[part 3 of 3: packages /ComponentTypes to /PortInterfaces]
AUTOSAR XML (schema 4-2-2)
package /ComponentTypes  (continued)
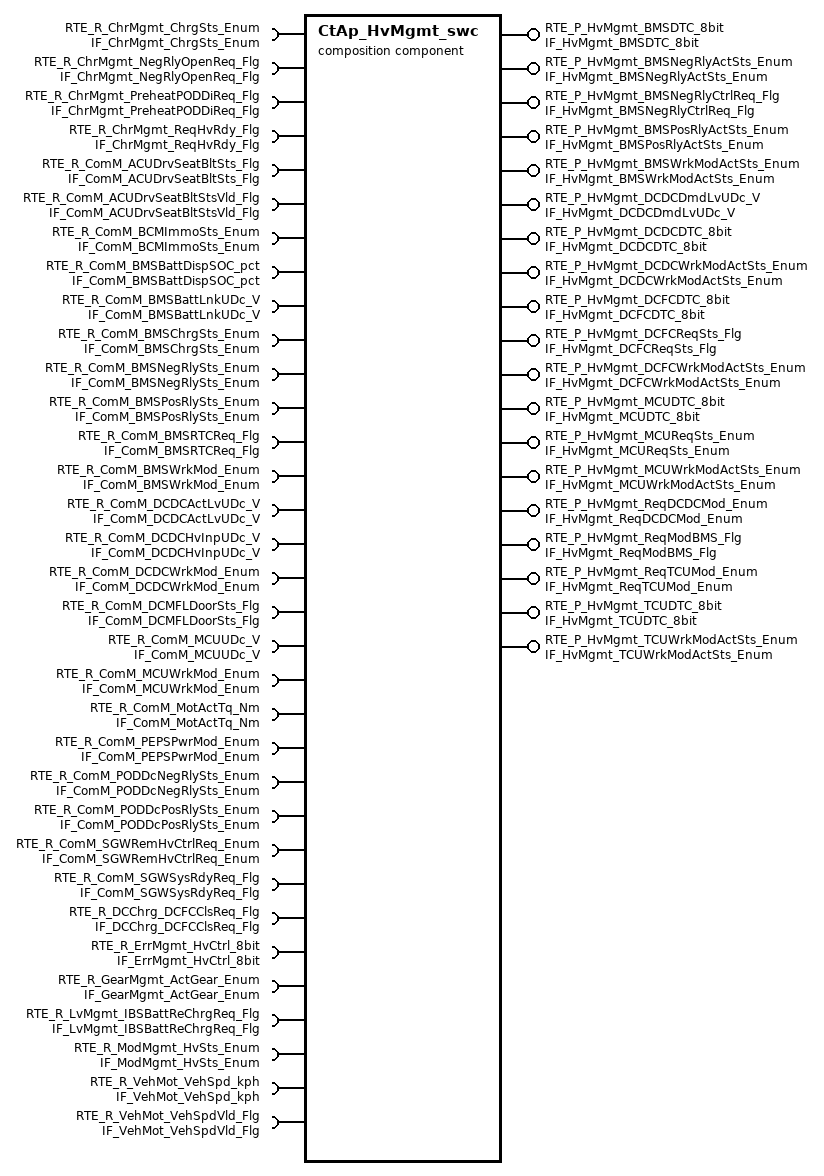
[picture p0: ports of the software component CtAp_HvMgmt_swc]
  composition sw component type CtAp_HvMgmt_swc
    19 x provide port:
      RTE_P_HvMgmt_BMSDTC_8bit: nonqueued-sender-com-spec=data-element=tec_HvMgmt_BMSDTC_8bit, provided-interface=IF_HvMgmt_BMSDTC_8bit
      RTE_P_HvMgmt_BMSNegRlyActSts_Enum: nonqueued-sender-com-spec=data-element=tec_HvMgmt_BMSNegRlyActSts_Enum, provided-interface=IF_HvMgmt_BMSNegRlyActSts_Enum
      RTE_P_HvMgmt_BMSNegRlyCtrlReq_Flg: nonqueued-sender-com-spec=data-element=tec_HvMgmt_BMSNegRlyCtrlReq_Flg, provided-interface=IF_HvMgmt_BMSNegRlyCtrlReq_Flg
      RTE_P_HvMgmt_BMSPosRlyActSts_Enum: nonqueued-sender-com-spec=data-element=tec_HvMgmt_BMSPosRlyActSts_Enum, provided-interface=IF_HvMgmt_BMSPosRlyActSts_Enum
      RTE_P_HvMgmt_BMSWrkModActSts_Enum: nonqueued-sender-com-spec=data-element=tec_HvMgmt_BMSWrkModActSts_Enum, provided-interface=IF_HvMgmt_BMSWrkModActSts_Enum
      RTE_P_HvMgmt_DCDCDmdLvUDc_V: nonqueued-sender-com-spec=data-element=tec_HvMgmt_DCDCDmdLvUDc_V, provided-interface=IF_HvMgmt_DCDCDmdLvUDc_V
      RTE_P_HvMgmt_DCDCDTC_8bit: nonqueued-sender-com-spec=data-element=tec_HvMgmt_DCDCDTC_8bit, provided-interface=IF_HvMgmt_DCDCDTC_8bit
      RTE_P_HvMgmt_DCDCWrkModActSts_Enum: nonqueued-sender-com-spec=data-element=tec_HvMgmt_DCDCWrkModActSts_Enum, provided-interface=IF_HvMgmt_DCDCWrkModActSts_Enum
      RTE_P_HvMgmt_DCFCDTC_8bit: nonqueued-sender-com-spec=data-element=tec_HvMgmt_DCFCDTC_8bit, provided-interface=IF_HvMgmt_DCFCDTC_8bit
      RTE_P_HvMgmt_DCFCReqSts_Flg: nonqueued-sender-com-spec=data-element=tec_HvMgmt_DCFCReqSts_Flg, provided-interface=IF_HvMgmt_DCFCReqSts_Flg
      RTE_P_HvMgmt_DCFCWrkModActSts_Enum: nonqueued-sender-com-spec=data-element=tec_HvMgmt_DCFCWrkModActSts_Enum, provided-interface=IF_HvMgmt_DCFCWrkModActSts_Enum
      RTE_P_HvMgmt_MCUDTC_8bit: nonqueued-sender-com-spec=data-element=tec_HvMgmt_MCUDTC_8bit, provided-interface=IF_HvMgmt_MCUDTC_8bit
      RTE_P_HvMgmt_MCUReqSts_Enum: nonqueued-sender-com-spec=data-element=tec_HvMgmt_MCUReqSts_Enum, provided-interface=IF_HvMgmt_MCUReqSts_Enum
      RTE_P_HvMgmt_MCUWrkModActSts_Enum: nonqueued-sender-com-spec=data-element=tec_HvMgmt_MCUWrkModActSts_Enum, provided-interface=IF_HvMgmt_MCUWrkModActSts_Enum
      RTE_P_HvMgmt_ReqDCDCMod_Enum: nonqueued-sender-com-spec=data-element=tec_HvMgmt_ReqDCDCMod_Enum, provided-interface=IF_HvMgmt_ReqDCDCMod_Enum
      RTE_P_HvMgmt_ReqModBMS_Flg: nonqueued-sender-com-spec=data-element=tec_HvMgmt_ReqModBMS_Flg, provided-interface=IF_HvMgmt_ReqModBMS_Flg
      RTE_P_HvMgmt_ReqTCUMod_Enum: nonqueued-sender-com-spec=data-element=tec_HvMgmt_ReqTCUMod_Enum, provided-interface=IF_HvMgmt_ReqTCUMod_Enum
      RTE_P_HvMgmt_TCUDTC_8bit: nonqueued-sender-com-spec=data-element=tec_HvMgmt_TCUDTC_8bit, provided-interface=IF_HvMgmt_TCUDTC_8bit
      RTE_P_HvMgmt_TCUWrkModActSts_Enum: nonqueued-sender-com-spec=data-element=tec_HvMgmt_TCUWrkModActSts_Enum, provided-interface=IF_HvMgmt_TCUWrkModActSts_Enum
    33 x require port:
      RTE_R_ChrMgmt_ChrgSts_Enum: nonqueued-receiver-com-spec{data-element=tec_ChrMgmt_ChrgSts_Enum, filter=data-filter-type=ALWAYS}, required-interface=IF_ChrMgmt_ChrgSts_Enum
      RTE_R_ChrMgmt_NegRlyOpenReq_Flg: nonqueued-receiver-com-spec{data-element=tec_ChrMgmt_NegRlyOpenReq_Flg, filter=data-filter-type=ALWAYS}, required-interface=IF_ChrMgmt_NegRlyOpenReq_Flg
      RTE_R_ChrMgmt_PreheatPODDiReq_Flg: nonqueued-receiver-com-spec{data-element=tec_ChrMgmt_PreheatPODDiReq_Flg, filter=data-filter-type=ALWAYS}, required-interface=IF_ChrMgmt_PreheatPODDiReq_Flg
      RTE_R_ChrMgmt_ReqHvRdy_Flg: nonqueued-receiver-com-spec{data-element=tec_ChrMgmt_ReqHvRdy_Flg, filter=data-filter-type=ALWAYS}, required-interface=IF_ChrMgmt_ReqHvRdy_Flg
      RTE_R_ComM_ACUDrvSeatBltSts_Flg: nonqueued-receiver-com-spec{data-element=tec_ComM_ACUDrvSeatBltSts_Flg, filter=data-filter-type=ALWAYS}, required-interface=IF_ComM_ACUDrvSeatBltSts_Flg
      RTE_R_ComM_ACUDrvSeatBltStsVld_Flg: nonqueued-receiver-com-spec{data-element=tec_ComM_ACUDrvSeatBltStsVld_Flg, filter=data-filter-type=ALWAYS}, required-interface=IF_ComM_ACUDrvSeatBltStsVld_Flg
      RTE_R_ComM_BCMImmoSts_Enum: nonqueued-receiver-com-spec{data-element=tec_ComM_BCMImmoSts_Enum, filter=data-filter-type=ALWAYS}, required-interface=IF_ComM_BCMImmoSts_Enum
      RTE_R_ComM_BMSBattDispSOC_pct: nonqueued-receiver-com-spec{data-element=tec_ComM_BMSBattDispSOC_pct, filter=data-filter-type=ALWAYS}, required-interface=IF_ComM_BMSBattDispSOC_pct
      RTE_R_ComM_BMSBattLnkUDc_V: nonqueued-receiver-com-spec{data-element=tec_ComM_BMSBattLnkUDc_V, filter=data-filter-type=ALWAYS}, required-interface=IF_ComM_BMSBattLnkUDc_V
      RTE_R_ComM_BMSChrgSts_Enum: nonqueued-receiver-com-spec{data-element=tec_ComM_BMSChrgSts_Enum, filter=data-filter-type=ALWAYS}, required-interface=IF_ComM_BMSChrgSts_Enum
      RTE_R_ComM_BMSNegRlySts_Enum: nonqueued-receiver-com-spec{data-element=tec_ComM_BMSNegRlySts_Enum, filter=data-filter-type=ALWAYS}, required-interface=IF_ComM_BMSNegRlySts_Enum
      RTE_R_ComM_BMSPosRlySts_Enum: nonqueued-receiver-com-spec{data-element=tec_ComM_BMSPosRlySts_Enum, filter=data-filter-type=ALWAYS}, required-interface=IF_ComM_BMSPosRlySts_Enum
      RTE_R_ComM_BMSRTCReq_Flg: nonqueued-receiver-com-spec{data-element=tec_ComM_BMSRTCReq_Flg, filter=data-filter-type=ALWAYS}, required-interface=IF_ComM_BMSRTCReq_Flg
      RTE_R_ComM_BMSWrkMod_Enum: nonqueued-receiver-com-spec{data-element=tec_ComM_BMSWrkMod_Enum, filter=data-filter-type=ALWAYS}, required-interface=IF_ComM_BMSWrkMod_Enum
      RTE_R_ComM_DCDCActLvUDc_V: nonqueued-receiver-com-spec{data-element=tec_ComM_DCDCActLvUDc_V, filter=data-filter-type=ALWAYS}, required-interface=IF_ComM_DCDCActLvUDc_V
      RTE_R_ComM_DCDCHvInpUDc_V: nonqueued-receiver-com-spec{data-element=tec_ComM_DCDCHvInpUDc_V, filter=data-filter-type=ALWAYS}, required-interface=IF_ComM_DCDCHvInpUDc_V
      RTE_R_ComM_DCDCWrkMod_Enum: nonqueued-receiver-com-spec{data-element=tec_ComM_DCDCWrkMod_Enum, filter=data-filter-type=ALWAYS}, required-interface=IF_ComM_DCDCWrkMod_Enum
      RTE_R_ComM_DCMFLDoorSts_Flg: nonqueued-receiver-com-spec{data-element=tec_ComM_DCMFLDoorSts_Flg, filter=data-filter-type=ALWAYS}, required-interface=IF_ComM_DCMFLDoorSts_Flg
      RTE_R_ComM_MCUUDc_V: nonqueued-receiver-com-spec{data-element=tec_ComM_MCUUDc_V, filter=data-filter-type=ALWAYS}, required-interface=IF_ComM_MCUUDc_V
      RTE_R_ComM_MCUWrkMod_Enum: nonqueued-receiver-com-spec{data-element=tec_ComM_MCUWrkMod_Enum, filter=data-filter-type=ALWAYS}, required-interface=IF_ComM_MCUWrkMod_Enum
      RTE_R_ComM_MotActTq_Nm: nonqueued-receiver-com-spec{data-element=tec_ComM_MotActTq_Nm, filter=data-filter-type=ALWAYS}, required-interface=IF_ComM_MotActTq_Nm
      RTE_R_ComM_PEPSPwrMod_Enum: nonqueued-receiver-com-spec{data-element=tec_ComM_PEPSPwrMod_Enum, filter=data-filter-type=ALWAYS}, required-interface=IF_ComM_PEPSPwrMod_Enum
      RTE_R_ComM_PODDcNegRlySts_Enum: nonqueued-receiver-com-spec{data-element=tec_ComM_PODDcNegRlySts_Enum, filter=data-filter-type=ALWAYS}, required-interface=IF_ComM_PODDcNegRlySts_Enum
      RTE_R_ComM_PODDcPosRlySts_Enum: nonqueued-receiver-com-spec{data-element=tec_ComM_PODDcPosRlySts_Enum, filter=data-filter-type=ALWAYS}, required-interface=IF_ComM_PODDcPosRlySts_Enum
      RTE_R_ComM_SGWRemHvCtrlReq_Enum: nonqueued-receiver-com-spec{data-element=tec_ComM_SGWRemHvCtrlReq_Enum, filter=data-filter-type=ALWAYS}, required-interface=IF_ComM_SGWRemHvCtrlReq_Enum
      RTE_R_ComM_SGWSysRdyReq_Flg: nonqueued-receiver-com-spec{data-element=tec_ComM_SGWSysRdyReq_Flg, filter=data-filter-type=ALWAYS}, required-interface=IF_ComM_SGWSysRdyReq_Flg
      RTE_R_DCChrg_DCFCClsReq_Flg: nonqueued-receiver-com-spec{data-element=tec_DCChrg_DCFCClsReq_Flg, filter=data-filter-type=ALWAYS}, required-interface=IF_DCChrg_DCFCClsReq_Flg
      RTE_R_ErrMgmt_HvCtrl_8bit: nonqueued-receiver-com-spec{data-element=tec_ErrMgmt_HvCtrl_8bit, filter=data-filter-type=ALWAYS}, required-interface=IF_ErrMgmt_HvCtrl_8bit
      RTE_R_GearMgmt_ActGear_Enum: nonqueued-receiver-com-spec{data-element=tec_GearMgmt_ActGear_Enum, filter=data-filter-type=ALWAYS}, required-interface=IF_GearMgmt_ActGear_Enum
      RTE_R_LvMgmt_IBSBattReChrgReq_Flg: nonqueued-receiver-com-spec{data-element=tec_LvMgmt_IBSBattReChrgReq_Flg, filter=data-filter-type=ALWAYS}, required-interface=IF_LvMgmt_IBSBattReChrgReq_Flg
      RTE_R_ModMgmt_HvSts_Enum: nonqueued-receiver-com-spec{data-element=tec_ModMgmt_HvSts_Enum, filter=data-filter-type=ALWAYS}, required-interface=IF_ModMgmt_HvSts_Enum
      RTE_R_VehMot_VehSpd_kph: nonqueued-receiver-com-spec{data-element=tec_VehMot_VehSpd_kph, filter=data-filter-type=ALWAYS}, required-interface=IF_VehMot_VehSpd_kph
      RTE_R_VehMot_VehSpdVld_Flg: nonqueued-receiver-com-spec{data-element=tec_VehMot_VehSpdVld_Flg, filter=data-filter-type=ALWAYS}, required-interface=IF_VehMot_VehSpdVld_Flg
    5 x component:
      CtAp_BMSMgmt: type=CtAp_BMSMgmt
      CtAp_DCDCMgmt: type=CtAp_DCDCMgmt
      CtAp_DCFCMgmt: type=CtAp_DCFCMgmt
      CtAp_MCUMgmt: type=CtAp_MCUMgmt
      CtAp_TCUMgmt: type=CtAp_TCUMgmt
    connect CtAp_BMSMgmt.RTE_P_HvMgmt_BMSNormHvDwnReq_Flg -> CtAp_DCDCMgmt.RTE_R_HvMgmt_BMSNormHvDwnReq_Flg
    connect CtAp_BMSMgmt.RTE_P_HvMgmt_BMSWrkModActSts_Enum -> CtAp_MCUMgmt.RTE_R_HvMgmt_BMSWrkModActSts_Enum
    connect CtAp_BMSMgmt.RTE_P_HvMgmt_BMSNormHvDwnReq_Flg -> CtAp_TCUMgmt.RTE_R_HvMgmt_BMSNormHvDwnReq_Flg
    connect CtAp_DCDCMgmt.RTE_P_HvMgmt_DCDCWrkModActSts_Enum -> CtAp_TCUMgmt.RTE_R_HvMgmt_DCDCWrkModActSts_Enum
    connect CtAp_TCUMgmt.RTE_P_HvMgmt_TCUWrkModActSts_Enum -> CtAp_BMSMgmt.RTE_R_HvMgmt_TCUWrkModActSts_Enum
    delegate CtAp_BMSMgmt.RTE_P_HvMgmt_BMSDTC_8bit <-> outer port CtAp_HvMgmt_swc/RTE_P_HvMgmt_BMSDTC_8bit
    delegate CtAp_BMSMgmt.RTE_P_HvMgmt_BMSNegRlyActSts_Enum <-> outer port CtAp_HvMgmt_swc/RTE_P_HvMgmt_BMSNegRlyActSts_Enum
    delegate CtAp_BMSMgmt.RTE_P_HvMgmt_BMSNegRlyCtrlReq_Flg <-> outer port CtAp_HvMgmt_swc/RTE_P_HvMgmt_BMSNegRlyCtrlReq_Flg
    delegate CtAp_BMSMgmt.RTE_P_HvMgmt_BMSPosRlyActSts_Enum <-> outer port CtAp_HvMgmt_swc/RTE_P_HvMgmt_BMSPosRlyActSts_Enum
    delegate CtAp_BMSMgmt.RTE_P_HvMgmt_BMSWrkModActSts_Enum <-> outer port CtAp_HvMgmt_swc/RTE_P_HvMgmt_BMSWrkModActSts_Enum
    delegate CtAp_DCDCMgmt.RTE_P_HvMgmt_DCDCDmdLvUDc_V <-> outer port CtAp_HvMgmt_swc/RTE_P_HvMgmt_DCDCDmdLvUDc_V
    delegate CtAp_DCDCMgmt.RTE_P_HvMgmt_DCDCDTC_8bit <-> outer port CtAp_HvMgmt_swc/RTE_P_HvMgmt_DCDCDTC_8bit
    delegate CtAp_DCDCMgmt.RTE_P_HvMgmt_DCDCWrkModActSts_Enum <-> outer port CtAp_HvMgmt_swc/RTE_P_HvMgmt_DCDCWrkModActSts_Enum
    delegate CtAp_DCFCMgmt.RTE_P_HvMgmt_DCFCDTC_8bit <-> outer port CtAp_HvMgmt_swc/RTE_P_HvMgmt_DCFCDTC_8bit
    delegate CtAp_DCFCMgmt.RTE_P_HvMgmt_DCFCReqSts_Flg <-> outer port CtAp_HvMgmt_swc/RTE_P_HvMgmt_DCFCReqSts_Flg
    delegate CtAp_DCFCMgmt.RTE_P_HvMgmt_DCFCWrkModActSts_Enum <-> outer port CtAp_HvMgmt_swc/RTE_P_HvMgmt_DCFCWrkModActSts_Enum
    delegate CtAp_MCUMgmt.RTE_P_HvMgmt_MCUDTC_8bit <-> outer port CtAp_HvMgmt_swc/RTE_P_HvMgmt_MCUDTC_8bit
    delegate CtAp_MCUMgmt.RTE_P_HvMgmt_MCUReqSts_Enum <-> outer port CtAp_HvMgmt_swc/RTE_P_HvMgmt_MCUReqSts_Enum
    delegate CtAp_MCUMgmt.RTE_P_HvMgmt_MCUWrkModActSts_Enum <-> outer port CtAp_HvMgmt_swc/RTE_P_HvMgmt_MCUWrkModActSts_Enum
    delegate CtAp_DCDCMgmt.RTE_P_HvMgmt_ReqDCDCMod_Enum <-> outer port CtAp_HvMgmt_swc/RTE_P_HvMgmt_ReqDCDCMod_Enum
    delegate CtAp_BMSMgmt.RTE_P_HvMgmt_ReqModBMS_Flg <-> outer port CtAp_HvMgmt_swc/RTE_P_HvMgmt_ReqModBMS_Flg
    delegate CtAp_TCUMgmt.RTE_P_HvMgmt_ReqTCUMod_Enum <-> outer port CtAp_HvMgmt_swc/RTE_P_HvMgmt_ReqTCUMod_Enum
    delegate CtAp_TCUMgmt.RTE_P_HvMgmt_TCUDTC_8bit <-> outer port CtAp_HvMgmt_swc/RTE_P_HvMgmt_TCUDTC_8bit
    delegate CtAp_TCUMgmt.RTE_P_HvMgmt_TCUWrkModActSts_Enum <-> outer port CtAp_HvMgmt_swc/RTE_P_HvMgmt_TCUWrkModActSts_Enum
    delegate CtAp_BMSMgmt.RTE_R_ChrMgmt_ChrgSts_Enum <-> outer port CtAp_HvMgmt_swc/RTE_R_ChrMgmt_ChrgSts_Enum
    delegate CtAp_DCDCMgmt.RTE_R_ChrMgmt_ChrgSts_Enum <-> outer port CtAp_HvMgmt_swc/RTE_R_ChrMgmt_ChrgSts_Enum
    delegate CtAp_MCUMgmt.RTE_R_ChrMgmt_ChrgSts_Enum <-> outer port CtAp_HvMgmt_swc/RTE_R_ChrMgmt_ChrgSts_Enum
    delegate CtAp_BMSMgmt.RTE_R_ChrMgmt_NegRlyOpenReq_Flg <-> outer port CtAp_HvMgmt_swc/RTE_R_ChrMgmt_NegRlyOpenReq_Flg
    delegate CtAp_DCDCMgmt.RTE_R_ChrMgmt_PreheatPODDiReq_Flg <-> outer port CtAp_HvMgmt_swc/RTE_R_ChrMgmt_PreheatPODDiReq_Flg
    delegate CtAp_BMSMgmt.RTE_R_ChrMgmt_ReqHvRdy_Flg <-> outer port CtAp_HvMgmt_swc/RTE_R_ChrMgmt_ReqHvRdy_Flg
    delegate CtAp_MCUMgmt.RTE_R_ComM_ACUDrvSeatBltSts_Flg <-> outer port CtAp_HvMgmt_swc/RTE_R_ComM_ACUDrvSeatBltSts_Flg
    delegate CtAp_MCUMgmt.RTE_R_ComM_ACUDrvSeatBltStsVld_Flg <-> outer port CtAp_HvMgmt_swc/RTE_R_ComM_ACUDrvSeatBltStsVld_Flg
    delegate CtAp_MCUMgmt.RTE_R_ComM_BCMImmoSts_Enum <-> outer port CtAp_HvMgmt_swc/RTE_R_ComM_BCMImmoSts_Enum
    delegate CtAp_BMSMgmt.RTE_R_ComM_BMSBattDispSOC_pct <-> outer port CtAp_HvMgmt_swc/RTE_R_ComM_BMSBattDispSOC_pct
    delegate CtAp_BMSMgmt.RTE_R_ComM_BMSBattLnkUDc_V <-> outer port CtAp_HvMgmt_swc/RTE_R_ComM_BMSBattLnkUDc_V
    delegate CtAp_DCDCMgmt.RTE_R_ComM_BMSBattLnkUDc_V <-> outer port CtAp_HvMgmt_swc/RTE_R_ComM_BMSBattLnkUDc_V
    delegate CtAp_DCDCMgmt.RTE_R_ComM_BMSChrgSts_Enum <-> outer port CtAp_HvMgmt_swc/RTE_R_ComM_BMSChrgSts_Enum
    delegate CtAp_BMSMgmt.RTE_R_ComM_BMSNegRlySts_Enum <-> outer port CtAp_HvMgmt_swc/RTE_R_ComM_BMSNegRlySts_Enum
    delegate CtAp_BMSMgmt.RTE_R_ComM_BMSPosRlySts_Enum <-> outer port CtAp_HvMgmt_swc/RTE_R_ComM_BMSPosRlySts_Enum
    delegate CtAp_BMSMgmt.RTE_R_ComM_BMSRTCReq_Flg <-> outer port CtAp_HvMgmt_swc/RTE_R_ComM_BMSRTCReq_Flg
    delegate CtAp_BMSMgmt.RTE_R_ComM_BMSWrkMod_Enum <-> outer port CtAp_HvMgmt_swc/RTE_R_ComM_BMSWrkMod_Enum
    delegate CtAp_DCDCMgmt.RTE_R_ComM_DCDCActLvUDc_V <-> outer port CtAp_HvMgmt_swc/RTE_R_ComM_DCDCActLvUDc_V
    delegate CtAp_BMSMgmt.RTE_R_ComM_DCDCHvInpUDc_V <-> outer port CtAp_HvMgmt_swc/RTE_R_ComM_DCDCHvInpUDc_V
    delegate CtAp_DCDCMgmt.RTE_R_ComM_DCDCHvInpUDc_V <-> outer port CtAp_HvMgmt_swc/RTE_R_ComM_DCDCHvInpUDc_V
    delegate CtAp_DCDCMgmt.RTE_R_ComM_DCDCWrkMod_Enum <-> outer port CtAp_HvMgmt_swc/RTE_R_ComM_DCDCWrkMod_Enum
    delegate CtAp_MCUMgmt.RTE_R_ComM_DCMFLDoorSts_Flg <-> outer port CtAp_HvMgmt_swc/RTE_R_ComM_DCMFLDoorSts_Flg
    delegate CtAp_BMSMgmt.RTE_R_ComM_MCUUDc_V <-> outer port CtAp_HvMgmt_swc/RTE_R_ComM_MCUUDc_V
    delegate CtAp_MCUMgmt.RTE_R_ComM_MCUWrkMod_Enum <-> outer port CtAp_HvMgmt_swc/RTE_R_ComM_MCUWrkMod_Enum
    delegate CtAp_TCUMgmt.RTE_R_ComM_MotActTq_Nm <-> outer port CtAp_HvMgmt_swc/RTE_R_ComM_MotActTq_Nm
    delegate CtAp_BMSMgmt.RTE_R_ComM_PEPSPwrMod_Enum <-> outer port CtAp_HvMgmt_swc/RTE_R_ComM_PEPSPwrMod_Enum
    delegate CtAp_MCUMgmt.RTE_R_ComM_PEPSPwrMod_Enum <-> outer port CtAp_HvMgmt_swc/RTE_R_ComM_PEPSPwrMod_Enum
    delegate CtAp_DCFCMgmt.RTE_R_ComM_PODDcNegRlySts_Enum <-> outer port CtAp_HvMgmt_swc/RTE_R_ComM_PODDcNegRlySts_Enum
    delegate CtAp_DCFCMgmt.RTE_R_ComM_PODDcPosRlySts_Enum <-> outer port CtAp_HvMgmt_swc/RTE_R_ComM_PODDcPosRlySts_Enum
    delegate CtAp_BMSMgmt.RTE_R_ComM_SGWRemHvCtrlReq_Enum <-> outer port CtAp_HvMgmt_swc/RTE_R_ComM_SGWRemHvCtrlReq_Enum
    delegate CtAp_MCUMgmt.RTE_R_ComM_SGWSysRdyReq_Flg <-> outer port CtAp_HvMgmt_swc/RTE_R_ComM_SGWSysRdyReq_Flg
    delegate CtAp_DCFCMgmt.RTE_R_DCChrg_DCFCClsReq_Flg <-> outer port CtAp_HvMgmt_swc/RTE_R_DCChrg_DCFCClsReq_Flg
    delegate CtAp_BMSMgmt.RTE_R_ErrMgmt_HvCtrl_8bit <-> outer port CtAp_HvMgmt_swc/RTE_R_ErrMgmt_HvCtrl_8bit
    delegate CtAp_DCDCMgmt.RTE_R_ErrMgmt_HvCtrl_8bit <-> outer port CtAp_HvMgmt_swc/RTE_R_ErrMgmt_HvCtrl_8bit
    delegate CtAp_MCUMgmt.RTE_R_ErrMgmt_HvCtrl_8bit <-> outer port CtAp_HvMgmt_swc/RTE_R_ErrMgmt_HvCtrl_8bit
    delegate CtAp_TCUMgmt.RTE_R_ErrMgmt_HvCtrl_8bit <-> outer port CtAp_HvMgmt_swc/RTE_R_ErrMgmt_HvCtrl_8bit
    delegate CtAp_BMSMgmt.RTE_R_GearMgmt_ActGear_Enum <-> outer port CtAp_HvMgmt_swc/RTE_R_GearMgmt_ActGear_Enum
    delegate CtAp_MCUMgmt.RTE_R_GearMgmt_ActGear_Enum <-> outer port CtAp_HvMgmt_swc/RTE_R_GearMgmt_ActGear_Enum
    delegate CtAp_BMSMgmt.RTE_R_LvMgmt_IBSBattReChrgReq_Flg <-> outer port CtAp_HvMgmt_swc/RTE_R_LvMgmt_IBSBattReChrgReq_Flg
    delegate CtAp_BMSMgmt.RTE_R_ModMgmt_HvSts_Enum <-> outer port CtAp_HvMgmt_swc/RTE_R_ModMgmt_HvSts_Enum
    delegate CtAp_DCDCMgmt.RTE_R_ModMgmt_HvSts_Enum <-> outer port CtAp_HvMgmt_swc/RTE_R_ModMgmt_HvSts_Enum
    delegate CtAp_MCUMgmt.RTE_R_ModMgmt_HvSts_Enum <-> outer port CtAp_HvMgmt_swc/RTE_R_ModMgmt_HvSts_Enum
    delegate CtAp_TCUMgmt.RTE_R_ModMgmt_HvSts_Enum <-> outer port CtAp_HvMgmt_swc/RTE_R_ModMgmt_HvSts_Enum
    delegate CtAp_BMSMgmt.RTE_R_VehMot_VehSpd_kph <-> outer port CtAp_HvMgmt_swc/RTE_R_VehMot_VehSpd_kph
    delegate CtAp_BMSMgmt.RTE_R_VehMot_VehSpdVld_Flg <-> outer port CtAp_HvMgmt_swc/RTE_R_VehMot_VehSpdVld_Flg
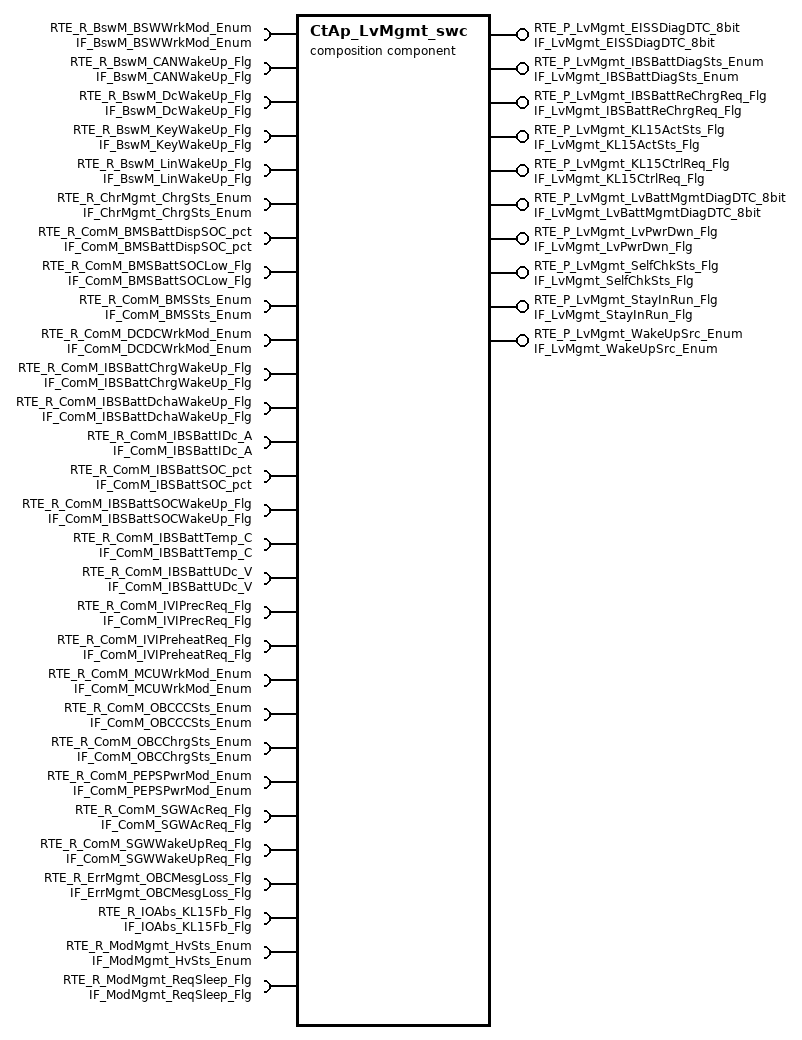
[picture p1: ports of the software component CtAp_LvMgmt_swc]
  composition sw component type CtAp_LvMgmt_swc
    10 x provide port:
      RTE_P_LvMgmt_EISSDiagDTC_8bit: nonqueued-sender-com-spec{data-element=tec_LvMgmt_EISSDiagDTC_8bit, init-value=0}, provided-interface=IF_LvMgmt_EISSDiagDTC_8bit
      RTE_P_LvMgmt_IBSBattDiagSts_Enum: nonqueued-sender-com-spec{data-element=tec_LvMgmt_IBSBattDiagSts_Enum, init-value=0}, provided-interface=IF_LvMgmt_IBSBattDiagSts_Enum
      RTE_P_LvMgmt_IBSBattReChrgReq_Flg: nonqueued-sender-com-spec{data-element=tec_LvMgmt_IBSBattReChrgReq_Flg, init-value=0}, provided-interface=IF_LvMgmt_IBSBattReChrgReq_Flg
      RTE_P_LvMgmt_KL15ActSts_Flg: nonqueued-sender-com-spec{data-element=tec_LvMgmt_KL15ActSts_Flg, init-value=0}, provided-interface=IF_LvMgmt_KL15ActSts_Flg
      RTE_P_LvMgmt_KL15CtrlReq_Flg: nonqueued-sender-com-spec{data-element=tec_LvMgmt_KL15CtrlReq_Flg, init-value=0}, provided-interface=IF_LvMgmt_KL15CtrlReq_Flg
      RTE_P_LvMgmt_LvBattMgmtDiagDTC_8bit: nonqueued-sender-com-spec{data-element=tec_LvMgmt_LvBattMgmtDiagDTC_8bit, init-value=0}, provided-interface=IF_LvMgmt_LvBattMgmtDiagDTC_8bit
      RTE_P_LvMgmt_LvPwrDwn_Flg: nonqueued-sender-com-spec{data-element=tec_LvMgmt_LvPwrDwn_Flg, init-value=0}, provided-interface=IF_LvMgmt_LvPwrDwn_Flg
      RTE_P_LvMgmt_SelfChkSts_Flg: nonqueued-sender-com-spec{data-element=tec_LvMgmt_SelfChkSts_Flg, init-value=0}, provided-interface=IF_LvMgmt_SelfChkSts_Flg
      RTE_P_LvMgmt_StayInRun_Flg: nonqueued-sender-com-spec{data-element=tec_LvMgmt_StayInRun_Flg, init-value=0}, provided-interface=IF_LvMgmt_StayInRun_Flg
      RTE_P_LvMgmt_WakeUpSrc_Enum: nonqueued-sender-com-spec{data-element=tec_LvMgmt_WakeUpSrc_Enum, init-value=0}, provided-interface=IF_LvMgmt_WakeUpSrc_Enum
    29 x require port:
      RTE_R_BswM_BSWWrkMod_Enum: nonqueued-receiver-com-spec{data-element=tec_BswM_BSWWrkMod_Enum, filter=data-filter-type=ALWAYS, init-value=0}, required-interface=IF_BswM_BSWWrkMod_Enum
      RTE_R_BswM_CANWakeUp_Flg: nonqueued-receiver-com-spec{data-element=tec_BswM_CANWakeUp_Flg, filter=data-filter-type=ALWAYS, init-value=0}, required-interface=IF_BswM_CANWakeUp_Flg
      RTE_R_BswM_DcWakeUp_Flg: nonqueued-receiver-com-spec{data-element=tec_BswM_DcWakeUp_Flg, filter=data-filter-type=ALWAYS, init-value=0}, required-interface=IF_BswM_DcWakeUp_Flg
      RTE_R_BswM_KeyWakeUp_Flg: nonqueued-receiver-com-spec{data-element=tec_BswM_KeyWakeUp_Flg, filter=data-filter-type=ALWAYS, init-value=0}, required-interface=IF_BswM_KeyWakeUp_Flg
      RTE_R_BswM_LinWakeUp_Flg: nonqueued-receiver-com-spec{data-element=tec_BswM_LinWakeUp_Flg, filter=data-filter-type=ALWAYS, init-value=0}, required-interface=IF_BswM_LinWakeUp_Flg
      RTE_R_ChrMgmt_ChrgSts_Enum: nonqueued-receiver-com-spec{data-element=tec_ChrMgmt_ChrgSts_Enum, filter=data-filter-type=ALWAYS, init-value=0}, required-interface=IF_ChrMgmt_ChrgSts_Enum
      RTE_R_ComM_BMSBattDispSOC_pct: nonqueued-receiver-com-spec{data-element=tec_ComM_BMSBattDispSOC_pct, filter=data-filter-type=ALWAYS, init-value=0}, required-interface=IF_ComM_BMSBattDispSOC_pct
      RTE_R_ComM_BMSBattSOCLow_Flg: nonqueued-receiver-com-spec{data-element=tec_ComM_BMSBattSOCLow_Flg, filter=data-filter-type=ALWAYS, init-value=0}, required-interface=IF_ComM_BMSBattSOCLow_Flg
      RTE_R_ComM_BMSSts_Enum: nonqueued-receiver-com-spec{data-element=tec_ComM_BMSSts_Enum, filter=data-filter-type=ALWAYS, init-value=0}, required-interface=IF_ComM_BMSSts_Enum
      RTE_R_ComM_DCDCWrkMod_Enum: nonqueued-receiver-com-spec{data-element=tec_ComM_DCDCWrkMod_Enum, filter=data-filter-type=ALWAYS, init-value=0}, required-interface=IF_ComM_DCDCWrkMod_Enum
      RTE_R_ComM_IBSBattChrgWakeUp_Flg: nonqueued-receiver-com-spec{data-element=tec_ComM_IBSBattChrgWakeUp_Flg, filter=data-filter-type=ALWAYS, init-value=0}, required-interface=IF_ComM_IBSBattChrgWakeUp_Flg
      RTE_R_ComM_IBSBattDchaWakeUp_Flg: nonqueued-receiver-com-spec{data-element=tec_ComM_IBSBattDchaWakeUp_Flg, filter=data-filter-type=ALWAYS, init-value=0}, required-interface=IF_ComM_IBSBattDchaWakeUp_Flg
      RTE_R_ComM_IBSBattIDc_A: nonqueued-receiver-com-spec{data-element=tec_ComM_IBSBattIDc_A, filter=data-filter-type=ALWAYS, init-value=0}, required-interface=IF_ComM_IBSBattIDc_A
      RTE_R_ComM_IBSBattSOC_pct: nonqueued-receiver-com-spec{data-element=tec_ComM_IBSBattSOC_pct, filter=data-filter-type=ALWAYS, init-value=0}, required-interface=IF_ComM_IBSBattSOC_pct
      RTE_R_ComM_IBSBattSOCWakeUp_Flg: nonqueued-receiver-com-spec{data-element=tec_ComM_IBSBattSOCWakeUp_Flg, filter=data-filter-type=ALWAYS, init-value=0}, required-interface=IF_ComM_IBSBattSOCWakeUp_Flg
      RTE_R_ComM_IBSBattTemp_C: nonqueued-receiver-com-spec{data-element=tec_ComM_IBSBattTemp_C, filter=data-filter-type=ALWAYS, init-value=0}, required-interface=IF_ComM_IBSBattTemp_C
      RTE_R_ComM_IBSBattUDc_V: nonqueued-receiver-com-spec{data-element=tec_ComM_IBSBattUDc_V, filter=data-filter-type=ALWAYS, init-value=0}, required-interface=IF_ComM_IBSBattUDc_V
      RTE_R_ComM_IVIPrecReq_Flg: nonqueued-receiver-com-spec{data-element=tec_ComM_IVIPrecReq_Flg, filter=data-filter-type=ALWAYS, init-value=0}, required-interface=IF_ComM_IVIPrecReq_Flg
      RTE_R_ComM_IVIPreheatReq_Flg: nonqueued-receiver-com-spec{data-element=tec_ComM_IVIPreheatReq_Flg, filter=data-filter-type=ALWAYS, init-value=0}, required-interface=IF_ComM_IVIPreheatReq_Flg
      RTE_R_ComM_MCUWrkMod_Enum: nonqueued-receiver-com-spec{data-element=tec_ComM_MCUWrkMod_Enum, filter=data-filter-type=ALWAYS, init-value=0}, required-interface=IF_ComM_MCUWrkMod_Enum
      RTE_R_ComM_OBCCCSts_Enum: nonqueued-receiver-com-spec{data-element=tec_ComM_OBCCCSts_Enum, filter=data-filter-type=ALWAYS, init-value=0}, required-interface=IF_ComM_OBCCCSts_Enum
      RTE_R_ComM_OBCChrgSts_Enum: nonqueued-receiver-com-spec{data-element=tec_ComM_OBCChrgSts_Enum, filter=data-filter-type=ALWAYS, init-value=0}, required-interface=IF_ComM_OBCChrgSts_Enum
      RTE_R_ComM_PEPSPwrMod_Enum: nonqueued-receiver-com-spec{data-element=tec_ComM_PEPSPwrMod_Enum, filter=data-filter-type=ALWAYS, init-value=0}, required-interface=IF_ComM_PEPSPwrMod_Enum
      RTE_R_ComM_SGWAcReq_Flg: nonqueued-receiver-com-spec{data-element=tec_ComM_SGWAcReq_Flg, filter=data-filter-type=ALWAYS, init-value=0}, required-interface=IF_ComM_SGWAcReq_Flg
      RTE_R_ComM_SGWWakeUpReq_Flg: nonqueued-receiver-com-spec{data-element=tec_ComM_SGWWakeUpReq_Flg, filter=data-filter-type=ALWAYS, init-value=0}, required-interface=IF_ComM_SGWWakeUpReq_Flg
      RTE_R_ErrMgmt_OBCMesgLoss_Flg: nonqueued-receiver-com-spec{data-element=tec_ErrMgmt_OBCMesgLoss_Flg, filter=data-filter-type=ALWAYS, init-value=0}, required-interface=IF_ErrMgmt_OBCMesgLoss_Flg
      RTE_R_IOAbs_KL15Fb_Flg: nonqueued-receiver-com-spec{data-element=tec_IOAbs_KL15Fb_Flg, filter=data-filter-type=ALWAYS, init-value=0}, required-interface=IF_IOAbs_KL15Fb_Flg
      RTE_R_ModMgmt_HvSts_Enum: nonqueued-receiver-com-spec{data-element=tec_ModMgmt_HvSts_Enum, filter=data-filter-type=ALWAYS, init-value=0}, required-interface=IF_ModMgmt_HvSts_Enum
      RTE_R_ModMgmt_ReqSleep_Flg: nonqueued-receiver-com-spec{data-element=tec_ModMgmt_ReqSleep_Flg, filter=data-filter-type=ALWAYS, init-value=0}, required-interface=IF_ModMgmt_ReqSleep_Flg
    component CtAp_ElSSDiag: type=CtAp_ElSSDiag
    component CtAp_LvBattMgmt: type=CtAp_LvBattMgmt
    component CtAp_WakeUpRsn: type=CtAp_WakeUpRsn
    connect CtAp_WakeUpRsn.RTE_P_LvMgmt_WakeUpReq_Flg -> CtAp_ElSSDiag.RTE_R_LvMgmt_WakeUpReq_Flg
    delegate CtAp_ElSSDiag.RTE_P_LvMgmt_EISSDiagDTC_8bit <-> outer port CtAp_LvMgmt_swc/RTE_P_LvMgmt_EISSDiagDTC_8bit
    delegate CtAp_LvBattMgmt.RTE_P_LvMgmt_IBSBattDiagSts_Enum <-> outer port CtAp_LvMgmt_swc/RTE_P_LvMgmt_IBSBattDiagSts_Enum
    delegate CtAp_LvBattMgmt.RTE_P_LvMgmt_IBSBattReChrgReq_Flg <-> outer port CtAp_LvMgmt_swc/RTE_P_LvMgmt_IBSBattReChrgReq_Flg
    delegate CtAp_ElSSDiag.RTE_P_LvMgmt_KL15ActSts_Flg <-> outer port CtAp_LvMgmt_swc/RTE_P_LvMgmt_KL15ActSts_Flg
    delegate CtAp_ElSSDiag.RTE_P_LvMgmt_KL15CtrlReq_Flg <-> outer port CtAp_LvMgmt_swc/RTE_P_LvMgmt_KL15CtrlReq_Flg
    delegate CtAp_LvBattMgmt.RTE_P_LvMgmt_LvBattMgmtDiagDTC_8bit <-> outer port CtAp_LvMgmt_swc/RTE_P_LvMgmt_LvBattMgmtDiagDTC_8bit
    delegate CtAp_ElSSDiag.RTE_P_LvMgmt_LvPwrDwn_Flg <-> outer port CtAp_LvMgmt_swc/RTE_P_LvMgmt_LvPwrDwn_Flg
    delegate CtAp_ElSSDiag.RTE_P_LvMgmt_SelfChkSts_Flg <-> outer port CtAp_LvMgmt_swc/RTE_P_LvMgmt_SelfChkSts_Flg
    delegate CtAp_ElSSDiag.RTE_P_LvMgmt_StayInRun_Flg <-> outer port CtAp_LvMgmt_swc/RTE_P_LvMgmt_StayInRun_Flg
    delegate CtAp_WakeUpRsn.RTE_P_LvMgmt_WakeUpSrc_Enum <-> outer port CtAp_LvMgmt_swc/RTE_P_LvMgmt_WakeUpSrc_Enum
    delegate CtAp_ElSSDiag.RTE_R_BswM_BSWWrkMod_Enum <-> outer port CtAp_LvMgmt_swc/RTE_R_BswM_BSWWrkMod_Enum
    delegate CtAp_ElSSDiag.RTE_R_BswM_CANWakeUp_Flg <-> outer port CtAp_LvMgmt_swc/RTE_R_BswM_CANWakeUp_Flg
    delegate CtAp_WakeUpRsn.RTE_R_BswM_CANWakeUp_Flg <-> outer port CtAp_LvMgmt_swc/RTE_R_BswM_CANWakeUp_Flg
    delegate CtAp_WakeUpRsn.RTE_R_BswM_DcWakeUp_Flg <-> outer port CtAp_LvMgmt_swc/RTE_R_BswM_DcWakeUp_Flg
    delegate CtAp_ElSSDiag.RTE_R_BswM_KeyWakeUp_Flg <-> outer port CtAp_LvMgmt_swc/RTE_R_BswM_KeyWakeUp_Flg
    delegate CtAp_WakeUpRsn.RTE_R_BswM_KeyWakeUp_Flg <-> outer port CtAp_LvMgmt_swc/RTE_R_BswM_KeyWakeUp_Flg
    delegate CtAp_ElSSDiag.RTE_R_BswM_LinWakeUp_Flg <-> outer port CtAp_LvMgmt_swc/RTE_R_BswM_LinWakeUp_Flg
    delegate CtAp_LvBattMgmt.RTE_R_BswM_LinWakeUp_Flg <-> outer port CtAp_LvMgmt_swc/RTE_R_BswM_LinWakeUp_Flg
    delegate CtAp_WakeUpRsn.RTE_R_BswM_LinWakeUp_Flg <-> outer port CtAp_LvMgmt_swc/RTE_R_BswM_LinWakeUp_Flg
    delegate CtAp_ElSSDiag.RTE_R_ChrMgmt_ChrgSts_Enum <-> outer port CtAp_LvMgmt_swc/RTE_R_ChrMgmt_ChrgSts_Enum
    delegate CtAp_LvBattMgmt.RTE_R_ComM_BMSBattDispSOC_pct <-> outer port CtAp_LvMgmt_swc/RTE_R_ComM_BMSBattDispSOC_pct
    delegate CtAp_WakeUpRsn.RTE_R_ComM_BMSBattSOCLow_Flg <-> outer port CtAp_LvMgmt_swc/RTE_R_ComM_BMSBattSOCLow_Flg
    delegate CtAp_ElSSDiag.RTE_R_ComM_BMSSts_Enum <-> outer port CtAp_LvMgmt_swc/RTE_R_ComM_BMSSts_Enum
    delegate CtAp_ElSSDiag.RTE_R_ComM_DCDCWrkMod_Enum <-> outer port CtAp_LvMgmt_swc/RTE_R_ComM_DCDCWrkMod_Enum
    delegate CtAp_LvBattMgmt.RTE_R_ComM_IBSBattChrgWakeUp_Flg <-> outer port CtAp_LvMgmt_swc/RTE_R_ComM_IBSBattChrgWakeUp_Flg
    delegate CtAp_LvBattMgmt.RTE_R_ComM_IBSBattDchaWakeUp_Flg <-> outer port CtAp_LvMgmt_swc/RTE_R_ComM_IBSBattDchaWakeUp_Flg
    delegate CtAp_LvBattMgmt.RTE_R_ComM_IBSBattIDc_A <-> outer port CtAp_LvMgmt_swc/RTE_R_ComM_IBSBattIDc_A
    delegate CtAp_ElSSDiag.RTE_R_ComM_IBSBattSOC_pct <-> outer port CtAp_LvMgmt_swc/RTE_R_ComM_IBSBattSOC_pct
    delegate CtAp_LvBattMgmt.RTE_R_ComM_IBSBattSOC_pct <-> outer port CtAp_LvMgmt_swc/RTE_R_ComM_IBSBattSOC_pct
    delegate CtAp_WakeUpRsn.RTE_R_ComM_IBSBattSOC_pct <-> outer port CtAp_LvMgmt_swc/RTE_R_ComM_IBSBattSOC_pct
    delegate CtAp_LvBattMgmt.RTE_R_ComM_IBSBattSOCWakeUp_Flg <-> outer port CtAp_LvMgmt_swc/RTE_R_ComM_IBSBattSOCWakeUp_Flg
    delegate CtAp_LvBattMgmt.RTE_R_ComM_IBSBattTemp_C <-> outer port CtAp_LvMgmt_swc/RTE_R_ComM_IBSBattTemp_C
    delegate CtAp_LvBattMgmt.RTE_R_ComM_IBSBattUDc_V <-> outer port CtAp_LvMgmt_swc/RTE_R_ComM_IBSBattUDc_V
    delegate CtAp_WakeUpRsn.RTE_R_ComM_IVIPrecReq_Flg <-> outer port CtAp_LvMgmt_swc/RTE_R_ComM_IVIPrecReq_Flg
    delegate CtAp_WakeUpRsn.RTE_R_ComM_IVIPreheatReq_Flg <-> outer port CtAp_LvMgmt_swc/RTE_R_ComM_IVIPreheatReq_Flg
    delegate CtAp_ElSSDiag.RTE_R_ComM_MCUWrkMod_Enum <-> outer port CtAp_LvMgmt_swc/RTE_R_ComM_MCUWrkMod_Enum
    delegate CtAp_WakeUpRsn.RTE_R_ComM_OBCCCSts_Enum <-> outer port CtAp_LvMgmt_swc/RTE_R_ComM_OBCCCSts_Enum
    delegate CtAp_ElSSDiag.RTE_R_ComM_OBCChrgSts_Enum <-> outer port CtAp_LvMgmt_swc/RTE_R_ComM_OBCChrgSts_Enum
    delegate CtAp_WakeUpRsn.RTE_R_ComM_PEPSPwrMod_Enum <-> outer port CtAp_LvMgmt_swc/RTE_R_ComM_PEPSPwrMod_Enum
    delegate CtAp_WakeUpRsn.RTE_R_ComM_SGWAcReq_Flg <-> outer port CtAp_LvMgmt_swc/RTE_R_ComM_SGWAcReq_Flg
    delegate CtAp_WakeUpRsn.RTE_R_ComM_SGWWakeUpReq_Flg <-> outer port CtAp_LvMgmt_swc/RTE_R_ComM_SGWWakeUpReq_Flg
    delegate CtAp_ElSSDiag.RTE_R_ErrMgmt_OBCMesgLoss_Flg <-> outer port CtAp_LvMgmt_swc/RTE_R_ErrMgmt_OBCMesgLoss_Flg
    delegate CtAp_ElSSDiag.RTE_R_IOAbs_KL15Fb_Flg <-> outer port CtAp_LvMgmt_swc/RTE_R_IOAbs_KL15Fb_Flg
    delegate CtAp_ElSSDiag.RTE_R_ModMgmt_HvSts_Enum <-> outer port CtAp_LvMgmt_swc/RTE_R_ModMgmt_HvSts_Enum
    delegate CtAp_ElSSDiag.RTE_R_ModMgmt_ReqSleep_Flg <-> outer port CtAp_LvMgmt_swc/RTE_R_ModMgmt_ReqSleep_Flg
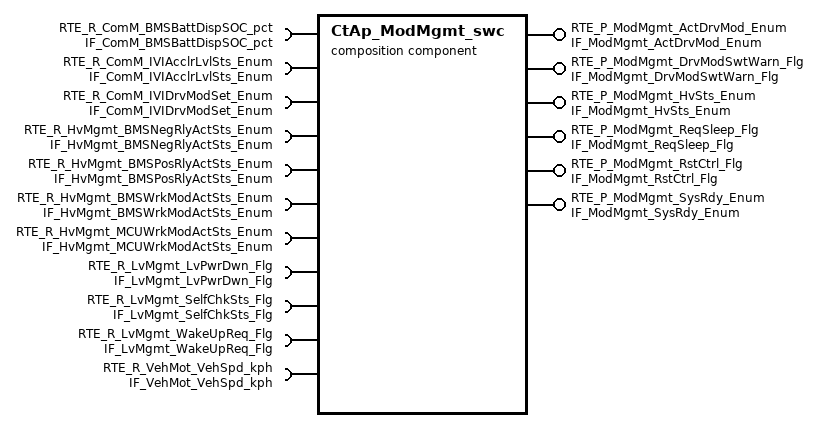
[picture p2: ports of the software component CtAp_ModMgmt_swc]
  composition sw component type CtAp_ModMgmt_swc
    6 x provide port:
      RTE_P_ModMgmt_ActDrvMod_Enum: nonqueued-sender-com-spec{data-element=tec_ModMgmt_ActDrvMod_Enum, init-value=0}, provided-interface=IF_ModMgmt_ActDrvMod_Enum
      RTE_P_ModMgmt_DrvModSwtWarn_Flg: nonqueued-sender-com-spec{data-element=tec_ModMgmt_DrvModSwtWarn_Flg, init-value=0}, provided-interface=IF_ModMgmt_DrvModSwtWarn_Flg
      RTE_P_ModMgmt_HvSts_Enum: nonqueued-sender-com-spec{data-element=tec_ModMgmt_HvSts_Enum, init-value=0}, provided-interface=IF_ModMgmt_HvSts_Enum
      RTE_P_ModMgmt_ReqSleep_Flg: nonqueued-sender-com-spec{data-element=tec_ModMgmt_ReqSleep_Flg, init-value=0}, provided-interface=IF_ModMgmt_ReqSleep_Flg
      RTE_P_ModMgmt_RstCtrl_Flg: nonqueued-sender-com-spec{data-element=tec_ModMgmt_RstCtrl_Flg, init-value=0}, provided-interface=IF_ModMgmt_RstCtrl_Flg
      RTE_P_ModMgmt_SysRdy_Enum: nonqueued-sender-com-spec{data-element=tec_ModMgmt_SysRdy_Enum, init-value=0}, provided-interface=IF_ModMgmt_SysRdy_Enum
    11 x require port:
      RTE_R_ComM_BMSBattDispSOC_pct: nonqueued-receiver-com-spec{data-element=tec_ComM_BMSBattDispSOC_pct, filter=data-filter-type=ALWAYS, init-value=0}, required-interface=IF_ComM_BMSBattDispSOC_pct
      RTE_R_ComM_IVIAcclrLvlSts_Enum: nonqueued-receiver-com-spec{data-element=tec_ComM_IVIAcclrLvlSts_Enum, filter=data-filter-type=ALWAYS, init-value=0}, required-interface=IF_ComM_IVIAcclrLvlSts_Enum
      RTE_R_ComM_IVIDrvModSet_Enum: nonqueued-receiver-com-spec{data-element=tec_ComM_IVIDrvModSet_Enum, filter=data-filter-type=ALWAYS, init-value=0}, required-interface=IF_ComM_IVIDrvModSet_Enum
      RTE_R_HvMgmt_BMSNegRlyActSts_Enum: nonqueued-receiver-com-spec{data-element=tec_HvMgmt_BMSNegRlyActSts_Enum, filter=data-filter-type=ALWAYS, init-value=0}, required-interface=IF_HvMgmt_BMSNegRlyActSts_Enum
      RTE_R_HvMgmt_BMSPosRlyActSts_Enum: nonqueued-receiver-com-spec{data-element=tec_HvMgmt_BMSPosRlyActSts_Enum, filter=data-filter-type=ALWAYS, init-value=0}, required-interface=IF_HvMgmt_BMSPosRlyActSts_Enum
      RTE_R_HvMgmt_BMSWrkModActSts_Enum: nonqueued-receiver-com-spec{data-element=tec_HvMgmt_BMSWrkModActSts_Enum, filter=data-filter-type=ALWAYS, init-value=0}, required-interface=IF_HvMgmt_BMSWrkModActSts_Enum
      RTE_R_HvMgmt_MCUWrkModActSts_Enum: nonqueued-receiver-com-spec{data-element=tec_HvMgmt_MCUWrkModActSts_Enum, filter=data-filter-type=ALWAYS, init-value=0}, required-interface=IF_HvMgmt_MCUWrkModActSts_Enum
      RTE_R_LvMgmt_LvPwrDwn_Flg: nonqueued-receiver-com-spec{data-element=tec_LvMgmt_LvPwrDwn_Flg, filter=data-filter-type=ALWAYS, init-value=0}, required-interface=IF_LvMgmt_LvPwrDwn_Flg
      RTE_R_LvMgmt_SelfChkSts_Flg: nonqueued-receiver-com-spec{data-element=tec_LvMgmt_SelfChkSts_Flg, filter=data-filter-type=ALWAYS, init-value=0}, required-interface=IF_LvMgmt_SelfChkSts_Flg
      RTE_R_LvMgmt_WakeUpReq_Flg: nonqueued-receiver-com-spec{data-element=tec_LvMgmt_WakeUpReq_Flg, filter=data-filter-type=ALWAYS, init-value=0}, required-interface=IF_LvMgmt_WakeUpReq_Flg
      RTE_R_VehMot_VehSpd_kph: nonqueued-receiver-com-spec{data-element=tec_VehMot_VehSpd_kph, filter=data-filter-type=ALWAYS, init-value=0}, required-interface=IF_VehMot_VehSpd_kph
    component CtAp_DrvMod: type=CtAp_DrvMod
    component CtAp_VehStat: type=CtAp_VehStat
    delegate CtAp_DrvMod.RTE_P_ModMgmt_ActDrvMod_Enum <-> outer port CtAp_ModMgmt_swc/RTE_P_ModMgmt_ActDrvMod_Enum
    delegate CtAp_DrvMod.RTE_P_ModMgmt_DrvModSwtWarn_Flg <-> outer port CtAp_ModMgmt_swc/RTE_P_ModMgmt_DrvModSwtWarn_Flg
    delegate CtAp_VehStat.RTE_P_ModMgmt_HvSts_Enum <-> outer port CtAp_ModMgmt_swc/RTE_P_ModMgmt_HvSts_Enum
    delegate CtAp_VehStat.RTE_P_ModMgmt_ReqSleep_Flg <-> outer port CtAp_ModMgmt_swc/RTE_P_ModMgmt_ReqSleep_Flg
    delegate CtAp_VehStat.RTE_P_ModMgmt_RstCtrl_Flg <-> outer port CtAp_ModMgmt_swc/RTE_P_ModMgmt_RstCtrl_Flg
    delegate CtAp_VehStat.RTE_P_ModMgmt_SysRdy_Enum <-> outer port CtAp_ModMgmt_swc/RTE_P_ModMgmt_SysRdy_Enum
    delegate CtAp_DrvMod.RTE_R_ComM_BMSBattDispSOC_pct <-> outer port CtAp_ModMgmt_swc/RTE_R_ComM_BMSBattDispSOC_pct
    delegate CtAp_DrvMod.RTE_R_ComM_IVIAcclrLvlSts_Enum <-> outer port CtAp_ModMgmt_swc/RTE_R_ComM_IVIAcclrLvlSts_Enum
    delegate CtAp_DrvMod.RTE_R_ComM_IVIDrvModSet_Enum <-> outer port CtAp_ModMgmt_swc/RTE_R_ComM_IVIDrvModSet_Enum
    delegate CtAp_VehStat.RTE_R_HvMgmt_BMSNegRlyActSts_Enum <-> outer port CtAp_ModMgmt_swc/RTE_R_HvMgmt_BMSNegRlyActSts_Enum
    delegate CtAp_VehStat.RTE_R_HvMgmt_BMSPosRlyActSts_Enum <-> outer port CtAp_ModMgmt_swc/RTE_R_HvMgmt_BMSPosRlyActSts_Enum
    delegate CtAp_VehStat.RTE_R_HvMgmt_BMSWrkModActSts_Enum <-> outer port CtAp_ModMgmt_swc/RTE_R_HvMgmt_BMSWrkModActSts_Enum
    delegate CtAp_VehStat.RTE_R_HvMgmt_MCUWrkModActSts_Enum <-> outer port CtAp_ModMgmt_swc/RTE_R_HvMgmt_MCUWrkModActSts_Enum
    delegate CtAp_VehStat.RTE_R_LvMgmt_LvPwrDwn_Flg <-> outer port CtAp_ModMgmt_swc/RTE_R_LvMgmt_LvPwrDwn_Flg
    delegate CtAp_VehStat.RTE_R_LvMgmt_SelfChkSts_Flg <-> outer port CtAp_ModMgmt_swc/RTE_R_LvMgmt_SelfChkSts_Flg
    delegate CtAp_VehStat.RTE_R_LvMgmt_WakeUpReq_Flg <-> outer port CtAp_ModMgmt_swc/RTE_R_LvMgmt_WakeUpReq_Flg
    delegate CtAp_VehStat.RTE_R_VehMot_VehSpd_kph <-> outer port CtAp_ModMgmt_swc/RTE_R_VehMot_VehSpd_kph
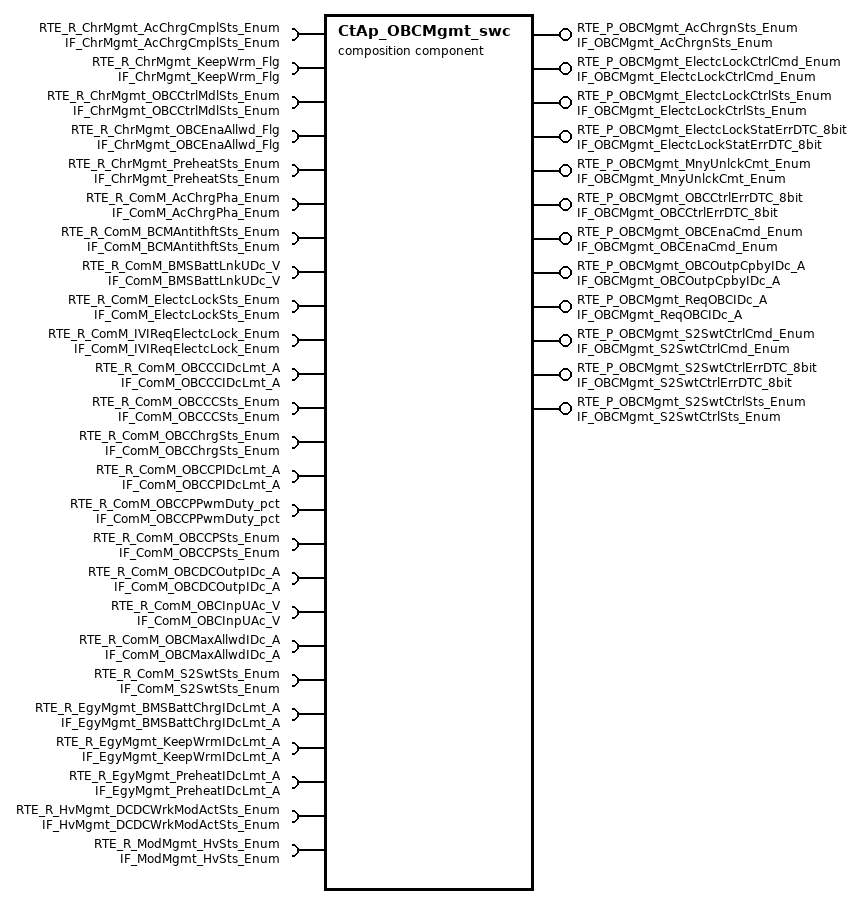
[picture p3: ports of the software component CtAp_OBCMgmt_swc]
  composition sw component type CtAp_OBCMgmt_swc
    12 x provide port:
      RTE_P_OBCMgmt_AcChrgnSts_Enum: nonqueued-sender-com-spec{data-element=tec_OBCMgmt_AcChrgnSts_Enum, init-value=0}, provided-interface=IF_OBCMgmt_AcChrgnSts_Enum
      RTE_P_OBCMgmt_ElectcLockCtrlCmd_Enum: nonqueued-sender-com-spec{data-element=tec_OBCMgmt_ElectcLockCtrlCmd_Enum, init-value=0}, provided-interface=IF_OBCMgmt_ElectcLockCtrlCmd_Enum
      RTE_P_OBCMgmt_ElectcLockCtrlSts_Enum: nonqueued-sender-com-spec{data-element=tec_OBCMgmt_ElectcLockCtrlSts_Enum, init-value=0}, provided-interface=IF_OBCMgmt_ElectcLockCtrlSts_Enum
      RTE_P_OBCMgmt_ElectcLockStatErrDTC_8bit: nonqueued-sender-com-spec{data-element=tec_OBCMgmt_ElectcLockStatErrDTC_8bit, init-value=0}, provided-interface=IF_OBCMgmt_ElectcLockStatErrDTC_8bit
      RTE_P_OBCMgmt_MnyUnlckCmt_Enum: nonqueued-sender-com-spec{data-element=tec_OBCMgmt_MnyUnlckCmt_Enum, init-value=0}, provided-interface=IF_OBCMgmt_MnyUnlckCmt_Enum
      RTE_P_OBCMgmt_OBCCtrlErrDTC_8bit: nonqueued-sender-com-spec{data-element=tec_OBCMgmt_OBCCtrlErrDTC_8bit, init-value=0}, provided-interface=IF_OBCMgmt_OBCCtrlErrDTC_8bit
      RTE_P_OBCMgmt_OBCEnaCmd_Enum: nonqueued-sender-com-spec{data-element=tec_OBCMgmt_OBCEnaCmd_Enum, init-value=0}, provided-interface=IF_OBCMgmt_OBCEnaCmd_Enum
      RTE_P_OBCMgmt_OBCOutpCpbyIDc_A: nonqueued-sender-com-spec{data-element=tec_OBCMgmt_OBCOutpCpbyIDc_A, init-value=0}, provided-interface=IF_OBCMgmt_OBCOutpCpbyIDc_A
      RTE_P_OBCMgmt_ReqOBCIDc_A: nonqueued-sender-com-spec{data-element=tec_OBCMgmt_ReqOBCIDc_A, init-value=0}, provided-interface=IF_OBCMgmt_ReqOBCIDc_A
      RTE_P_OBCMgmt_S2SwtCtrlCmd_Enum: nonqueued-sender-com-spec{data-element=tec_OBCMgmt_S2SwtCtrlCmd_Enum, init-value=0}, provided-interface=IF_OBCMgmt_S2SwtCtrlCmd_Enum
      RTE_P_OBCMgmt_S2SwtCtrlErrDTC_8bit: nonqueued-sender-com-spec{data-element=tec_OBCMgmt_S2SwtCtrlErrDTC_8bit, init-value=0}, provided-interface=IF_OBCMgmt_S2SwtCtrlErrDTC_8bit
      RTE_P_OBCMgmt_S2SwtCtrlSts_Enum: nonqueued-sender-com-spec{data-element=tec_OBCMgmt_S2SwtCtrlSts_Enum, init-value=0}, provided-interface=IF_OBCMgmt_S2SwtCtrlSts_Enum
    25 x require port:
      RTE_R_ChrMgmt_AcChrgCmplSts_Enum: nonqueued-receiver-com-spec{data-element=tec_ChrMgmt_AcChrgCmplSts_Enum, filter=data-filter-type=ALWAYS, init-value=0}, required-interface=IF_ChrMgmt_AcChrgCmplSts_Enum
      RTE_R_ChrMgmt_KeepWrm_Flg: nonqueued-receiver-com-spec{data-element=tec_ChrMgmt_KeepWrm_Flg, filter=data-filter-type=ALWAYS, init-value=0}, required-interface=IF_ChrMgmt_KeepWrm_Flg
      RTE_R_ChrMgmt_OBCCtrlMdlSts_Enum: nonqueued-receiver-com-spec{data-element=tec_ChrMgmt_OBCCtrlMdlSts_Enum, filter=data-filter-type=ALWAYS, init-value=0}, required-interface=IF_ChrMgmt_OBCCtrlMdlSts_Enum
      RTE_R_ChrMgmt_OBCEnaAllwd_Flg: nonqueued-receiver-com-spec{data-element=tec_ChrMgmt_OBCEnaAllwd_Flg, filter=data-filter-type=ALWAYS, init-value=0}, required-interface=IF_ChrMgmt_OBCEnaAllwd_Flg
      RTE_R_ChrMgmt_PreheatSts_Enum: nonqueued-receiver-com-spec{data-element=tec_ChrMgmt_PreheatSts_Enum, filter=data-filter-type=ALWAYS, init-value=0}, required-interface=IF_ChrMgmt_PreheatSts_Enum
      RTE_R_ComM_AcChrgPha_Enum: nonqueued-receiver-com-spec{data-element=tec_ComM_AcChrgPha_Enum, filter=data-filter-type=ALWAYS, init-value=0}, required-interface=IF_ComM_AcChrgPha_Enum
      RTE_R_ComM_BCMAntithftSts_Enum: nonqueued-receiver-com-spec{data-element=tec_ComM_BCMAntithftSts_Enum, filter=data-filter-type=ALWAYS, init-value=0}, required-interface=IF_ComM_BCMAntithftSts_Enum
      RTE_R_ComM_BMSBattLnkUDc_V: nonqueued-receiver-com-spec{data-element=tec_ComM_BMSBattLnkUDc_V, filter=data-filter-type=ALWAYS, init-value=0}, required-interface=IF_ComM_BMSBattLnkUDc_V
      RTE_R_ComM_ElectcLockSts_Enum: nonqueued-receiver-com-spec{data-element=tec_ComM_ElectcLockSts_Enum, filter=data-filter-type=ALWAYS, init-value=0}, required-interface=IF_ComM_ElectcLockSts_Enum
      RTE_R_ComM_IVIReqElectcLock_Enum: nonqueued-receiver-com-spec{data-element=tec_ComM_IVIReqElectcLock_Enum, filter=data-filter-type=ALWAYS, init-value=0}, required-interface=IF_ComM_IVIReqElectcLock_Enum
      RTE_R_ComM_OBCCCIDcLmt_A: nonqueued-receiver-com-spec{data-element=tec_ComM_OBCCCIDcLmt_A, filter=data-filter-type=ALWAYS, init-value=0}, required-interface=IF_ComM_OBCCCIDcLmt_A
      RTE_R_ComM_OBCCCSts_Enum: nonqueued-receiver-com-spec{data-element=tec_ComM_OBCCCSts_Enum, filter=data-filter-type=ALWAYS, init-value=0}, required-interface=IF_ComM_OBCCCSts_Enum
      RTE_R_ComM_OBCChrgSts_Enum: nonqueued-receiver-com-spec{data-element=tec_ComM_OBCChrgSts_Enum, filter=data-filter-type=ALWAYS, init-value=0}, required-interface=IF_ComM_OBCChrgSts_Enum
      RTE_R_ComM_OBCCPIDcLmt_A: nonqueued-receiver-com-spec{data-element=tec_ComM_OBCCPIDcLmt_A, filter=data-filter-type=ALWAYS, init-value=0}, required-interface=IF_ComM_OBCCPIDcLmt_A
      RTE_R_ComM_OBCCPPwmDuty_pct: nonqueued-receiver-com-spec{data-element=tec_ComM_OBCCPPwmDuty_pct, filter=data-filter-type=ALWAYS, init-value=0}, required-interface=IF_ComM_OBCCPPwmDuty_pct
      RTE_R_ComM_OBCCPSts_Enum: nonqueued-receiver-com-spec{data-element=tec_ComM_OBCCPSts_Enum, filter=data-filter-type=ALWAYS, init-value=0}, required-interface=IF_ComM_OBCCPSts_Enum
      RTE_R_ComM_OBCDCOutpIDc_A: nonqueued-receiver-com-spec{data-element=tec_ComM_OBCDCOutpIDc_A, filter=data-filter-type=ALWAYS, init-value=0}, required-interface=IF_ComM_OBCDCOutpIDc_A
      RTE_R_ComM_OBCInpUAc_V: nonqueued-receiver-com-spec{data-element=tec_ComM_OBCInpUAc_V, filter=data-filter-type=ALWAYS, init-value=0}, required-interface=IF_ComM_OBCInpUAc_V
      RTE_R_ComM_OBCMaxAllwdIDc_A: nonqueued-receiver-com-spec{data-element=tec_ComM_OBCMaxAllwdIDc_A, filter=data-filter-type=ALWAYS, init-value=0}, required-interface=IF_ComM_OBCMaxAllwdIDc_A
      RTE_R_ComM_S2SwtSts_Enum: nonqueued-receiver-com-spec{data-element=tec_ComM_S2SwtSts_Enum, filter=data-filter-type=ALWAYS, init-value=0}, required-interface=IF_ComM_S2SwtSts_Enum
      RTE_R_EgyMgmt_BMSBattChrgIDcLmt_A: nonqueued-receiver-com-spec{data-element=tec_EgyMgmt_BMSBattChrgIDcLmt_A, filter=data-filter-type=ALWAYS, init-value=0}, required-interface=IF_EgyMgmt_BMSBattChrgIDcLmt_A
      RTE_R_EgyMgmt_KeepWrmIDcLmt_A: nonqueued-receiver-com-spec{data-element=tec_EgyMgmt_KeepWrmIDcLmt_A, filter=data-filter-type=ALWAYS, init-value=0}, required-interface=IF_EgyMgmt_KeepWrmIDcLmt_A
      RTE_R_EgyMgmt_PreheatIDcLmt_A: nonqueued-receiver-com-spec{data-element=tec_EgyMgmt_PreheatIDcLmt_A, filter=data-filter-type=ALWAYS, init-value=0}, required-interface=IF_EgyMgmt_PreheatIDcLmt_A
      RTE_R_HvMgmt_DCDCWrkModActSts_Enum: nonqueued-receiver-com-spec{data-element=tec_HvMgmt_DCDCWrkModActSts_Enum, filter=data-filter-type=ALWAYS, init-value=0}, required-interface=IF_HvMgmt_DCDCWrkModActSts_Enum
      RTE_R_ModMgmt_HvSts_Enum: nonqueued-receiver-com-spec{data-element=tec_ModMgmt_HvSts_Enum, filter=data-filter-type=ALWAYS, init-value=0}, required-interface=IF_ModMgmt_HvSts_Enum
    4 x component:
      CtAp_ACParMgmt: type=CtAp_ACParMgmt
      CtAp_EmMgmt: type=CtAp_EmMgmt
      CtAp_OBCStsMgmt: type=CtAp_OBCStsMgmt
      CtAp_S2Mgmt: type=CtAp_S2Mgmt
    connect CtAp_EmMgmt.RTE_P_OBCMgmt_ElectcLockCtrlSts_Enum -> CtAp_OBCStsMgmt.RTE_R_OBCMgmt_ElectcLockCtrlSts_Enum
    connect CtAp_EmMgmt.RTE_P_OBCMgmt_ElectcLockCtrlSts_Enum -> CtAp_S2Mgmt.RTE_R_OBCMgmt_ElectcLockCtrlSts_Enum
    connect CtAp_OBCStsMgmt.RTE_P_OBCMgmt_AcChrgnSts_Enum -> CtAp_ACParMgmt.RTE_R_OBCMgmt_AcChrgnSts_Enum
    connect CtAp_OBCStsMgmt.RTE_P_OBCMgmt_AcChrgnSts_Enum -> CtAp_EmMgmt.RTE_R_OBCMgmt_AcChrgnSts_Enum
    connect CtAp_OBCStsMgmt.RTE_P_OBCMgmt_AcChrgnSts_Enum -> CtAp_S2Mgmt.RTE_R_OBCMgmt_AcChrgnSts_Enum
    connect CtAp_S2Mgmt.RTE_P_OBCMgmt_S2SwtCtrlSts_Enum -> CtAp_EmMgmt.RTE_R_OBCMgmt_S2SwtCtrlSts_Enum
    delegate CtAp_OBCStsMgmt.RTE_P_OBCMgmt_AcChrgnSts_Enum <-> outer port CtAp_OBCMgmt_swc/RTE_P_OBCMgmt_AcChrgnSts_Enum
    delegate CtAp_EmMgmt.RTE_P_OBCMgmt_ElectcLockCtrlCmd_Enum <-> outer port CtAp_OBCMgmt_swc/RTE_P_OBCMgmt_ElectcLockCtrlCmd_Enum
    delegate CtAp_EmMgmt.RTE_P_OBCMgmt_ElectcLockCtrlSts_Enum <-> outer port CtAp_OBCMgmt_swc/RTE_P_OBCMgmt_ElectcLockCtrlSts_Enum
    delegate CtAp_EmMgmt.RTE_P_OBCMgmt_ElectcLockStatErrDTC_8bit <-> outer port CtAp_OBCMgmt_swc/RTE_P_OBCMgmt_ElectcLockStatErrDTC_8bit
    delegate CtAp_EmMgmt.RTE_P_OBCMgmt_MnyUnlckCmt_Enum <-> outer port CtAp_OBCMgmt_swc/RTE_P_OBCMgmt_MnyUnlckCmt_Enum
    delegate CtAp_OBCStsMgmt.RTE_P_OBCMgmt_OBCCtrlErrDTC_8bit <-> outer port CtAp_OBCMgmt_swc/RTE_P_OBCMgmt_OBCCtrlErrDTC_8bit
    delegate CtAp_OBCStsMgmt.RTE_P_OBCMgmt_OBCEnaCmd_Enum <-> outer port CtAp_OBCMgmt_swc/RTE_P_OBCMgmt_OBCEnaCmd_Enum
    delegate CtAp_ACParMgmt.RTE_P_OBCMgmt_OBCOutpCpbyIDc_A <-> outer port CtAp_OBCMgmt_swc/RTE_P_OBCMgmt_OBCOutpCpbyIDc_A
    delegate CtAp_ACParMgmt.RTE_P_OBCMgmt_ReqOBCIDc_A <-> outer port CtAp_OBCMgmt_swc/RTE_P_OBCMgmt_ReqOBCIDc_A
    delegate CtAp_S2Mgmt.RTE_P_OBCMgmt_S2SwtCtrlCmd_Enum <-> outer port CtAp_OBCMgmt_swc/RTE_P_OBCMgmt_S2SwtCtrlCmd_Enum
    delegate CtAp_S2Mgmt.RTE_P_OBCMgmt_S2SwtCtrlErrDTC_8bit <-> outer port CtAp_OBCMgmt_swc/RTE_P_OBCMgmt_S2SwtCtrlErrDTC_8bit
    delegate CtAp_S2Mgmt.RTE_P_OBCMgmt_S2SwtCtrlSts_Enum <-> outer port CtAp_OBCMgmt_swc/RTE_P_OBCMgmt_S2SwtCtrlSts_Enum
    delegate CtAp_OBCStsMgmt.RTE_R_ChrMgmt_AcChrgCmplSts_Enum <-> outer port CtAp_OBCMgmt_swc/RTE_R_ChrMgmt_AcChrgCmplSts_Enum
    delegate CtAp_OBCStsMgmt.RTE_R_ChrMgmt_KeepWrm_Flg <-> outer port CtAp_OBCMgmt_swc/RTE_R_ChrMgmt_KeepWrm_Flg
    delegate CtAp_OBCStsMgmt.RTE_R_ChrMgmt_OBCCtrlMdlSts_Enum <-> outer port CtAp_OBCMgmt_swc/RTE_R_ChrMgmt_OBCCtrlMdlSts_Enum
    delegate CtAp_OBCStsMgmt.RTE_R_ChrMgmt_OBCEnaAllwd_Flg <-> outer port CtAp_OBCMgmt_swc/RTE_R_ChrMgmt_OBCEnaAllwd_Flg
    delegate CtAp_OBCStsMgmt.RTE_R_ChrMgmt_PreheatSts_Enum <-> outer port CtAp_OBCMgmt_swc/RTE_R_ChrMgmt_PreheatSts_Enum
    delegate CtAp_ACParMgmt.RTE_R_ComM_AcChrgPha_Enum <-> outer port CtAp_OBCMgmt_swc/RTE_R_ComM_AcChrgPha_Enum
    delegate CtAp_EmMgmt.RTE_R_ComM_BCMAntithftSts_Enum <-> outer port CtAp_OBCMgmt_swc/RTE_R_ComM_BCMAntithftSts_Enum
    delegate CtAp_ACParMgmt.RTE_R_ComM_BMSBattLnkUDc_V <-> outer port CtAp_OBCMgmt_swc/RTE_R_ComM_BMSBattLnkUDc_V
    delegate CtAp_EmMgmt.RTE_R_ComM_ElectcLockSts_Enum <-> outer port CtAp_OBCMgmt_swc/RTE_R_ComM_ElectcLockSts_Enum
    delegate CtAp_EmMgmt.RTE_R_ComM_IVIReqElectcLock_Enum <-> outer port CtAp_OBCMgmt_swc/RTE_R_ComM_IVIReqElectcLock_Enum
    delegate CtAp_ACParMgmt.RTE_R_ComM_OBCCCIDcLmt_A <-> outer port CtAp_OBCMgmt_swc/RTE_R_ComM_OBCCCIDcLmt_A
    delegate CtAp_EmMgmt.RTE_R_ComM_OBCCCSts_Enum <-> outer port CtAp_OBCMgmt_swc/RTE_R_ComM_OBCCCSts_Enum
    delegate CtAp_OBCStsMgmt.RTE_R_ComM_OBCChrgSts_Enum <-> outer port CtAp_OBCMgmt_swc/RTE_R_ComM_OBCChrgSts_Enum
    delegate CtAp_ACParMgmt.RTE_R_ComM_OBCCPIDcLmt_A <-> outer port CtAp_OBCMgmt_swc/RTE_R_ComM_OBCCPIDcLmt_A
    delegate CtAp_OBCStsMgmt.RTE_R_ComM_OBCCPPwmDuty_pct <-> outer port CtAp_OBCMgmt_swc/RTE_R_ComM_OBCCPPwmDuty_pct
    delegate CtAp_EmMgmt.RTE_R_ComM_OBCCPSts_Enum <-> outer port CtAp_OBCMgmt_swc/RTE_R_ComM_OBCCPSts_Enum
    delegate CtAp_OBCStsMgmt.RTE_R_ComM_OBCCPSts_Enum <-> outer port CtAp_OBCMgmt_swc/RTE_R_ComM_OBCCPSts_Enum
    delegate CtAp_S2Mgmt.RTE_R_ComM_OBCCPSts_Enum <-> outer port CtAp_OBCMgmt_swc/RTE_R_ComM_OBCCPSts_Enum
    delegate CtAp_ACParMgmt.RTE_R_ComM_OBCDCOutpIDc_A <-> outer port CtAp_OBCMgmt_swc/RTE_R_ComM_OBCDCOutpIDc_A
    delegate CtAp_ACParMgmt.RTE_R_ComM_OBCInpUAc_V <-> outer port CtAp_OBCMgmt_swc/RTE_R_ComM_OBCInpUAc_V
    delegate CtAp_S2Mgmt.RTE_R_ComM_OBCInpUAc_V <-> outer port CtAp_OBCMgmt_swc/RTE_R_ComM_OBCInpUAc_V
    delegate CtAp_ACParMgmt.RTE_R_ComM_OBCMaxAllwdIDc_A <-> outer port CtAp_OBCMgmt_swc/RTE_R_ComM_OBCMaxAllwdIDc_A
    delegate CtAp_S2Mgmt.RTE_R_ComM_S2SwtSts_Enum <-> outer port CtAp_OBCMgmt_swc/RTE_R_ComM_S2SwtSts_Enum
    delegate CtAp_ACParMgmt.RTE_R_EgyMgmt_BMSBattChrgIDcLmt_A <-> outer port CtAp_OBCMgmt_swc/RTE_R_EgyMgmt_BMSBattChrgIDcLmt_A
    delegate CtAp_ACParMgmt.RTE_R_EgyMgmt_KeepWrmIDcLmt_A <-> outer port CtAp_OBCMgmt_swc/RTE_R_EgyMgmt_KeepWrmIDcLmt_A
    delegate CtAp_ACParMgmt.RTE_R_EgyMgmt_PreheatIDcLmt_A <-> outer port CtAp_OBCMgmt_swc/RTE_R_EgyMgmt_PreheatIDcLmt_A
    delegate CtAp_ACParMgmt.RTE_R_HvMgmt_DCDCWrkModActSts_Enum <-> outer port CtAp_OBCMgmt_swc/RTE_R_HvMgmt_DCDCWrkModActSts_Enum
    delegate CtAp_ACParMgmt.RTE_R_ModMgmt_HvSts_Enum <-> outer port CtAp_OBCMgmt_swc/RTE_R_ModMgmt_HvSts_Enum
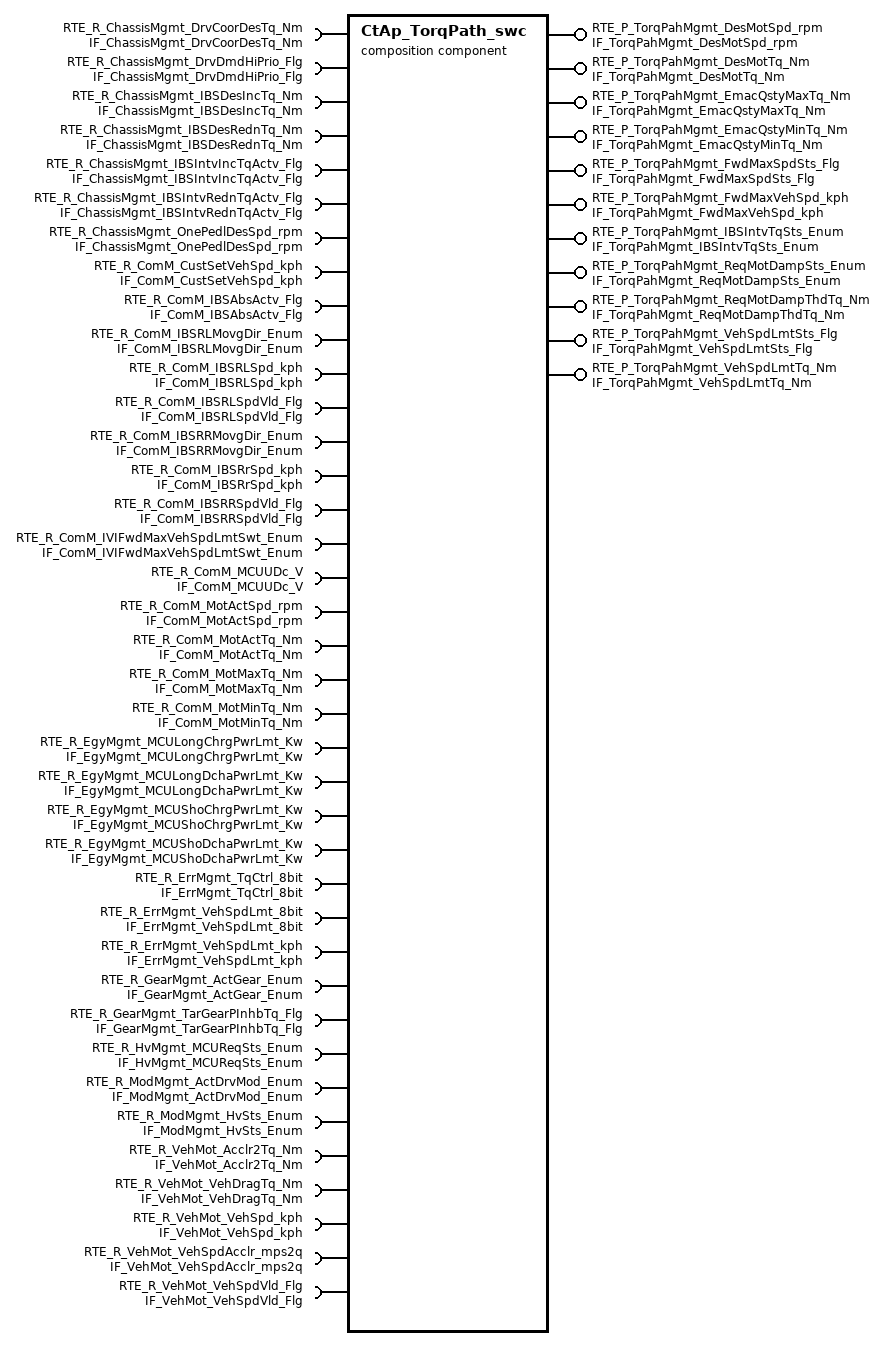
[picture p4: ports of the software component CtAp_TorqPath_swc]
  composition sw component type CtAp_TorqPath_swc
    11 x provide port:
      RTE_P_TorqPahMgmt_DesMotSpd_rpm: nonqueued-sender-com-spec{data-element=tec_TorqPahMgmt_DesMotSpd_rpm, init-value=0}, provided-interface=IF_TorqPahMgmt_DesMotSpd_rpm
      RTE_P_TorqPahMgmt_DesMotTq_Nm: nonqueued-sender-com-spec{data-element=tec_TorqPahMgmt_DesMotTq_Nm, init-value=0}, provided-interface=IF_TorqPahMgmt_DesMotTq_Nm
      RTE_P_TorqPahMgmt_EmacQstyMaxTq_Nm: nonqueued-sender-com-spec{data-element=tec_TorqPahMgmt_EmacQstyMaxTq_Nm, init-value=0}, provided-interface=IF_TorqPahMgmt_EmacQstyMaxTq_Nm
      RTE_P_TorqPahMgmt_EmacQstyMinTq_Nm: nonqueued-sender-com-spec{data-element=tec_TorqPahMgmt_EmacQstyMinTq_Nm, init-value=0}, provided-interface=IF_TorqPahMgmt_EmacQstyMinTq_Nm
      RTE_P_TorqPahMgmt_FwdMaxSpdSts_Flg: nonqueued-sender-com-spec{data-element=tec_TorqPahMgmt_FwdMaxSpdSts_Flg, init-value=0}, provided-interface=IF_TorqPahMgmt_FwdMaxSpdSts_Flg
      RTE_P_TorqPahMgmt_FwdMaxVehSpd_kph: nonqueued-sender-com-spec{data-element=tec_TorqPahMgmt_FwdMaxVehSpd_kph, init-value=0}, provided-interface=IF_TorqPahMgmt_FwdMaxVehSpd_kph
      RTE_P_TorqPahMgmt_IBSIntvTqSts_Enum: nonqueued-sender-com-spec{data-element=tec_TorqPahMgmt_IBSIntvTqSts_Enum, init-value=0}, provided-interface=IF_TorqPahMgmt_IBSIntvTqSts_Enum
      RTE_P_TorqPahMgmt_ReqMotDampSts_Enum: nonqueued-sender-com-spec{data-element=tec_TorqPahMgmt_ReqMotDampSts_Enum, init-value=0}, provided-interface=IF_TorqPahMgmt_ReqMotDampSts_Enum
      RTE_P_TorqPahMgmt_ReqMotDampThdTq_Nm: nonqueued-sender-com-spec{data-element=tec_TorqPahMgmt_ReqMotDampThdTq_Nm, init-value=0}, provided-interface=IF_TorqPahMgmt_ReqMotDampThdTq_Nm
      RTE_P_TorqPahMgmt_VehSpdLmtSts_Flg: nonqueued-sender-com-spec{data-element=tec_TorqPahMgmt_VehSpdLmtSts_Flg, init-value=0}, provided-interface=IF_TorqPahMgmt_VehSpdLmtSts_Flg
      RTE_P_TorqPahMgmt_VehSpdLmtTq_Nm: nonqueued-sender-com-spec{data-element=tec_TorqPahMgmt_VehSpdLmtTq_Nm, init-value=0}, provided-interface=IF_TorqPahMgmt_VehSpdLmtTq_Nm
    38 x require port:
      RTE_R_ChassisMgmt_DrvCoorDesTq_Nm: nonqueued-receiver-com-spec{data-element=tec_ChassisMgmt_DrvCoorDesTq_Nm, filter=data-filter-type=ALWAYS}, required-interface=IF_ChassisMgmt_DrvCoorDesTq_Nm
      RTE_R_ChassisMgmt_DrvDmdHiPrio_Flg: nonqueued-receiver-com-spec{data-element=tec_ChassisMgmt_DrvDmdHiPrio_Flg, filter=data-filter-type=ALWAYS}, required-interface=IF_ChassisMgmt_DrvDmdHiPrio_Flg
      RTE_R_ChassisMgmt_IBSDesIncTq_Nm: nonqueued-receiver-com-spec{data-element=tec_ChassisMgmt_IBSDesIncTq_Nm, filter=data-filter-type=ALWAYS}, required-interface=IF_ChassisMgmt_IBSDesIncTq_Nm
      RTE_R_ChassisMgmt_IBSDesRednTq_Nm: nonqueued-receiver-com-spec{data-element=tec_ChassisMgmt_IBSDesRednTq_Nm, filter=data-filter-type=ALWAYS}, required-interface=IF_ChassisMgmt_IBSDesRednTq_Nm
      RTE_R_ChassisMgmt_IBSIntvIncTqActv_Flg: nonqueued-receiver-com-spec{data-element=tec_ChassisMgmt_IBSIntvIncTqActv_Flg, filter=data-filter-type=ALWAYS}, required-interface=IF_ChassisMgmt_IBSIntvIncTqActv_Flg
      RTE_R_ChassisMgmt_IBSIntvRednTqActv_Flg: nonqueued-receiver-com-spec{data-element=tec_ChassisMgmt_IBSIntvRednTqActv_Flg, filter=data-filter-type=ALWAYS}, required-interface=IF_ChassisMgmt_IBSIntvRednTqActv_Flg
      RTE_R_ChassisMgmt_OnePedlDesSpd_rpm: nonqueued-receiver-com-spec{data-element=tec_ChassisMgmt_OnePedlDesSpd_rpm, filter=data-filter-type=ALWAYS}, required-interface=IF_ChassisMgmt_OnePedlDesSpd_rpm
      RTE_R_ComM_CustSetVehSpd_kph: nonqueued-receiver-com-spec{data-element=tec_ComM_IVISetFwdVehSpd_kph, filter=data-filter-type=ALWAYS}, required-interface=IF_ComM_CustSetVehSpd_kph
      RTE_R_ComM_IBSAbsActv_Flg: nonqueued-receiver-com-spec{data-element=tec_ComM_IBSAbsActv_Flg, filter=data-filter-type=ALWAYS}, required-interface=IF_ComM_IBSAbsActv_Flg
      RTE_R_ComM_IBSRLMovgDir_Enum: nonqueued-receiver-com-spec{data-element=tec_ComM_IBSRLMovgDir_Enum, filter=data-filter-type=ALWAYS}, required-interface=IF_ComM_IBSRLMovgDir_Enum
      RTE_R_ComM_IBSRLSpd_kph: nonqueued-receiver-com-spec{data-element=tec_ComM_IBSRLSpd_kph, filter=data-filter-type=ALWAYS}, required-interface=IF_ComM_IBSRLSpd_kph
      RTE_R_ComM_IBSRLSpdVld_Flg: nonqueued-receiver-com-spec{data-element=tec_ComM_IBSRLSpdVld_Flg, filter=data-filter-type=ALWAYS}, required-interface=IF_ComM_IBSRLSpdVld_Flg
      RTE_R_ComM_IBSRRMovgDir_Enum: nonqueued-receiver-com-spec{data-element=tec_ComM_IBSRRMovgDir_Enum, filter=data-filter-type=ALWAYS}, required-interface=IF_ComM_IBSRRMovgDir_Enum
      RTE_R_ComM_IBSRrSpd_kph: nonqueued-receiver-com-spec{data-element=tec_ComM_IBSRRSpd_kph, filter=data-filter-type=ALWAYS}, required-interface=IF_ComM_IBSRrSpd_kph
      RTE_R_ComM_IBSRRSpdVld_Flg: nonqueued-receiver-com-spec{data-element=tec_ComM_IBSRRSpdVld_Flg, filter=data-filter-type=ALWAYS}, required-interface=IF_ComM_IBSRRSpdVld_Flg
      RTE_R_ComM_IVIFwdMaxVehSpdLmtSwt_Enum: nonqueued-receiver-com-spec{data-element=tec_ComM_IVIFwdMaxVehSpdLmtSwt_Enum, filter=data-filter-type=ALWAYS}, required-interface=IF_ComM_IVIFwdMaxVehSpdLmtSwt_Enum
      RTE_R_ComM_MCUUDc_V: nonqueued-receiver-com-spec{data-element=tec_ComM_MCUUDc_V, filter=data-filter-type=ALWAYS}, required-interface=IF_ComM_MCUUDc_V
      RTE_R_ComM_MotActSpd_rpm: nonqueued-receiver-com-spec{data-element=tec_ComM_MotActSpd_rpm, filter=data-filter-type=ALWAYS}, required-interface=IF_ComM_MotActSpd_rpm
      RTE_R_ComM_MotActTq_Nm: nonqueued-receiver-com-spec{data-element=tec_ComM_MotActTq_Nm, filter=data-filter-type=ALWAYS}, required-interface=IF_ComM_MotActTq_Nm
      RTE_R_ComM_MotMaxTq_Nm: nonqueued-receiver-com-spec{data-element=tec_ComM_MotMaxTq_Nm, filter=data-filter-type=ALWAYS}, required-interface=IF_ComM_MotMaxTq_Nm
      RTE_R_ComM_MotMinTq_Nm: nonqueued-receiver-com-spec{data-element=tec_ComM_MotMinTq_Nm, filter=data-filter-type=ALWAYS}, required-interface=IF_ComM_MotMinTq_Nm
      RTE_R_EgyMgmt_MCULongChrgPwrLmt_Kw: nonqueued-receiver-com-spec{data-element=tec_EgyMgmt_MCULongChrgPwrLmt_Kw, filter=data-filter-type=ALWAYS}, required-interface=IF_EgyMgmt_MCULongChrgPwrLmt_Kw
      RTE_R_EgyMgmt_MCULongDchaPwrLmt_Kw: nonqueued-receiver-com-spec{data-element=tec_EgyMgmt_MCULongDchaPwrLmt_Kw, filter=data-filter-type=ALWAYS}, required-interface=IF_EgyMgmt_MCULongDchaPwrLmt_Kw
      RTE_R_EgyMgmt_MCUShoChrgPwrLmt_Kw: nonqueued-receiver-com-spec{data-element=tec_EgyMgmt_MCUShoChrgPwrLmt_Kw, filter=data-filter-type=ALWAYS}, required-interface=IF_EgyMgmt_MCUShoChrgPwrLmt_Kw
      RTE_R_EgyMgmt_MCUShoDchaPwrLmt_Kw: nonqueued-receiver-com-spec{data-element=tec_EgyMgmt_MCUShoDchaPwrLmt_Kw, filter=data-filter-type=ALWAYS}, required-interface=IF_EgyMgmt_MCUShoDchaPwrLmt_Kw
      RTE_R_ErrMgmt_TqCtrl_8bit: nonqueued-receiver-com-spec{data-element=tec_ErrMgmt_TqCtrl_8bit, filter=data-filter-type=ALWAYS}, required-interface=IF_ErrMgmt_TqCtrl_8bit
      RTE_R_ErrMgmt_VehSpdLmt_8bit: nonqueued-receiver-com-spec{data-element=tec_ErrMgmt_VehSpdLmt_8bit, filter=data-filter-type=ALWAYS}, required-interface=IF_ErrMgmt_VehSpdLmt_8bit
      RTE_R_ErrMgmt_VehSpdLmt_kph: nonqueued-receiver-com-spec{data-element=tec_ErrMgmt_VehSpdLmt_kph, filter=data-filter-type=ALWAYS}, required-interface=IF_ErrMgmt_VehSpdLmt_kph
      RTE_R_GearMgmt_ActGear_Enum: nonqueued-receiver-com-spec{data-element=tec_GearMgmt_ActGear_Enum, filter=data-filter-type=ALWAYS}, required-interface=IF_GearMgmt_ActGear_Enum
      RTE_R_GearMgmt_TarGearPInhbTq_Flg: nonqueued-receiver-com-spec{data-element=tec_GearMgmt_TarGearPInhbTq_Flg, filter=data-filter-type=ALWAYS}, required-interface=IF_GearMgmt_TarGearPInhbTq_Flg
      RTE_R_HvMgmt_MCUReqSts_Enum: nonqueued-receiver-com-spec{data-element=tec_HvMgmt_MCUReqSts_Enum, filter=data-filter-type=ALWAYS}, required-interface=IF_HvMgmt_MCUReqSts_Enum
      RTE_R_ModMgmt_ActDrvMod_Enum: nonqueued-receiver-com-spec{data-element=tec_ModMgmt_ActDrvMod_Enum, filter=data-filter-type=ALWAYS}, required-interface=IF_ModMgmt_ActDrvMod_Enum
      RTE_R_ModMgmt_HvSts_Enum: nonqueued-receiver-com-spec{data-element=tec_ModMgmt_HvSts_Enum, filter=data-filter-type=ALWAYS}, required-interface=IF_ModMgmt_HvSts_Enum
      RTE_R_VehMot_Acclr2Tq_Nm: nonqueued-receiver-com-spec{data-element=tec_VehMot_Acclr2Tq_Nm, filter=data-filter-type=ALWAYS}, required-interface=IF_VehMot_Acclr2Tq_Nm
      RTE_R_VehMot_VehDragTq_Nm: nonqueued-receiver-com-spec{data-element=tec_VehMot_VehDragTq_Nm, filter=data-filter-type=ALWAYS}, required-interface=IF_VehMot_VehDragTq_Nm
      RTE_R_VehMot_VehSpd_kph: nonqueued-receiver-com-spec{data-element=tec_VehMot_VehSpd_kph, filter=data-filter-type=ALWAYS}, required-interface=IF_VehMot_VehSpd_kph
      RTE_R_VehMot_VehSpdAcclr_mps2q: nonqueued-receiver-com-spec{data-element=tec_VehMot_VehSpdAcclr_mps2q, filter=data-filter-type=ALWAYS}, required-interface=IF_VehMot_VehSpdAcclr_mps2q
      RTE_R_VehMot_VehSpdVld_Flg: nonqueued-receiver-com-spec{data-element=tec_VehMot_VehSpdVld_Flg, filter=data-filter-type=ALWAYS}, required-interface=IF_VehMot_VehSpdVld_Flg
    8 x component:
      CtAp_SpdLmt: type=CtAp_SpdLmt
      CtAp_TorqCoor: type=CtAp_TorqCoor
      CtAp_TorqCrossZr: type=CtAp_TorqCrossZr
      CtAp_TorqDamp: type=CtAp_TorqDamp
      CtAp_TorqFil: type=CtAp_TorqFil
      CtAp_TorqLmt: type=CtAp_TorqLmt
      CtAp_TorqModMap: type=CtAp_TorqModMap
      CtAp_TrsmProtd: type=CtAp_TrsmProtd
    connect CtAp_TorqCoor.RTE_P_TorqPahMgmt_DesCoorTq_Nm -> CtAp_TorqModMap.RTE_R_TorqPahMgmt_DesCoorTq_Nm
    connect CtAp_TorqCrossZr.RTE_P_TorqPahMgmt_DesFildTq_Nm -> CtAp_TorqCoor.RTE_R_TorqPahMgmt_DesFildTq_Nm
    connect CtAp_TorqFil.RTE_P_TorqPahMgmt_DesLpFildTq_Nm -> CtAp_TorqCrossZr.RTE_R_TorqPahMgmt_DesLpFildTq_Nm
    connect CtAp_TorqLmt.RTE_P_TorqPahMgmt_EmacQstyMaxTq_Nm -> CtAp_SpdLmt.RTE_R_TorqPahMgmt_EmacQstyMaxTq_Nm
    connect CtAp_TorqLmt.RTE_P_TorqPahMgmt_EmacQstyMinTq_Nm -> CtAp_SpdLmt.RTE_R_TorqPahMgmt_EmacQstyMinTq_Nm
    connect CtAp_TorqLmt.RTE_P_TorqPahMgmt_EmacDynMaxTq_Nm -> CtAp_TorqCoor.RTE_R_TorqPahMgmt_EmacDynMaxTq_Nm
    connect CtAp_TorqLmt.RTE_P_TorqPahMgmt_EmacDynMinTq_Nm -> CtAp_TorqCoor.RTE_R_TorqPahMgmt_EmacDynMinTq_Nm
    connect CtAp_TorqLmt.RTE_P_TorqPahMgmt_EmacQstyMaxTq_Nm -> CtAp_TorqDamp.RTE_R_TorqPahMgmt_EmacQstyMaxTq_Nm
    connect CtAp_TorqLmt.RTE_P_TorqPahMgmt_EmacQstyMinTq_Nm -> CtAp_TorqDamp.RTE_R_TorqPahMgmt_EmacQstyMinTq_Nm
    connect CtAp_TorqLmt.RTE_P_TorqPahMgmt_EmacQstyMaxTq_Nm -> CtAp_TorqFil.RTE_R_TorqPahMgmt_EmacQstyMaxTq_Nm
    connect CtAp_TorqLmt.RTE_P_TorqPahMgmt_EmacQstyMinTq_Nm -> CtAp_TorqFil.RTE_R_TorqPahMgmt_EmacQstyMinTq_Nm
    connect CtAp_TrsmProtd.RTE_P_TorqPahMgmt_TramProtdLimMaxTq_Nm -> CtAp_TorqModMap.RTE_R_TorqPahMgmt_TramProtdLmtMaxTq_Nm
    connect CtAp_TrsmProtd.RTE_P_TorqPahMgmt_TramProtdLimMinTq_Nm -> CtAp_TorqModMap.RTE_R_TorqPahMgmt_TramProtdLmtMinTq_Nm
    delegate CtAp_TorqModMap.RTE_P_TorqPahMgmt_DesMotSpd_rpm <-> outer port CtAp_TorqPath_swc/RTE_P_TorqPahMgmt_DesMotSpd_rpm
    delegate CtAp_TorqModMap.RTE_P_TorqPahMgmt_DesMotTq_Nm <-> outer port CtAp_TorqPath_swc/RTE_P_TorqPahMgmt_DesMotTq_Nm
    delegate CtAp_TorqLmt.RTE_P_TorqPahMgmt_EmacQstyMaxTq_Nm <-> outer port CtAp_TorqPath_swc/RTE_P_TorqPahMgmt_EmacQstyMaxTq_Nm
    delegate CtAp_TorqLmt.RTE_P_TorqPahMgmt_EmacQstyMinTq_Nm <-> outer port CtAp_TorqPath_swc/RTE_P_TorqPahMgmt_EmacQstyMinTq_Nm
    delegate CtAp_SpdLmt.RTE_P_TorqPahMgmt_FwdMaxSpdSts_Flg <-> outer port CtAp_TorqPath_swc/RTE_P_TorqPahMgmt_FwdMaxSpdSts_Flg
    delegate CtAp_SpdLmt.RTE_P_TorqPahMgmt_FwdMaxVehSpd_kph <-> outer port CtAp_TorqPath_swc/RTE_P_TorqPahMgmt_FwdMaxVehSpd_kph
    delegate CtAp_TorqCoor.RTE_P_TorqPahMgmt_IBSIntvTqSts_Enum <-> outer port CtAp_TorqPath_swc/RTE_P_TorqPahMgmt_IBSIntvTqSts_Enum
    delegate CtAp_TorqDamp.RTE_P_TorqPahMgmt_ReqMotDampSts_Enum <-> outer port CtAp_TorqPath_swc/RTE_P_TorqPahMgmt_ReqMotDampSts_Enum
    delegate CtAp_TorqDamp.RTE_P_TorqPahMgmt_ReqMotDampThdTq_Nm <-> outer port CtAp_TorqPath_swc/RTE_P_TorqPahMgmt_ReqMotDampThdTq_Nm
    delegate CtAp_SpdLmt.RTE_P_TorqPahMgmt_VehSpdLmtSts_Flg <-> outer port CtAp_TorqPath_swc/RTE_P_TorqPahMgmt_VehSpdLmtSts_Flg
    delegate CtAp_SpdLmt.RTE_P_TorqPahMgmt_VehSpdLmtTq_Nm <-> outer port CtAp_TorqPath_swc/RTE_P_TorqPahMgmt_VehSpdLmtTq_Nm
    delegate CtAp_TorqFil.RTE_R_ChassisMgmt_DrvCoorDesTq_Nm <-> outer port CtAp_TorqPath_swc/RTE_R_ChassisMgmt_DrvCoorDesTq_Nm
    delegate CtAp_TorqCrossZr.RTE_R_ChassisMgmt_DrvDmdHiPrio_Flg <-> outer port CtAp_TorqPath_swc/RTE_R_ChassisMgmt_DrvDmdHiPrio_Flg
    delegate CtAp_TorqFil.RTE_R_ChassisMgmt_DrvDmdHiPrio_Flg <-> outer port CtAp_TorqPath_swc/RTE_R_ChassisMgmt_DrvDmdHiPrio_Flg
    delegate CtAp_TorqCoor.RTE_R_ChassisMgmt_IBSDesIncTq_Nm <-> outer port CtAp_TorqPath_swc/RTE_R_ChassisMgmt_IBSDesIncTq_Nm
    delegate CtAp_TorqCoor.RTE_R_ChassisMgmt_IBSDesRednTq_Nm <-> outer port CtAp_TorqPath_swc/RTE_R_ChassisMgmt_IBSDesRednTq_Nm
    delegate CtAp_TorqCoor.RTE_R_ChassisMgmt_IBSIntvIncTqActv_Flg <-> outer port CtAp_TorqPath_swc/RTE_R_ChassisMgmt_IBSIntvIncTqActv_Flg
    delegate CtAp_TorqDamp.RTE_R_ChassisMgmt_IBSIntvIncTqActv_Flg <-> outer port CtAp_TorqPath_swc/RTE_R_ChassisMgmt_IBSIntvIncTqActv_Flg
    delegate CtAp_TorqCoor.RTE_R_ChassisMgmt_IBSIntvRednTqActv_Flg <-> outer port CtAp_TorqPath_swc/RTE_R_ChassisMgmt_IBSIntvRednTqActv_Flg
    delegate CtAp_TorqDamp.RTE_R_ChassisMgmt_IBSIntvRednTqActv_Flg <-> outer port CtAp_TorqPath_swc/RTE_R_ChassisMgmt_IBSIntvRednTqActv_Flg
    delegate CtAp_TorqModMap.RTE_R_ChassisMgmt_OnePedlDesSpd_rpm <-> outer port CtAp_TorqPath_swc/RTE_R_ChassisMgmt_OnePedlDesSpd_rpm
    delegate CtAp_SpdLmt.RTE_R_ComM_CustSetVehSpd_kph <-> outer port CtAp_TorqPath_swc/RTE_R_ComM_CustSetVehSpd_kph
    delegate CtAp_TorqDamp.RTE_R_ComM_IBSAbsActv_Flg <-> outer port CtAp_TorqPath_swc/RTE_R_ComM_IBSAbsActv_Flg
    delegate CtAp_TrsmProtd.RTE_R_ComM_IBSRLMovgDir_Enum <-> outer port CtAp_TorqPath_swc/RTE_R_ComM_IBSRLMovgDir_Enum
    delegate CtAp_TrsmProtd.RTE_R_ComM_IBSRLSpd_kph <-> outer port CtAp_TorqPath_swc/RTE_R_ComM_IBSRLSpd_kph
    delegate CtAp_TrsmProtd.RTE_R_ComM_IBSRLSpdVld_Flg <-> outer port CtAp_TorqPath_swc/RTE_R_ComM_IBSRLSpdVld_Flg
    delegate CtAp_TrsmProtd.RTE_R_ComM_IBSRRMovgDir_Enum <-> outer port CtAp_TorqPath_swc/RTE_R_ComM_IBSRRMovgDir_Enum
    delegate CtAp_TrsmProtd.RTE_R_ComM_IBSRrSpd_kph <-> outer port CtAp_TorqPath_swc/RTE_R_ComM_IBSRrSpd_kph
    delegate CtAp_TorqDamp.RTE_R_ComM_IBSRRSpdVld_Flg <-> outer port CtAp_TorqPath_swc/RTE_R_ComM_IBSRRSpdVld_Flg
    delegate CtAp_TrsmProtd.RTE_R_ComM_IBSRRSpdVld_Flg <-> outer port CtAp_TorqPath_swc/RTE_R_ComM_IBSRRSpdVld_Flg
    delegate CtAp_SpdLmt.RTE_R_ComM_IVIFwdMaxVehSpdLmtSwt_Enum <-> outer port CtAp_TorqPath_swc/RTE_R_ComM_IVIFwdMaxVehSpdLmtSwt_Enum
    delegate CtAp_TorqLmt.RTE_R_ComM_MCUUDc_V <-> outer port CtAp_TorqPath_swc/RTE_R_ComM_MCUUDc_V
    delegate CtAp_TorqLmt.RTE_R_ComM_MotActSpd_rpm <-> outer port CtAp_TorqPath_swc/RTE_R_ComM_MotActSpd_rpm
    delegate CtAp_TrsmProtd.RTE_R_ComM_MotActSpd_rpm <-> outer port CtAp_TorqPath_swc/RTE_R_ComM_MotActSpd_rpm
    delegate CtAp_TorqModMap.RTE_R_ComM_MotActTq_Nm <-> outer port CtAp_TorqPath_swc/RTE_R_ComM_MotActTq_Nm
    delegate CtAp_TorqLmt.RTE_R_ComM_MotMaxTq_Nm <-> outer port CtAp_TorqPath_swc/RTE_R_ComM_MotMaxTq_Nm
    delegate CtAp_TorqLmt.RTE_R_ComM_MotMinTq_Nm <-> outer port CtAp_TorqPath_swc/RTE_R_ComM_MotMinTq_Nm
    delegate CtAp_TorqLmt.RTE_R_EgyMgmt_MCULongChrgPwrLmt_Kw <-> outer port CtAp_TorqPath_swc/RTE_R_EgyMgmt_MCULongChrgPwrLmt_Kw
    delegate CtAp_TorqLmt.RTE_R_EgyMgmt_MCULongDchaPwrLmt_Kw <-> outer port CtAp_TorqPath_swc/RTE_R_EgyMgmt_MCULongDchaPwrLmt_Kw
    delegate CtAp_TorqLmt.RTE_R_EgyMgmt_MCUShoChrgPwrLmt_Kw <-> outer port CtAp_TorqPath_swc/RTE_R_EgyMgmt_MCUShoChrgPwrLmt_Kw
    delegate CtAp_TorqLmt.RTE_R_EgyMgmt_MCUShoDchaPwrLmt_Kw <-> outer port CtAp_TorqPath_swc/RTE_R_EgyMgmt_MCUShoDchaPwrLmt_Kw
    delegate CtAp_TorqLmt.RTE_R_ErrMgmt_TqCtrl_8bit <-> outer port CtAp_TorqPath_swc/RTE_R_ErrMgmt_TqCtrl_8bit
    delegate CtAp_SpdLmt.RTE_R_ErrMgmt_VehSpdLmt_8bit <-> outer port CtAp_TorqPath_swc/RTE_R_ErrMgmt_VehSpdLmt_8bit
    delegate CtAp_SpdLmt.RTE_R_ErrMgmt_VehSpdLmt_kph <-> outer port CtAp_TorqPath_swc/RTE_R_ErrMgmt_VehSpdLmt_kph
    delegate CtAp_SpdLmt.RTE_R_GearMgmt_ActGear_Enum <-> outer port CtAp_TorqPath_swc/RTE_R_GearMgmt_ActGear_Enum
    delegate CtAp_TorqDamp.RTE_R_GearMgmt_ActGear_Enum <-> outer port CtAp_TorqPath_swc/RTE_R_GearMgmt_ActGear_Enum
    delegate CtAp_TrsmProtd.RTE_R_GearMgmt_ActGear_Enum <-> outer port CtAp_TorqPath_swc/RTE_R_GearMgmt_ActGear_Enum
    delegate CtAp_TorqModMap.RTE_R_GearMgmt_TarGearPInhbTq_Flg <-> outer port CtAp_TorqPath_swc/RTE_R_GearMgmt_TarGearPInhbTq_Flg
    delegate CtAp_TorqModMap.RTE_R_HvMgmt_MCUReqSts_Enum <-> outer port CtAp_TorqPath_swc/RTE_R_HvMgmt_MCUReqSts_Enum
    delegate CtAp_TorqCrossZr.RTE_R_ModMgmt_ActDrvMod_Enum <-> outer port CtAp_TorqPath_swc/RTE_R_ModMgmt_ActDrvMod_Enum
    delegate CtAp_SpdLmt.RTE_R_ModMgmt_HvSts_Enum <-> outer port CtAp_TorqPath_swc/RTE_R_ModMgmt_HvSts_Enum
    delegate CtAp_TorqCoor.RTE_R_ModMgmt_HvSts_Enum <-> outer port CtAp_TorqPath_swc/RTE_R_ModMgmt_HvSts_Enum
    delegate CtAp_TorqDamp.RTE_R_ModMgmt_HvSts_Enum <-> outer port CtAp_TorqPath_swc/RTE_R_ModMgmt_HvSts_Enum
    delegate CtAp_SpdLmt.RTE_R_VehMot_Acclr2Tq_Nm <-> outer port CtAp_TorqPath_swc/RTE_R_VehMot_Acclr2Tq_Nm
    delegate CtAp_SpdLmt.RTE_R_VehMot_VehDragTq_Nm <-> outer port CtAp_TorqPath_swc/RTE_R_VehMot_VehDragTq_Nm
    delegate CtAp_TrsmProtd.RTE_R_VehMot_VehSpd_kph <-> outer port CtAp_TorqPath_swc/RTE_R_VehMot_VehSpd_kph
    delegate CtAp_SpdLmt.RTE_R_VehMot_VehSpd_kph <-> outer port CtAp_TorqPath_swc/RTE_R_VehMot_VehSpd_kph
    delegate CtAp_TorqCoor.RTE_R_VehMot_VehSpd_kph <-> outer port CtAp_TorqPath_swc/RTE_R_VehMot_VehSpd_kph
    delegate CtAp_TorqCrossZr.RTE_R_VehMot_VehSpd_kph <-> outer port CtAp_TorqPath_swc/RTE_R_VehMot_VehSpd_kph
    delegate CtAp_SpdLmt.RTE_R_VehMot_VehSpdAcclr_mps2q <-> outer port CtAp_TorqPath_swc/RTE_R_VehMot_VehSpdAcclr_mps2q
    delegate CtAp_TorqCoor.RTE_R_VehMot_VehSpdVld_Flg <-> outer port CtAp_TorqPath_swc/RTE_R_VehMot_VehSpdVld_Flg
    delegate CtAp_SpdLmt.RTE_R_VehMot_VehSpdVld_Flg <-> outer port CtAp_TorqPath_swc/RTE_R_VehMot_VehSpdVld_Flg
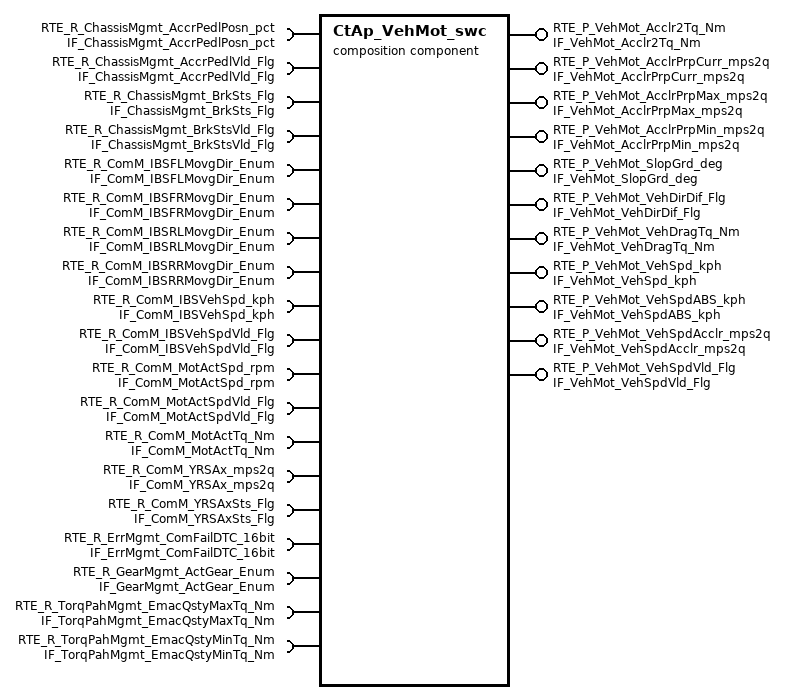
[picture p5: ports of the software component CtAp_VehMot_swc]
  composition sw component type CtAp_VehMot_swc
    11 x provide port:
      RTE_P_VehMot_Acclr2Tq_Nm: nonqueued-sender-com-spec{data-element=tec_VehMot_Acclr2Tq_Nm, init-value=0}, provided-interface=IF_VehMot_Acclr2Tq_Nm
      RTE_P_VehMot_AcclrPrpCurr_mps2q: nonqueued-sender-com-spec{data-element=tec_VehMot_AcclrPrpCurr_mps2q, init-value=0}, provided-interface=IF_VehMot_AcclrPrpCurr_mps2q
      RTE_P_VehMot_AcclrPrpMax_mps2q: nonqueued-sender-com-spec{data-element=tec_VehMot_AcclrPrpMax_mps2q, init-value=0}, provided-interface=IF_VehMot_AcclrPrpMax_mps2q
      RTE_P_VehMot_AcclrPrpMin_mps2q: nonqueued-sender-com-spec{data-element=tec_VehMot_AcclrPrpMin_mps2q, init-value=0}, provided-interface=IF_VehMot_AcclrPrpMin_mps2q
      RTE_P_VehMot_SlopGrd_deg: nonqueued-sender-com-spec{data-element=tec_VehMot_SlopGrd_deg, init-value=0}, provided-interface=IF_VehMot_SlopGrd_deg
      RTE_P_VehMot_VehDirDif_Flg: nonqueued-sender-com-spec{data-element=tec_VehMot_VehDirDif_Flg, init-value=0}, provided-interface=IF_VehMot_VehDirDif_Flg
      RTE_P_VehMot_VehDragTq_Nm: nonqueued-sender-com-spec{data-element=tec_VehMot_VehDragTq_Nm, init-value=0}, provided-interface=IF_VehMot_VehDragTq_Nm
      RTE_P_VehMot_VehSpd_kph: nonqueued-sender-com-spec{data-element=tec_VehMot_VehSpd_kph, init-value=0}, provided-interface=IF_VehMot_VehSpd_kph
      RTE_P_VehMot_VehSpdABS_kph: nonqueued-sender-com-spec{data-element=tec_VehMot_VehSpdABS_kph, init-value=0}, provided-interface=IF_VehMot_VehSpdABS_kph
      RTE_P_VehMot_VehSpdAcclr_mps2q: nonqueued-sender-com-spec{data-element=tec_VehMot_VehSpdAcclr_mps2q, init-value=0}, provided-interface=IF_VehMot_VehSpdAcclr_mps2q
      RTE_P_VehMot_VehSpdVld_Flg: nonqueued-sender-com-spec{data-element=tec_VehMot_VehSpdVld_Flg, init-value=0}, provided-interface=IF_VehMot_VehSpdVld_Flg
    19 x require port:
      RTE_R_ChassisMgmt_AccrPedlPosn_pct: nonqueued-receiver-com-spec{data-element=tec_ChassisMgmt_AccrPedlPosn_pct, filter=data-filter-type=ALWAYS, init-value=0}, required-interface=IF_ChassisMgmt_AccrPedlPosn_pct
      RTE_R_ChassisMgmt_AccrPedlVld_Flg: nonqueued-receiver-com-spec{data-element=tec_ChassisMgmt_AccrPedlVld_Flg, filter=data-filter-type=ALWAYS, init-value=0}, required-interface=IF_ChassisMgmt_AccrPedlVld_Flg
      RTE_R_ChassisMgmt_BrkSts_Flg: nonqueued-receiver-com-spec{data-element=tec_ChassisMgmt_BrkSts_Flg, filter=data-filter-type=ALWAYS, init-value=0}, required-interface=IF_ChassisMgmt_BrkSts_Flg
      RTE_R_ChassisMgmt_BrkStsVld_Flg: nonqueued-receiver-com-spec{data-element=tec_ChassisMgmt_BrkStsVld_Flg, filter=data-filter-type=ALWAYS, init-value=0}, required-interface=IF_ChassisMgmt_BrkStsVld_Flg
      RTE_R_ComM_IBSFLMovgDir_Enum: nonqueued-receiver-com-spec{data-element=tec_ComM_IBSFLMovgDir_Enum, filter=data-filter-type=ALWAYS, init-value=0}, required-interface=IF_ComM_IBSFLMovgDir_Enum
      RTE_R_ComM_IBSFRMovgDir_Enum: nonqueued-receiver-com-spec{data-element=tec_ComM_IBSFRMovgDir_Enum, filter=data-filter-type=ALWAYS, init-value=0}, required-interface=IF_ComM_IBSFRMovgDir_Enum
      RTE_R_ComM_IBSRLMovgDir_Enum: nonqueued-receiver-com-spec{data-element=tec_ComM_IBSRLMovgDir_Enum, filter=data-filter-type=ALWAYS, init-value=0}, required-interface=IF_ComM_IBSRLMovgDir_Enum
      RTE_R_ComM_IBSRRMovgDir_Enum: nonqueued-receiver-com-spec{data-element=tec_ComM_IBSRRMovgDir_Enum, filter=data-filter-type=ALWAYS, init-value=0}, required-interface=IF_ComM_IBSRRMovgDir_Enum
      RTE_R_ComM_IBSVehSpd_kph: nonqueued-receiver-com-spec{data-element=tec_ComM_IBSVehSpd_kph, filter=data-filter-type=ALWAYS, init-value=0}, required-interface=IF_ComM_IBSVehSpd_kph
      RTE_R_ComM_IBSVehSpdVld_Flg: nonqueued-receiver-com-spec{data-element=tec_ComM_IBSVehSpdVld_Flg, filter=data-filter-type=ALWAYS, init-value=0}, required-interface=IF_ComM_IBSVehSpdVld_Flg
      RTE_R_ComM_MotActSpd_rpm: nonqueued-receiver-com-spec{data-element=tec_ComM_MotActSpd_rpm, filter=data-filter-type=ALWAYS, init-value=0}, required-interface=IF_ComM_MotActSpd_rpm
      RTE_R_ComM_MotActSpdVld_Flg: nonqueued-receiver-com-spec{data-element=tec_ComM_MotActSpdVld_Flg, filter=data-filter-type=ALWAYS, init-value=0}, required-interface=IF_ComM_MotActSpdVld_Flg
      RTE_R_ComM_MotActTq_Nm: nonqueued-receiver-com-spec{data-element=tec_ComM_MotActTq_Nm, filter=data-filter-type=ALWAYS, init-value=0}, required-interface=IF_ComM_MotActTq_Nm
      RTE_R_ComM_YRSAx_mps2q: nonqueued-receiver-com-spec{data-element=tec_ComM_YRSAx_mps2q, filter=data-filter-type=ALWAYS, init-value=0}, required-interface=IF_ComM_YRSAx_mps2q
      RTE_R_ComM_YRSAxSts_Flg: nonqueued-receiver-com-spec{data-element=tec_ComM_YRSAxSts_Flg, filter=data-filter-type=ALWAYS, init-value=0}, required-interface=IF_ComM_YRSAxSts_Flg
      RTE_R_ErrMgmt_ComFailDTC_16bit: nonqueued-receiver-com-spec{data-element=tec_ErrMgmt_ComFailDTC_16bit, filter=data-filter-type=ALWAYS, init-value=0}, required-interface=IF_ErrMgmt_ComFailDTC_16bit
      RTE_R_GearMgmt_ActGear_Enum: nonqueued-receiver-com-spec{data-element=tec_GearMgmt_ActGear_Enum, filter=data-filter-type=ALWAYS, init-value=0}, required-interface=IF_GearMgmt_ActGear_Enum
      RTE_R_TorqPahMgmt_EmacQstyMaxTq_Nm: nonqueued-receiver-com-spec{data-element=tec_TorqPahMgmt_EmacQstyMaxTq_Nm, filter=data-filter-type=ALWAYS, init-value=0}, required-interface=IF_TorqPahMgmt_EmacQstyMaxTq_Nm
      RTE_R_TorqPahMgmt_EmacQstyMinTq_Nm: nonqueued-receiver-com-spec{data-element=tec_TorqPahMgmt_EmacQstyMinTq_Nm, filter=data-filter-type=ALWAYS, init-value=0}, required-interface=IF_TorqPahMgmt_EmacQstyMinTq_Nm
    4 x component:
      CtAp_AccCal: type=CtAp_AccCal
      CtAp_ResEst: type=CtAp_ResEst
      CtAp_SlopEst: type=CtAp_SlopEst
      CtAp_VehSpd: type=CtAp_VehSpd
    connect CtAp_AccCal.RTE_P_VehMot_VehSpdAcclr_mps2q -> CtAp_ResEst.RTE_R_VehMot_VehSpdAcclr_mps2q
    connect CtAp_AccCal.RTE_P_VehMot_VehSpdAcclr_mps2q -> CtAp_SlopEst.RTE_R_VehMot_VehSpdAcclr_mps2q
    connect CtAp_VehSpd.RTE_P_VehMot_VehSpd_kph -> CtAp_AccCal.RTE_R_VehMot_VehSpd_kph
    connect CtAp_VehSpd.RTE_P_VehMot_VehSpd_kph -> CtAp_ResEst.RTE_R_VehMot_VehSpd_kph
    connect CtAp_VehSpd.RTE_P_VehMot_VehSpdVld_Flg -> CtAp_ResEst.RTE_R_VehMot_VehSpdVld_Flg
    connect CtAp_VehSpd.RTE_P_VehMot_VehSpd_kph -> CtAp_SlopEst.RTE_R_VehMot_VehSpd_kph
    delegate CtAp_ResEst.RTE_P_VehMot_Acclr2Tq_Nm <-> outer port CtAp_VehMot_swc/RTE_P_VehMot_Acclr2Tq_Nm
    delegate CtAp_ResEst.RTE_P_VehMot_AcclrPrpCurr_mps2q <-> outer port CtAp_VehMot_swc/RTE_P_VehMot_AcclrPrpCurr_mps2q
    delegate CtAp_ResEst.RTE_P_VehMot_AcclrPrpMax_mps2q <-> outer port CtAp_VehMot_swc/RTE_P_VehMot_AcclrPrpMax_mps2q
    delegate CtAp_ResEst.RTE_P_VehMot_AcclrPrpMin_mps2q <-> outer port CtAp_VehMot_swc/RTE_P_VehMot_AcclrPrpMin_mps2q
    delegate CtAp_SlopEst.RTE_P_VehMot_SlopGrd_deg <-> outer port CtAp_VehMot_swc/RTE_P_VehMot_SlopGrd_deg
    delegate CtAp_VehSpd.RTE_P_VehMot_VehDirDif_Flg <-> outer port CtAp_VehMot_swc/RTE_P_VehMot_VehDirDif_Flg
    delegate CtAp_ResEst.RTE_P_VehMot_VehDragTq_Nm <-> outer port CtAp_VehMot_swc/RTE_P_VehMot_VehDragTq_Nm
    delegate CtAp_VehSpd.RTE_P_VehMot_VehSpd_kph <-> outer port CtAp_VehMot_swc/RTE_P_VehMot_VehSpd_kph
    delegate CtAp_VehSpd.RTE_P_VehMot_VehSpdABS_kph <-> outer port CtAp_VehMot_swc/RTE_P_VehMot_VehSpdABS_kph
    delegate CtAp_AccCal.RTE_P_VehMot_VehSpdAcclr_mps2q <-> outer port CtAp_VehMot_swc/RTE_P_VehMot_VehSpdAcclr_mps2q
    delegate CtAp_VehSpd.RTE_P_VehMot_VehSpdVld_Flg <-> outer port CtAp_VehMot_swc/RTE_P_VehMot_VehSpdVld_Flg
    delegate CtAp_SlopEst.RTE_R_ChassisMgmt_AccrPedlPosn_pct <-> outer port CtAp_VehMot_swc/RTE_R_ChassisMgmt_AccrPedlPosn_pct
    delegate CtAp_SlopEst.RTE_R_ChassisMgmt_AccrPedlVld_Flg <-> outer port CtAp_VehMot_swc/RTE_R_ChassisMgmt_AccrPedlVld_Flg
    delegate CtAp_ResEst.RTE_R_ChassisMgmt_BrkSts_Flg <-> outer port CtAp_VehMot_swc/RTE_R_ChassisMgmt_BrkSts_Flg
    delegate CtAp_SlopEst.RTE_R_ChassisMgmt_BrkSts_Flg <-> outer port CtAp_VehMot_swc/RTE_R_ChassisMgmt_BrkSts_Flg
    delegate CtAp_ResEst.RTE_R_ChassisMgmt_BrkStsVld_Flg <-> outer port CtAp_VehMot_swc/RTE_R_ChassisMgmt_BrkStsVld_Flg
    delegate CtAp_SlopEst.RTE_R_ChassisMgmt_BrkStsVld_Flg <-> outer port CtAp_VehMot_swc/RTE_R_ChassisMgmt_BrkStsVld_Flg
    delegate CtAp_VehSpd.RTE_R_ComM_IBSFLMovgDir_Enum <-> outer port CtAp_VehMot_swc/RTE_R_ComM_IBSFLMovgDir_Enum
    delegate CtAp_VehSpd.RTE_R_ComM_IBSFRMovgDir_Enum <-> outer port CtAp_VehMot_swc/RTE_R_ComM_IBSFRMovgDir_Enum
    delegate CtAp_VehSpd.RTE_R_ComM_IBSRLMovgDir_Enum <-> outer port CtAp_VehMot_swc/RTE_R_ComM_IBSRLMovgDir_Enum
    delegate CtAp_VehSpd.RTE_R_ComM_IBSRRMovgDir_Enum <-> outer port CtAp_VehMot_swc/RTE_R_ComM_IBSRRMovgDir_Enum
    delegate CtAp_VehSpd.RTE_R_ComM_IBSVehSpd_kph <-> outer port CtAp_VehMot_swc/RTE_R_ComM_IBSVehSpd_kph
    delegate CtAp_VehSpd.RTE_R_ComM_IBSVehSpdVld_Flg <-> outer port CtAp_VehMot_swc/RTE_R_ComM_IBSVehSpdVld_Flg
    delegate CtAp_VehSpd.RTE_R_ComM_MotActSpd_rpm <-> outer port CtAp_VehMot_swc/RTE_R_ComM_MotActSpd_rpm
    delegate CtAp_VehSpd.RTE_R_ComM_MotActSpdVld_Flg <-> outer port CtAp_VehMot_swc/RTE_R_ComM_MotActSpdVld_Flg
    delegate CtAp_ResEst.RTE_R_ComM_MotActTq_Nm <-> outer port CtAp_VehMot_swc/RTE_R_ComM_MotActTq_Nm
    delegate CtAp_AccCal.RTE_R_ComM_YRSAx_mps2q <-> outer port CtAp_VehMot_swc/RTE_R_ComM_YRSAx_mps2q
    delegate CtAp_ResEst.RTE_R_ComM_YRSAx_mps2q <-> outer port CtAp_VehMot_swc/RTE_R_ComM_YRSAx_mps2q
    delegate CtAp_SlopEst.RTE_R_ComM_YRSAx_mps2q <-> outer port CtAp_VehMot_swc/RTE_R_ComM_YRSAx_mps2q
    delegate CtAp_AccCal.RTE_R_ComM_YRSAxSts_Flg <-> outer port CtAp_VehMot_swc/RTE_R_ComM_YRSAxSts_Flg
    delegate CtAp_ResEst.RTE_R_ComM_YRSAxSts_Flg <-> outer port CtAp_VehMot_swc/RTE_R_ComM_YRSAxSts_Flg
    delegate CtAp_SlopEst.RTE_R_ComM_YRSAxSts_Flg <-> outer port CtAp_VehMot_swc/RTE_R_ComM_YRSAxSts_Flg
    delegate CtAp_VehSpd.RTE_R_ErrMgmt_ComFailDTC_16bit <-> outer port CtAp_VehMot_swc/RTE_R_ErrMgmt_ComFailDTC_16bit
    delegate CtAp_VehSpd.RTE_R_GearMgmt_ActGear_Enum <-> outer port CtAp_VehMot_swc/RTE_R_GearMgmt_ActGear_Enum
    delegate CtAp_ResEst.RTE_R_TorqPahMgmt_EmacQstyMaxTq_Nm <-> outer port CtAp_VehMot_swc/RTE_R_TorqPahMgmt_EmacQstyMaxTq_Nm
    delegate CtAp_ResEst.RTE_R_TorqPahMgmt_EmacQstyMinTq_Nm <-> outer port CtAp_VehMot_swc/RTE_R_TorqPahMgmt_EmacQstyMinTq_Nm
  44 x swc implementation:
    CtAp_ChrgEgyCal_Implementation: behavior=CtAp_ChrgEgyCal_InternalBehavior
      code-descriptors:
        code Default: artifact-descriptors=autosar-engineering-object={short-label=Default, category=SWOBJ}
    CtAp_ChrgPreHeat_Implementation: behavior=CtAp_ChrgPreHeat_InternalBehavior
      code-descriptors:
        code Default: artifact-descriptors=autosar-engineering-object={short-label=Default, category=SWOBJ}
    CtAp_ChrgSdl_Implementation: behavior=CtAp_ChrgSdl_InternalBehavior
      code-descriptors:
        code Default: artifact-descriptors=autosar-engineering-object={short-label=Default, category=SWOBJ}
    CtAp_ChrgStat_Implementation: behavior=CtAp_ChrgStat_InternalBehavior
      code-descriptors:
        code Default: artifact-descriptors=autosar-engineering-object={short-label=Default, category=SWOBJ}
    CtAp_CnsCalcn_Implementation: behavior=CtAp_CnsCalcn_InternalBehavior
      code-descriptors:
        code Default: artifact-descriptors=autosar-engineering-object={short-label=Default, category=SWOBJ}
    CtAp_CoastCtrl_Implementation: behavior=CtAp_CoastCtrl_InternalBehavior
      code-descriptors:
        code Default: artifact-descriptors=autosar-engineering-object={short-label=Default, category=SWOBJ}
    CtAp_ComMErr_Implementation: behavior=CtAp_ComMErr_InternalBehavior
      code-descriptors:
        code Default: artifact-descriptors=autosar-engineering-object={short-label=Default, category=SWOBJ}
    CtAp_CrpCtrl_Implementation: behavior=CtAp_CrpCtrl_InternalBehavior
      code-descriptors:
        code Default: artifact-descriptors=autosar-engineering-object={short-label=Default, category=SWOBJ}
    CtAp_DCDCMgmt_Implementation: behavior=CtAp_DCDCMgmt_InternalBehavior
      code-descriptors:
        code Default: artifact-descriptors=autosar-engineering-object={short-label=Default, category=SWOBJ}
    CtAp_DCFCMgmt_Implementation: behavior=CtAp_DCFCMgmt_InternalBehavior
      code-descriptors:
        code Default: artifact-descriptors=autosar-engineering-object={short-label=Default, category=SWOBJ}
    CtAp_DiagIf_Implementation: behavior=CtAp_DiagIf_InternalBehavior
      code-descriptors:
        code Default: artifact-descriptors=autosar-engineering-object={short-label=Default, category=SWOBJ}
    CtAp_DrvAsscCtrl_Implementation: behavior=CtAp_DrvAsscCtrl_InternalBehavior
      code-descriptors:
        code Default: artifact-descriptors=autosar-engineering-object={short-label=Default, category=SWOBJ}
    CtAp_DrvMod_Implementation: behavior=CtAp_DrvMod_InternalBehavior
      code-descriptors:
        code Default: artifact-descriptors=autosar-engineering-object={short-label=Default, category=SWOBJ}
    CtAp_DrvTorqCoor_Implementation: behavior=CtAp_DrvTorqCoor_InternalBehavior
      code-descriptors:
        code Default: artifact-descriptors=autosar-engineering-object={short-label=Default, category=SWOBJ}
    CtAp_ElSSDiag_Implementation: behavior=CtAp_ElSSDiag_InternalBehavior
      code-descriptors:
        code Default: artifact-descriptors=autosar-engineering-object={short-label=Default, category=SWOBJ}
    CtAp_EmMgmt_Implementation: behavior=CtAp_EmMgmt_InternalBehavior
      code-descriptors:
        code Default: artifact-descriptors=autosar-engineering-object={short-label=Default, category=SWOBJ}
    CtAp_EPBLink_Implementation: behavior=CtAp_EPBLink_InternalBehavior
      code-descriptors:
        code Default: artifact-descriptors=autosar-engineering-object={short-label=Default, category=SWOBJ}
    CtAp_FltReactn_Implementation: behavior=CtAp_FltReactn_InternalBehavior
      code-descriptors:
        code Default: artifact-descriptors=autosar-engineering-object={short-label=Default, category=SWOBJ}
    CtAp_GearCoor_Implementation: behavior=CtAp_GearCoor_InternalBehavior
      code-descriptors:
        code Default: artifact-descriptors=autosar-engineering-object={short-label=Default, category=SWOBJ}
    CtAp_GearDiag_Implementation: behavior=CtAp_GearDiag_InternalBehavior
      code-descriptors:
        code Default: artifact-descriptors=autosar-engineering-object={short-label=Default, category=SWOBJ}
    CtAp_HVSfty_Implementation: behavior=CtAp_HVSfty_InternalBehavior
      code-descriptors:
        code Default: artifact-descriptors=autosar-engineering-object={short-label=Default, category=SWOBJ}
    CtAp_LvBattMgmt_Implementation: behavior=CtAp_LvBattMgmt_InternalBehavior
      code-descriptors:
        code Default: artifact-descriptors=autosar-engineering-object={short-label=Default, category=SWOBJ}
    CtAp_ManSftGear_Implementation: behavior=CtAp_ManSftGear_InternalBehavior
      code-descriptors:
        code Default: artifact-descriptors=autosar-engineering-object={short-label=Default, category=SWOBJ}
    CtAp_MCUMgmt_Implementation: behavior=CtAp_MCUMgmt_InternalBehavior
      code-descriptors:
        code Default: artifact-descriptors=autosar-engineering-object={short-label=Default, category=SWOBJ}
    CtAp_OBCStsMgmt_Implementation: behavior=CtAp_OBCStsMgmt_InternalBehavior
      code-descriptors:
        code Default: artifact-descriptors=autosar-engineering-object={short-label=Default, category=SWOBJ}
    CtAp_OnePedCtrl_Implementation: behavior=CtAp_OnePedCtrl_InternalBehavior
      code-descriptors:
        code Default: artifact-descriptors=autosar-engineering-object={short-label=Default, category=SWOBJ}
    CtAp_PdlAlys_Implementation: behavior=CtAp_PdlAlys_InternalBehavior
      code-descriptors:
        code Default: artifact-descriptors=autosar-engineering-object={short-label=Default, category=SWOBJ}
    CtAp_PwrLim_Implementation: behavior=CtAp_PwrLim_InternalBehavior
      code-descriptors:
        code Default: artifact-descriptors=autosar-engineering-object={short-label=Default, category=SWOBJ}
    CtAp_ResEst_Implementation: behavior=CtAp_ResEst_InternalBehavior
      code-descriptors:
        code Default: artifact-descriptors=autosar-engineering-object={short-label=Default, category=SWOBJ}
    CtAp_S2Mgmt_Implementation: behavior=CtAp_S2Mgmt_InternalBehavior
      code-descriptors:
        code Default: artifact-descriptors=autosar-engineering-object={short-label=Default, category=SWOBJ}
    CtAp_SlopEst_Implementation: behavior=CtAp_SlopEst_InternalBehavior
      code-descriptors:
        code Default: artifact-descriptors=autosar-engineering-object={short-label=Default, category=SWOBJ}
    CtAp_SpdLmt_Implementation: behavior=CtAp_SpdLmt_InternalBehavior
      code-descriptors:
        code Default: artifact-descriptors=autosar-engineering-object={short-label=Default, category=SWOBJ}
    CtAp_TCUMgmt_Implementation: behavior=CtAp_TCUMgmt_InternalBehavior
      code-descriptors:
        code Default: artifact-descriptors=autosar-engineering-object={short-label=Default, category=SWOBJ}
    CtAp_TorqCoor_Implementation: behavior=CtAp_TorqCoor_InternalBehavior
      code-descriptors:
        code Default: artifact-descriptors=autosar-engineering-object={short-label=Default, category=SWOBJ}
    CtAp_TorqCrossZr_Implementation: behavior=CtAp_TorqCrossZr_InternalBehavior
      code-descriptors:
        code Default: artifact-descriptors=autosar-engineering-object={short-label=Default, category=SWOBJ}
    CtAp_TorqDamp_Implementation: behavior=CtAp_TorqDamp_InternalBehavior
      code-descriptors:
        code Default: artifact-descriptors=autosar-engineering-object={short-label=Default, category=SWOBJ}
    CtAp_TorqFil_Implementation: behavior=CtAp_TorqFil_InternalBehavior
      code-descriptors:
        code Default: artifact-descriptors=autosar-engineering-object={short-label=Default, category=SWOBJ}
    CtAp_TorqLmt_Implementation: behavior=CtAp_TorqLmt_InternalBehavior
      code-descriptors:
        code Default: artifact-descriptors=autosar-engineering-object={short-label=Default, category=SWOBJ}
    CtAp_TorqModMap_Implementation: behavior=CtAp_TorqModMap_InternalBehavior
      code-descriptors:
        code Default: artifact-descriptors=autosar-engineering-object={short-label=Default, category=SWOBJ}
    CtAp_TrsmProtd_Implementation: behavior=CtAp_TrsmProtd_InternalBehavior
      code-descriptors:
        code Default: artifact-descriptors=autosar-engineering-object={short-label=Default, category=SWOBJ}
    CtAp_VehSpd_Implementation: behavior=CtAp_VehSpd_InternalBehavior
      code-descriptors:
        code Default: artifact-descriptors=autosar-engineering-object={short-label=Default, category=SWOBJ}
    CtAp_VehStabyCtrl_Implementation: behavior=CtAp_VehStabyCtrl_InternalBehavior
      code-descriptors:
        code Default: artifact-descriptors=autosar-engineering-object={short-label=Default, category=SWOBJ}
    CtAp_VehStat_Implementation: behavior=CtAp_VehStat_InternalBehavior
      code-descriptors:
        code Default: artifact-descriptors=autosar-engineering-object={short-label=Default, category=SWOBJ}
    CtAp_WakeUpRsn_Implementation: behavior=CtAp_WakeUpRsn_InternalBehavior
      code-descriptors:
        code Default: artifact-descriptors=autosar-engineering-object={short-label=Default, category=SWOBJ}
package /PortInterfaces
  352 x sender receiver interface:
    IF_BswM_BSWWrkMod_Enum: invalidation-policy{data-element=tec_BswM_BSWWrkMod_Enum, handle-invalid=DONT-INVALIDATE}
      data tec_BswM_BSWWrkMod_Enum: type=uint8
    IF_BswM_CANWakeUp_Flg: invalidation-policy{data-element=tec_BswM_CANWakeUp_Flg, handle-invalid=DONT-INVALIDATE}
      data tec_BswM_CANWakeUp_Flg: type=boolean
    IF_BswM_DcWakeUp_Flg: invalidation-policy{data-element=tec_BswM_DcWakeUp_Flg, handle-invalid=DONT-INVALIDATE}
      data tec_BswM_DcWakeUp_Flg: type=boolean
    IF_BswM_KeyWakeUp_Flg: invalidation-policy{data-element=tec_BswM_KeyWakeUp_Flg, handle-invalid=DONT-INVALIDATE}
      data tec_BswM_KeyWakeUp_Flg: type=boolean
    IF_BswM_LinWakeUp_Flg: invalidation-policy{data-element=tec_BswM_LinWakeUp_Flg, handle-invalid=DONT-INVALIDATE}
      data tec_BswM_LinWakeUp_Flg: type=boolean
    IF_ChassisMgmt_AccrPedlDrvTq_Nm: invalidation-policy{data-element=tec_ChassisMgmt_AccrPedlDrvTq_Nm, handle-invalid=DONT-INVALIDATE}
      data tec_ChassisMgmt_AccrPedlDrvTq_Nm: type=float32
    IF_ChassisMgmt_AccrPedlFltSts_Enum: invalidation-policy{data-element=tec_ChassisMgmt_AccrPedlFltSts_Enum, handle-invalid=DONT-INVALIDATE}
      data tec_ChassisMgmt_AccrPedlFltSts_Enum: type=uint8
    IF_ChassisMgmt_AccrPedlPosn_pct: invalidation-policy{data-element=tec_ChassisMgmt_AccrPedlPosn_pct, handle-invalid=DONT-INVALIDATE}
      data tec_ChassisMgmt_AccrPedlPosn_pct: type=float32
    IF_ChassisMgmt_AccrPedlPosnRaw_pct: invalidation-policy{data-element=tec_ChassisMgmt_AccrPedlPosnRaw_pct, handle-invalid=DONT-INVALIDATE}
      data tec_ChassisMgmt_AccrPedlPosnRaw_pct: type=float32
    IF_ChassisMgmt_AccrPedlVld_Flg: invalidation-policy{data-element=tec_ChassisMgmt_AccrPedlVld_Flg, handle-invalid=DONT-INVALIDATE}
      data tec_ChassisMgmt_AccrPedlVld_Flg: type=boolean
    IF_ChassisMgmt_BrkCmpSts_Enum: invalidation-policy{data-element=tec_ChassisMgmt_BrkCmpSts_Enum, handle-invalid=DONT-INVALIDATE}
      data tec_ChassisMgmt_BrkCmpSts_Enum: type=uint8
    IF_ChassisMgmt_BrkCtrlSts_Flg: invalidation-policy{data-element=tec_ChassisMgmt_BrkCtrlSts_Flg, handle-invalid=DONT-INVALIDATE}
      data tec_ChassisMgmt_BrkCtrlSts_Flg: type=boolean
    IF_ChassisMgmt_BrkFltSts_Flg: invalidation-policy{data-element=tec_ChassisMgmt_BrkFltSts_Flg, handle-invalid=DONT-INVALIDATE}
      data tec_ChassisMgmt_BrkFltSts_Flg: type=boolean
    IF_ChassisMgmt_BrkPedlPosn_pct: invalidation-policy{data-element=tec_ChassisMgmt_BrkPedlPosn_pct, handle-invalid=DONT-INVALIDATE}
      data tec_ChassisMgmt_BrkPedlPosn_pct: type=float32
    IF_ChassisMgmt_BrkRgnActv_Flg: invalidation-policy{data-element=tec_ChassisMgmt_BrkRgnActv_Flg, handle-invalid=DONT-INVALIDATE}
      data tec_ChassisMgmt_BrkRgnActv_Flg: type=boolean
    IF_ChassisMgmt_BrkRgnTq_Nm: invalidation-policy{data-element=tec_ChassisMgmt_BrkRgnTq_Nm, handle-invalid=DONT-INVALIDATE}
      data tec_ChassisMgmt_BrkRgnTq_Nm: type=float32
    IF_ChassisMgmt_BrkSts_Flg: invalidation-policy{data-element=tec_ChassisMgmt_BrkSts_Flg, handle-invalid=DONT-INVALIDATE}
      data tec_ChassisMgmt_BrkSts_Flg: type=boolean
    IF_ChassisMgmt_BrkStsVld_Flg: invalidation-policy{data-element=tec_ChassisMgmt_BrkStsVld_Flg, handle-invalid=DONT-INVALIDATE}
      data tec_ChassisMgmt_BrkStsVld_Flg: type=boolean
    IF_ChassisMgmt_CoastCtrlActv_Flg: invalidation-policy{data-element=tec_ChassisMgmt_CoastCtrlActv_Flg, handle-invalid=DONT-INVALIDATE}
      data tec_ChassisMgmt_CoastCtrlActv_Flg: type=boolean
    IF_ChassisMgmt_CoastCtrlMCUReqSts_Enum: invalidation-policy{data-element=tec_ChassisMgmt_CoastCtrlMCUReqSts_Enum, handle-invalid=DONT-INVALIDATE}
      data tec_ChassisMgmt_CoastCtrlMCUReqSts_Enum: type=uint8
    IF_ChassisMgmt_CoastCtrlTq_Nm: invalidation-policy{data-element=tec_ChassisMgmt_CoastCtrlTq_Nm, handle-invalid=DONT-INVALIDATE}
      data tec_ChassisMgmt_CoastCtrlTq_Nm: type=float32
    IF_ChassisMgmt_CrpCtrlDesTq_Nm: invalidation-policy{data-element=tec_ChassisMgmt_CrpCtrlDesTq_Nm, handle-invalid=DONT-INVALIDATE}
      data tec_ChassisMgmt_CrpCtrlDesTq_Nm: type=float32
    IF_ChassisMgmt_DrvAsscCtrlActv_Flg: invalidation-policy{data-element=tec_ChassisMgmt_DrvAsscCtrlActv_Flg, handle-invalid=DONT-INVALIDATE}
      data tec_ChassisMgmt_DrvAsscCtrlActv_Flg: type=boolean
    IF_ChassisMgmt_DrvAsscCtrlOvrdSts_Flg: invalidation-policy{data-element=tec_ChassisMgmt_DrvAsscCtrlOvrdSts_Flg, handle-invalid=DONT-INVALIDATE}
      data tec_ChassisMgmt_DrvAsscCtrlOvrdSts_Flg: type=boolean
    IF_ChassisMgmt_DrvAsscCtrlTq_Nm: invalidation-policy{data-element=tec_ChassisMgmt_DrvAsscCtrlTq_Nm, handle-invalid=DONT-INVALIDATE}
      data tec_ChassisMgmt_DrvAsscCtrlTq_Nm: type=float32
    IF_ChassisMgmt_DrvCoorDesTq_Nm: invalidation-policy{data-element=tec_ChassisMgmt_DrvCoorDesTq_Nm, handle-invalid=DONT-INVALIDATE}
      data tec_ChassisMgmt_DrvCoorDesTq_Nm: type=float32
    IF_ChassisMgmt_DrvDmdHiPrio_Flg: invalidation-policy{data-element=tec_ChassisMgmt_DrvDmdHiPrio_Flg, handle-invalid=DONT-INVALIDATE}
      data tec_ChassisMgmt_DrvDmdHiPrio_Flg: type=boolean
    IF_ChassisMgmt_DrvrDesTq_Nm: invalidation-policy{data-element=tec_ChassisMgmt_DrvrDesTq_Nm, handle-invalid=DONT-INVALIDATE}
      data tec_ChassisMgmt_DrvrDesTq_Nm: type=float32
    IF_ChassisMgmt_IBSDesIncTq_Nm: invalidation-policy{data-element=tec_ChassisMgmt_IBSDesIncTq_Nm, handle-invalid=DONT-INVALIDATE}
      data tec_ChassisMgmt_IBSDesIncTq_Nm: type=float32
    IF_ChassisMgmt_IBSDesRednTq_Nm: invalidation-policy{data-element=tec_ChassisMgmt_IBSDesRednTq_Nm, handle-invalid=DONT-INVALIDATE}
      data tec_ChassisMgmt_IBSDesRednTq_Nm: type=float32
    IF_ChassisMgmt_IBSIntvIncTq_Nm: invalidation-policy{data-element=tec_ChassisMgmt_IBSIntvIncTq_Nm, handle-invalid=DONT-INVALIDATE}
      data tec_ChassisMgmt_IBSIntvIncTq_Nm: type=float32
    IF_ChassisMgmt_IBSIntvIncTqActv_Flg: invalidation-policy{data-element=tec_ChassisMgmt_IBSIntvIncTqActv_Flg, handle-invalid=DONT-INVALIDATE}
      data tec_ChassisMgmt_IBSIntvIncTqActv_Flg: type=boolean
    IF_ChassisMgmt_IBSIntvRednTq_Nm: invalidation-policy{data-element=tec_ChassisMgmt_IBSIntvRednTq_Nm, handle-invalid=DONT-INVALIDATE}
      data tec_ChassisMgmt_IBSIntvRednTq_Nm: type=float32
    IF_ChassisMgmt_IBSIntvRednTqActv_Flg: invalidation-policy{data-element=tec_ChassisMgmt_IBSIntvRednTqActv_Flg, handle-invalid=DONT-INVALIDATE}
      data tec_ChassisMgmt_IBSIntvRednTqActv_Flg: type=boolean
    IF_ChassisMgmt_IBSVlcReqTqAvl_Flg: invalidation-policy{data-element=tec_ChassisMgmt_IBSVlcReqTqAvl_Flg, handle-invalid=DONT-INVALIDATE}
      data tec_ChassisMgmt_IBSVlcReqTqAvl_Flg: type=boolean
    IF_ChassisMgmt_OnePedlActv_Flg: invalidation-policy{data-element=tec_ChassisMgmt_OnePedlActv_Flg, handle-invalid=DONT-INVALIDATE}
      data tec_ChassisMgmt_OnePedlActv_Flg: type=boolean
    IF_ChassisMgmt_OnePedlDesDecelSpd_mps2q: invalidation-policy{data-element=tec_ChassisMgmt_OnePedlDesDecelSpd_mps2q, handle-invalid=DONT-INVALIDATE}
      data tec_ChassisMgmt_OnePedlDesDecelSpd_mps2q: type=float32
    IF_ChassisMgmt_OnePedlDesSpd_rpm: invalidation-policy{data-element=tec_ChassisMgmt_OnePedlDesSpd_rpm, handle-invalid=DONT-INVALIDATE}
      data tec_ChassisMgmt_OnePedlDesSpd_rpm: type=float32
    IF_ChassisMgmt_OnePedlDesTq_Nm: invalidation-policy{data-element=tec_ChassisMgmt_OnePedlDesTq_Nm, handle-invalid=DONT-INVALIDATE}
      data tec_ChassisMgmt_OnePedlDesTq_Nm: type=float32
    IF_ChassisMgmt_OnePedlFltSts_Flg: invalidation-policy{data-element=tec_ChassisMgmt_OnePedlFltSts_Flg, handle-invalid=DONT-INVALIDATE}
      data tec_ChassisMgmt_OnePedlFltSts_Flg: type=boolean
    IF_ChassisMgmt_PedlAlysDTC_16bit: invalidation-policy{data-element=tec_ChassisMgmt_PedlAlysDTC_16bit, handle-invalid=DONT-INVALIDATE}
      data tec_ChassisMgmt_PedlAlysDTC_16bit: type=uint16
    IF_ChassisMgmt_SpdLmtSts_Flg: invalidation-policy{data-element=tec_ChassisMgmt_SpdLmtSts_Flg, handle-invalid=DONT-INVALIDATE}
      data tec_ChassisMgmt_SpdLmtSts_Flg: type=boolean
    IF_ChassisMgmt_VehDesDecel_mps2q: invalidation-policy{data-element=tec_ChassisMgmt_BrkCmpDesDecel_mps2q, handle-invalid=DONT-INVALIDATE}
      data tec_ChassisMgmt_BrkCmpDesDecel_mps2q: type=float32
    IF_ChgMgmt_ChrgIndcnSts_Enum: invalidation-policy{data-element=tec_ChgMgmt_ChrgIndcnSts_Enum, handle-invalid=DONT-INVALIDATE}
      data tec_ChgMgmt_ChrgIndcnSts_Enum: type=uint8
    IF_ChgMgmt_DchaAbortRsn_Enum: invalidation-policy{data-element=tec_ChgMgmt_DchaAbortRsn_Enum, handle-invalid=DONT-INVALIDATE}
      data tec_ChgMgmt_DchaAbortRsn_Enum: type=uint8
    IF_ChrgMgmt_ChrgnRemnTim_min: invalidation-policy{data-element=tec_ChrgMgmt_ChrgnRemnTim_min, handle-invalid=DONT-INVALIDATE}
      data tec_ChrgMgmt_ChrgnRemnTim_min: type=uint16
    IF_ChrMgmt_AcChrgCmplSts_Enum: invalidation-policy{data-element=tec_ChrMgmt_AcChrgCmplSts_Enum, handle-invalid=DONT-INVALIDATE}
      data tec_ChrMgmt_AcChrgCmplSts_Enum: type=uint8
    IF_ChrMgmt_BattSideSngChrgEgy_kWh: invalidation-policy{data-element=tec_ChrMgmt_BattSideSngChrgEgy_kWh, handle-invalid=DONT-INVALIDATE}
      data tec_ChrMgmt_BattSideSngChrgEgy_kWh: type=float32
    IF_ChrMgmt_ChrgPwr_kW: invalidation-policy{data-element=tec_ChrMgmt_ChrgPwr_kW, handle-invalid=DONT-INVALIDATE}
      data tec_ChrMgmt_ChrgPwr_kW: type=float32
    IF_ChrMgmt_ChrgSts_Enum: invalidation-policy{data-element=tec_ChrMgmt_ChrgSts_Enum, handle-invalid=DONT-INVALIDATE}
      data tec_ChrMgmt_ChrgSts_Enum: type=uint8
    IF_ChrMgmt_ChrgStsErrDTC_8bit: invalidation-policy{data-element=tec_ChrMgmt_ChrgStsErrDTC_8bit, handle-invalid=DONT-INVALIDATE}
      data tec_ChrMgmt_ChrgStsErrDTC_8bit: type=uint8
    IF_ChrMgmt_ChrgTim_min: invalidation-policy{data-element=tec_ChrMgmt_ChrgTim_min, handle-invalid=DONT-INVALIDATE}
      data tec_ChrMgmt_ChrgTim_min: type=uint16
    IF_ChrMgmt_DcChrgAllwd_Flg: invalidation-policy{data-element=tec_ChrMgmt_DcChrgAllwd_Flg, handle-invalid=DONT-INVALIDATE}
      data tec_ChrMgmt_DcChrgAllwd_Flg: type=boolean
    IF_ChrMgmt_DcChrgCmplSts_Enum: invalidation-policy{data-element=tec_ChrMgmt_DcChrgCmplSts_Enum, handle-invalid=DONT-INVALIDATE}
      data tec_ChrMgmt_DcChrgCmplSts_Enum: type=uint8
    IF_ChrMgmt_DcChrgrSideSngChrgEgy_kWh: invalidation-policy{data-element=tec_ChrMgmt_DcChrgrSideSngChrgEgy_kWh, handle-invalid=DONT-INVALIDATE}
      data tec_ChrMgmt_DcChrgrSideSngChrgEgy_kWh: type=float32
    IF_ChrMgmt_KeepWrm_Flg: invalidation-policy{data-element=tec_ChrMgmt_KeepWrm_Flg, handle-invalid=DONT-INVALIDATE}
      data tec_ChrMgmt_KeepWrm_Flg: type=boolean
    IF_ChrMgmt_NegRlyOpenReq_Flg: invalidation-policy{data-element=tec_ChrMgmt_NegRlyOpenReq_Flg, handle-invalid=DONT-INVALIDATE}
      data tec_ChrMgmt_NegRlyOpenReq_Flg: type=boolean
    IF_ChrMgmt_OBCCtrlMdlSts_Enum: invalidation-policy{data-element=tec_ChrMgmt_OBCCtrlMdlSts_Enum, handle-invalid=DONT-INVALIDATE}
      data tec_ChrMgmt_OBCCtrlMdlSts_Enum: type=uint8
    IF_ChrMgmt_OBCEnaAllwd_Flg: invalidation-policy{data-element=tec_ChrMgmt_OBCEnaAllwd_Flg, handle-invalid=DONT-INVALIDATE}
      data tec_ChrMgmt_OBCEnaAllwd_Flg: type=boolean
    IF_ChrMgmt_OBCSideSngChrgEgy_kWh: invalidation-policy{data-element=tec_ChrMgmt_OBCSideSngChrgEgy_kWh, handle-invalid=DONT-INVALIDATE}
      data tec_ChrMgmt_OBCSideSngChrgEgy_kWh: type=float32
    IF_ChrMgmt_OBCSideSngDchaEgy_kWh: invalidation-policy{data-element=tec_ChrMgmt_OBCSideSngDchaEgy_kWh, handle-invalid=DONT-INVALIDATE}
      data tec_ChrMgmt_OBCSideSngDchaEgy_kWh: type=float32
    IF_ChrMgmt_PlugSts_Enum: invalidation-policy{data-element=tec_ChrMgmt_PlugSts_Enum, handle-invalid=DONT-INVALIDATE}
      data tec_ChrMgmt_PlugSts_Enum: type=uint8
    IF_ChrMgmt_PODSideSngChrgEgy_kWh: invalidation-policy{data-element=tec_ChrMgmt_PODSideSngChrgEgy_kWh, handle-invalid=DONT-INVALIDATE}
      data tec_ChrMgmt_PODSideSngChrgEgy_kWh: type=float32
    IF_ChrMgmt_PreheatPODDiReq_Flg: invalidation-policy{data-element=tec_ChrMgmt_PreheatPODDiReq_Flg, handle-invalid=DONT-INVALIDATE}
      data tec_ChrMgmt_PreheatPODDiReq_Flg: type=boolean
    IF_ChrMgmt_PreheatSts_Enum: invalidation-policy{data-element=tec_ChrMgmt_PreheatSts_Enum, handle-invalid=DONT-INVALIDATE}
      data tec_ChrMgmt_PreheatSts_Enum: type=uint8
    IF_ChrMgmt_ReqHvRdy_Flg: invalidation-policy{data-element=tec_ChrMgmt_ReqHvRdy_Flg, handle-invalid=DONT-INVALIDATE}
      data tec_ChrMgmt_ReqHvRdy_Flg: type=boolean
    IF_ChrMgmt_VCUCalcdPODIDc_A: invalidation-policy{data-element=tec_ChrMgmt_VCUCalcdPODIDc_A, handle-invalid=DONT-INVALIDATE}
      data tec_ChrMgmt_VCUCalcdPODIDc_A: type=float32
    IF_ChrMgmt_VCUDispChrgI_A: invalidation-policy{data-element=tec_ChrMgmt_VCUDispChrgI_A, handle-invalid=DONT-INVALIDATE}
      data tec_ChrMgmt_VCUDispChrgI_A: type=float32
    IF_ChrMgmt_VCUDispChrgU_V: invalidation-policy{data-element=tec_ChrMgmt_VCUDispChrgU_V, handle-invalid=DONT-INVALIDATE}
      data tec_ChrMgmt_VCUDispChrgU_V: type=float32
    IF_ComM_AcChrgPha_Enum: invalidation-policy{data-element=tec_ComM_AcChrgPha_Enum, handle-invalid=DONT-INVALIDATE}
      data tec_ComM_AcChrgPha_Enum: type=uint8
    IF_ComM_ACUDrvSeatBltSts_Flg: invalidation-policy{data-element=tec_ComM_ACUDrvSeatBltSts_Flg, handle-invalid=DONT-INVALIDATE}
      data tec_ComM_ACUDrvSeatBltSts_Flg: type=boolean
    IF_ComM_ACUDrvSeatBltStsVld_Flg: invalidation-policy{data-element=tec_ComM_ACUDrvSeatBltStsVld_Flg, handle-invalid=DONT-INVALIDATE}
      data tec_ComM_ACUDrvSeatBltStsVld_Flg: type=boolean
    IF_ComM_ADCUDMSDrvExist_Flg: invalidation-policy{data-element=tec_ComM_ADCUDMSDrvrExist_Flg, handle-invalid=DONT-INVALIDATE}
      data tec_ComM_ADCUDMSDrvrExist_Flg: type=boolean
    IF_ComM_ApptChrgMdlSts_Enum: invalidation-policy{data-element=tec_ComM_ApptChrgMdlSts_Enum, handle-invalid=DONT-INVALIDATE}
      data tec_ComM_ApptChrgMdlSts_Enum: type=uint8
    IF_ComM_APTCPwrCns_Kw: invalidation-policy{data-element=tec_ComM_APTCPwrCns_Kw, handle-invalid=DONT-INVALIDATE}
      data tec_ComM_APTCPwrCns_Kw: type=float32
    IF_ComM_BattMaxTemp_C: invalidation-policy{data-element=tec_ComM_BMSBattMaxTemp_C, handle-invalid=DONT-INVALIDATE}
      data tec_ComM_BMSBattMaxTemp_C: type=sint8
    IF_ComM_BattMinTemp_C: invalidation-policy{data-element=tec_ComM_BMSBattMinTemp_C, handle-invalid=DONT-INVALIDATE}
      data tec_ComM_BMSBattMinTemp_C: type=sint8
    IF_ComM_BCMAntithftSts_Enum: invalidation-policy{data-element=tec_ComM_BCMAntithftSts_Enum, handle-invalid=DONT-INVALIDATE}
      data tec_ComM_BCMAntithftSts_Enum: type=uint8
    IF_ComM_BCMImmoSts_Enum: invalidation-policy{data-element=tec_ComM_BCMImmoSts_Enum, handle-invalid=DONT-INVALIDATE}
      data tec_ComM_BCMImmoSts_Enum: type=uint8
    IF_ComM_BMSBattAllowChrgIDc_A: invalidation-policy{data-element=tec_ComM_BMSBattAllowChrgIDc_A, handle-invalid=DONT-INVALIDATE}
      data tec_ComM_BMSBattAllowChrgIDc_A: type=float32
    IF_ComM_BMSBattDchaIDc_A: invalidation-policy{data-element=tec_ComM_BMSBattDchaIDc_A, handle-invalid=DONT-INVALIDATE}
      data tec_ComM_BMSBattDchaIDc_A: type=float32
    IF_ComM_BMSBattDispSOC_pct: invalidation-policy{data-element=tec_ComM_BMSBattDispSOC_pct, handle-invalid=DONT-INVALIDATE}
      data tec_ComM_BMSBattDispSOC_pct: type=float32
    IF_ComM_BMSBattHeatIDc_A: invalidation-policy{data-element=tec_ComM_BMSBattHeatIDc_A, handle-invalid=DONT-INVALIDATE}
      data tec_ComM_BMSBattHeatIDc_A: type=float32
    IF_ComM_BMSBattIDc_A: invalidation-policy{data-element=tec_ComM_BMSBattIDc_A, handle-invalid=DONT-INVALIDATE}
      data tec_ComM_BMSBattIDc_A: type=float32
    IF_ComM_BMSBattLnkUDc_V: invalidation-policy{data-element=tec_ComM_BMSBattLnkUDc_V, handle-invalid=DONT-INVALIDATE}
      data tec_ComM_BMSBattLnkUDc_V: type=float32
    IF_ComM_BMSBattLongChrgIDc_A: invalidation-policy{data-element=tec_ComM_BMSBattLongChrgIDc_A, handle-invalid=DONT-INVALIDATE}
      data tec_ComM_BMSBattLongChrgIDc_A: type=float32
    IF_ComM_BMSBattLongDchaIDc_A: invalidation-policy{data-element=tec_ComM_BMSBattLongDchaIDc_A, handle-invalid=DONT-INVALIDATE}
      data tec_ComM_BMSBattLongDchaIDc_A: type=float32
    IF_ComM_BMSBattPckUDc_V: invalidation-policy{data-element=tec_ComM_BMSBattPckUDc_V, handle-invalid=DONT-INVALIDATE}
      data tec_ComM_BMSBattPckUDc_V: type=float32
    IF_ComM_BMSBattRateCp_Ah: invalidation-policy{data-element=tec_ComM_BMSBattRateCp_Ah, handle-invalid=DONT-INVALIDATE}
      data tec_ComM_BMSBattRateCp_Ah: type=float32
    IF_ComM_BMSBattShoChrgIDc_A: invalidation-policy{data-element=tec_ComM_BMSBattShoChrgIDc_A, handle-invalid=DONT-INVALIDATE}
      data tec_ComM_BMSBattShoChrgIDc_A: type=float32
    IF_ComM_BMSBattShoDchaIDc_A: invalidation-policy{data-element=tec_ComM_BMSBattShoDchaIDc_A, handle-invalid=DONT-INVALIDATE}
      data tec_ComM_BMSBattShoDchaIDc_A: type=float32
    IF_ComM_BMSBattSOCLow_Flg: invalidation-policy{data-element=tec_ComM_BMSBattSOCLow_Flg, handle-invalid=DONT-INVALIDATE}
      data tec_ComM_BMSBattSOCLow_Flg: type=boolean
    IF_ComM_BMSBattUDc_V: invalidation-policy{data-element=tec_ComM_BMSBattUDc_V, handle-invalid=DONT-INVALIDATE}
      data tec_ComM_BMSBattUDc_V: type=float32
    IF_ComM_BMSChrgCmplSts_Enum: invalidation-policy{data-element=tec_ComM_BMSChrgCmplSts_Enum, handle-invalid=DONT-INVALIDATE}
      data tec_ComM_BMSChrgCmplSts_Enum: type=uint8
    IF_ComM_BMSChrgReqSts_Enum: invalidation-policy{data-element=tec_ComM_BMSChrgReqSts_Enum, handle-invalid=DONT-INVALIDATE}
      data tec_ComM_BMSChrgReqSts_Enum: type=uint8
    IF_ComM_BMSChrgSts_Enum: invalidation-policy{data-element=tec_ComM_BMSChrgSts_Enum, handle-invalid=DONT-INVALIDATE}
      data tec_ComM_BMSChrgSts_Enum: type=uint8
    IF_ComM_BMSKeepWrmReq_Enum: invalidation-policy{data-element=tec_ComM_BMSKeepWrmReq_Enum, handle-invalid=DONT-INVALIDATE}
      data tec_ComM_BMSKeepWrmReq_Enum: type=uint8
    IF_ComM_BMSNegRlySts_Enum: invalidation-policy{data-element=tec_ComM_BMSNegRlySts_Enum, handle-invalid=DONT-INVALIDATE}
      data tec_ComM_BMSNegRlySts_Enum: type=uint8
    IF_ComM_BMSPosRlySts_Enum: invalidation-policy{data-element=tec_ComM_BMSPosRlySts_Enum, handle-invalid=DONT-INVALIDATE}
      data tec_ComM_BMSPosRlySts_Enum: type=uint8
    IF_ComM_BMSRemnChrgTim_min: invalidation-policy{data-element=tec_ComM_BMSRemnChrgTim_min, handle-invalid=DONT-INVALIDATE}
      data tec_ComM_BMSRemnChrgTim_min: type=uint16
    IF_ComM_BMSRTCReq_Flg: invalidation-policy{data-element=tec_ComM_BMSRTCReq_Flg, handle-invalid=DONT-INVALIDATE}
      data tec_ComM_BMSRTCReq_Flg: type=boolean
    IF_ComM_BMSSts_Enum: invalidation-policy{data-element=tec_ComM_BMSSts_Enum, handle-invalid=DONT-INVALIDATE}
      data tec_ComM_BMSSts_Enum: type=uint8
    IF_ComM_BMSWrkMod_Enum: invalidation-policy{data-element=tec_ComM_BMSWrkMod_Enum, handle-invalid=DONT-INVALIDATE}
      data tec_ComM_BMSWrkMod_Enum: type=uint8
    IF_ComM_CCSOutpIDc_A: invalidation-policy{data-element=tec_ComM_CCSOutpIDc_A, handle-invalid=DONT-INVALIDATE}
      data tec_ComM_CCSOutpIDc_A: type=float32
    IF_ComM_CCSOutpUDc_V: invalidation-policy{data-element=tec_ComM_CCSOutpUDc_V, handle-invalid=DONT-INVALIDATE}
      data tec_ComM_CCSOutpUDc_V: type=float32
    IF_ComM_CMLMaxOutpIDc_A: invalidation-policy{data-element=tec_ComM_CMLMaxOutpIDc_A, handle-invalid=DONT-INVALIDATE}
      data tec_ComM_CMLMaxOutpIDc_A: type=float32
    IF_ComM_CustSetVehSpd_kph: invalidation-policy{data-element=tec_ComM_IVISetFwdVehSpd_kph, handle-invalid=DONT-INVALIDATE}
      data tec_ComM_IVISetFwdVehSpd_kph: type=float32
    IF_ComM_DCDCActLvUDc_V: invalidation-policy{data-element=tec_ComM_DCDCActLvUDc_V, handle-invalid=DONT-INVALIDATE}
      data tec_ComM_DCDCActLvUDc_V: type=float32
    IF_ComM_DCDCHvInpIDc_A: invalidation-policy{data-element=tec_ComM_DCDCHvInpIDc_A, handle-invalid=DONT-INVALIDATE}
      data tec_ComM_DCDCHvInpIDc_A: type=float32
    IF_ComM_DCDCHvInpUDc_V: invalidation-policy{data-element=tec_ComM_DCDCHvInpUDc_V, handle-invalid=DONT-INVALIDATE}
      data tec_ComM_DCDCHvInpUDc_V: type=float32
    IF_ComM_DCDCWrkMod_Enum: invalidation-policy{data-element=tec_ComM_DCDCWrkMod_Enum, handle-invalid=DONT-INVALIDATE}
      data tec_ComM_DCDCWrkMod_Enum: type=uint8
    IF_ComM_DchaSwtSts_Enum: invalidation-policy{data-element=tec_ComM_DchaSwtSts_Enum, handle-invalid=DONT-INVALIDATE}
      data tec_ComM_DchaSwtSts_Enum: type=uint8
    IF_ComM_DCMFLDoorSts_Flg: invalidation-policy{data-element=tec_ComM_DCMFLDoorSts_Flg, handle-invalid=DONT-INVALIDATE}
      data tec_ComM_DCMFLDoorSts_Flg: type=boolean
    IF_ComM_ElectcLockSts_Enum: invalidation-policy{data-element=tec_ComM_ElectcLockSts_Enum, handle-invalid=DONT-INVALIDATE}
      data tec_ComM_ElectcLockSts_Enum: type=uint8
    IF_ComM_EPBWrkSts_Enum: invalidation-policy{data-element=tec_ComM_EPBWrkSts_Enum, handle-invalid=DONT-INVALIDATE}
      data tec_ComM_EPBWrkSts_Enum: type=uint8
    IF_ComM_EVCOMActPwrCns_Kw: invalidation-policy{data-element=tec_ComM_EVCOMActPwrCns_Kw, handle-invalid=DONT-INVALIDATE}
      data tec_ComM_EVCOMActPwrCns_Kw: type=float32
    IF_ComM_GearPBtn_Enum: invalidation-policy{data-element=tec_ComM_GearPBtn_Enum, handle-invalid=DONT-INVALIDATE}
      data tec_ComM_GearPBtn_Enum: type=uint8
    IF_ComM_GearPBtnFltSts_Flg: invalidation-policy{data-element=tec_ComM_GearPBtnFltSts_Flg, handle-invalid=DONT-INVALIDATE}
      data tec_ComM_GearPBtnFltSts_Flg: type=boolean
    IF_ComM_GearRNDBtn_Enum: invalidation-policy{data-element=tec_ComM_GearRNDBtn_Enum, handle-invalid=DONT-INVALIDATE}
      data tec_ComM_GearRNDBtn_Enum: type=uint8
    IF_ComM_GearRNDBtnFltSts_Flg: invalidation-policy{data-element=tec_ComM_GearRNDBtnFltSts_Flg, handle-invalid=DONT-INVALIDATE}
      data tec_ComM_GearRNDBtnFltSts_Flg: type=boolean
    IF_ComM_HVCHIDc_A: invalidation-policy{data-element=tec_ComM_HVCHIDc_A, handle-invalid=DONT-INVALIDATE}
      data tec_ComM_HVCHIDc_A: type=float32
    IF_ComM_HVCHUDc_V: invalidation-policy{data-element=tec_ComM_HVCHUDc_V, handle-invalid=DONT-INVALIDATE}
      data tec_ComM_HVCHUDc_V: type=float32
    IF_ComM_IBSAbpActv_Flg: invalidation-policy{data-element=tec_ComM_IBSAbpActv_Flg, handle-invalid=DONT-INVALIDATE}
      data tec_ComM_IBSAbpActv_Flg: type=boolean
    IF_ComM_IBSAbsActv_Flg: invalidation-policy{data-element=tec_ComM_IBSAbsActv_Flg, handle-invalid=DONT-INVALIDATE}
      data tec_ComM_IBSAbsActv_Flg: type=boolean
    IF_ComM_IBSAebActv_Flg: invalidation-policy{data-element=tec_ComM_IBSAebActv_Flg, handle-invalid=DONT-INVALIDATE}
      data tec_ComM_IBSAebActv_Flg: type=boolean
    IF_ComM_IBSApaModSts_Enum: invalidation-policy{data-element=tec_ComM_IBSApaModSts_Enum, handle-invalid=DONT-INVALIDATE}
      data tec_ComM_IBSApaModSts_Enum: type=uint8
    IF_ComM_IBSApaReqTq_Nm: invalidation-policy{data-element=tec_ComM_IBSApaReqTq_Nm, handle-invalid=DONT-INVALIDATE}
      data tec_ComM_IBSApaReqTq_Nm: type=float32
    IF_ComM_IBSApaReqTqVld_Flg: invalidation-policy{data-element=tec_ComM_IBSApaReqTqVld_Flg, handle-invalid=DONT-INVALIDATE}
      data tec_ComM_IBSApaReqTqVld_Flg: type=boolean
    IF_ComM_IBSBattChrgWakeUp_Flg: invalidation-policy{data-element=tec_ComM_IBSBattChrgWakeUp_Flg, handle-invalid=DONT-INVALIDATE}
      data tec_ComM_IBSBattChrgWakeUp_Flg: type=boolean
    IF_ComM_IBSBattDchaWakeUp_Flg: invalidation-policy{data-element=tec_ComM_IBSBattDchaWakeUp_Flg, handle-invalid=DONT-INVALIDATE}
      data tec_ComM_IBSBattDchaWakeUp_Flg: type=boolean
    IF_ComM_IBSBattIDc_A: invalidation-policy{data-element=tec_ComM_IBSBattIDc_A, handle-invalid=DONT-INVALIDATE}
      data tec_ComM_IBSBattIDc_A: type=float32
    IF_ComM_IBSBattSOC_pct: invalidation-policy{data-element=tec_ComM_IBSBattSOC_pct, handle-invalid=DONT-INVALIDATE}
      data tec_ComM_IBSBattSOC_pct: type=float32
    IF_ComM_IBSBattSOCWakeUp_Flg: invalidation-policy{data-element=tec_ComM_IBSBattSOCWakeUp_Flg, handle-invalid=DONT-INVALIDATE}
      data tec_ComM_IBSBattSOCWakeUp_Flg: type=boolean
    IF_ComM_IBSBattTemp_C: invalidation-policy{data-element=tec_ComM_IBSBattTemp_C, handle-invalid=DONT-INVALIDATE}
      data tec_ComM_IBSBattTemp_C: type=float32
    IF_ComM_IBSBattUDc_V: invalidation-policy{data-element=tec_ComM_IBSBattUDc_V, handle-invalid=DONT-INVALIDATE}
      data tec_ComM_IBSBattUDc_V: type=float32
    IF_ComM_IBSBrkMstCylPrs_pct: invalidation-policy{data-element=tec_ComM_IBSBrkMstCylPrs_pct, handle-invalid=DONT-INVALIDATE}
      data tec_ComM_IBSBrkMstCylPrs_pct: type=float32
    IF_ComM_IBSBrkPlgrPrs_pct: invalidation-policy{data-element=tec_ComM_IBSBrkPlgrPrs_pct, handle-invalid=DONT-INVALIDATE}
      data tec_ComM_IBSBrkPlgrPrs_pct: type=float32
    IF_ComM_IBSBrkSts_Enum: invalidation-policy{data-element=tec_ComM_IBSBrkSts_Enum, handle-invalid=DONT-INVALIDATE}
      data tec_ComM_IBSBrkSts_Enum: type=uint8
    IF_ComM_IBSDtcActv_Flg: invalidation-policy{data-element=tec_ComM_IBSDtcActv_Flg, handle-invalid=DONT-INVALIDATE}
      data tec_ComM_IBSDtcActv_Flg: type=boolean
    IF_ComM_IBSDtcFlt_Flg: invalidation-policy{data-element=tec_ComM_IBSDtcFlt_Flg, handle-invalid=DONT-INVALIDATE}
      data tec_ComM_IBSDtcFlt_Flg: type=boolean
    IF_ComM_IBSFLMovgDir_Enum: invalidation-policy{data-element=tec_ComM_IBSFLMovgDir_Enum, handle-invalid=DONT-INVALIDATE}
      data tec_ComM_IBSFLMovgDir_Enum: type=uint8
    IF_ComM_IBSFRMovgDir_Enum: invalidation-policy{data-element=tec_ComM_IBSFRMovgDir_Enum, handle-invalid=DONT-INVALIDATE}
      data tec_ComM_IBSFRMovgDir_Enum: type=uint8
    IF_ComM_IBSHdcSts_Enum: invalidation-policy{data-element=tec_ComM_IBSHdcSts_Enum, handle-invalid=DONT-INVALIDATE}
      data tec_ComM_IBSHdcSts_Enum: type=uint8
    IF_ComM_IBSRbsReqTq_Nm: invalidation-policy{data-element=tec_ComM_IBSRbsReqTq_Nm, handle-invalid=DONT-INVALIDATE}
      data tec_ComM_IBSRbsReqTq_Nm: type=float32
    IF_ComM_IBSRbsReqTqVld_Flg: invalidation-policy{data-element=tec_ComM_IBSRbsReqTqVld_Flg, handle-invalid=DONT-INVALIDATE}
      data tec_ComM_IBSRbsReqTqVld_Flg: type=boolean
    IF_ComM_IBSRbsSts_Enum: invalidation-policy{data-element=tec_ComM_IBSRbsSts_Enum, handle-invalid=DONT-INVALIDATE}
      data tec_ComM_IBSRbsSts_Enum: type=uint8
    IF_ComM_IBSReqIncTq_Nm: invalidation-policy{data-element=tec_ComM_IBSReqIncTq_Nm, handle-invalid=DONT-INVALIDATE}
      data tec_ComM_IBSReqIncTq_Nm: type=float32
    IF_ComM_IBSReqIncTqVld_Flg: invalidation-policy{data-element=tec_ComM_IBSReqIncTqVld_Flg, handle-invalid=DONT-INVALIDATE}
      data tec_ComM_IBSReqIncTqVld_Flg: type=boolean
    IF_ComM_IBSReqRednTq_Nm: invalidation-policy{data-element=tec_ComM_IBSReqRednTq_Nm, handle-invalid=DONT-INVALIDATE}
      data tec_ComM_IBSReqRednTq_Nm: type=float32
    IF_ComM_IBSReqRednTqVld_Flg: invalidation-policy{data-element=tec_ComM_IBSReqRednTqVld_Flg, handle-invalid=DONT-INVALIDATE}
      data tec_ComM_IBSReqRednTqVld_Flg: type=boolean
    IF_ComM_IBSRLMovgDir_Enum: invalidation-policy{data-element=tec_ComM_IBSRLMovgDir_Enum, handle-invalid=DONT-INVALIDATE}
      data tec_ComM_IBSRLMovgDir_Enum: type=uint8
    IF_ComM_IBSRLSpd_kph: invalidation-policy{data-element=tec_ComM_IBSRLSpd_kph, handle-invalid=DONT-INVALIDATE}
      data tec_ComM_IBSRLSpd_kph: type=float32
    IF_ComM_IBSRLSpdVld_Flg: invalidation-policy{data-element=tec_ComM_IBSRLSpdVld_Flg, handle-invalid=DONT-INVALIDATE}
      data tec_ComM_IBSRLSpdVld_Flg: type=boolean
    IF_ComM_IBSRRMovgDir_Enum: invalidation-policy{data-element=tec_ComM_IBSRRMovgDir_Enum, handle-invalid=DONT-INVALIDATE}
      data tec_ComM_IBSRRMovgDir_Enum: type=uint8
    IF_ComM_IBSRrSpd_kph: invalidation-policy{data-element=tec_ComM_IBSRRSpd_kph, handle-invalid=DONT-INVALIDATE}
      data tec_ComM_IBSRRSpd_kph: type=float32
    IF_ComM_IBSRRSpdVld_Flg: invalidation-policy{data-element=tec_ComM_IBSRRSpdVld_Flg, handle-invalid=DONT-INVALIDATE}
      data tec_ComM_IBSRRSpdVld_Flg: type=boolean
    IF_ComM_IBSRwuActv_Flg: invalidation-policy{data-element=tec_ComM_IBSRwuActv_Flg, handle-invalid=DONT-INVALIDATE}
      data tec_ComM_IBSRwuActv_Flg: type=boolean
    IF_ComM_IBSTarGearReq_Enum: invalidation-policy{data-element=tec_ComM_IBSTarGearReq_Enum, handle-invalid=DONT-INVALIDATE}
      data tec_ComM_IBSTarGearReq_Enum: type=uint8
    IF_ComM_IBSTcsActv_Flg: invalidation-policy{data-element=tec_ComM_IBSTcsActv_Flg, handle-invalid=DONT-INVALIDATE}
      data tec_ComM_IBSTcsActv_Flg: type=boolean
    IF_ComM_IBSTcsFlt_Flg: invalidation-policy{data-element=tec_ComM_IBSTcsFlt_Flg, handle-invalid=DONT-INVALIDATE}
      data tec_ComM_IBSTcsFlt_Flg: type=boolean
    IF_ComM_IBSVdcActv_Flg: invalidation-policy{data-element=tec_ComM_IBSVdcActv_Flg, handle-invalid=DONT-INVALIDATE}
      data tec_ComM_IBSVdcActv_Flg: type=boolean
    IF_ComM_IBSVdcFlt_Flg: invalidation-policy{data-element=tec_ComM_IBSVdcFlt_Flg, handle-invalid=DONT-INVALIDATE}
      data tec_ComM_IBSVdcFlt_Flg: type=boolean
    IF_ComM_IBSVehSpd_kph: invalidation-policy{data-element=tec_ComM_IBSVehSpd_kph, handle-invalid=DONT-INVALIDATE}
      data tec_ComM_IBSVehSpd_kph: type=float32
    IF_ComM_IBSVehSpdVld_Flg: invalidation-policy{data-element=tec_ComM_IBSVehSpdVld_Flg, handle-invalid=DONT-INVALIDATE}
      data tec_ComM_IBSVehSpdVld_Flg: type=boolean
    IF_ComM_IBSVlcActv_Flg: invalidation-policy{data-element=tec_ComM_IBSVlcActv_Flg, handle-invalid=DONT-INVALIDATE}
      data tec_ComM_IBSVlcActv_Flg: type=boolean
    IF_ComM_IBSVlcReqTq_Nm: invalidation-policy{data-element=tec_ComM_IBSVlcReqTq_Nm, handle-invalid=DONT-INVALIDATE}
      data tec_ComM_IBSVlcReqTq_Nm: type=float32
    IF_ComM_IBSVlcReqTqVld_Flg: invalidation-policy{data-element=tec_ComM_IBSVlcReqTqVld_Flg, handle-invalid=DONT-INVALIDATE}
      data tec_ComM_IBSVlcReqTqVld_Flg: type=boolean
    IF_ComM_IVIAcclrLvlSts_Enum: invalidation-policy{data-element=tec_ComM_IVIAcclrLvlSts_Enum, handle-invalid=DONT-INVALIDATE}
      data tec_ComM_IVIAcclrLvlSts_Enum: type=uint8
    IF_ComM_IVIChrgCmd_Enum: invalidation-policy{data-element=tec_ComM_IVIChrgCmd_Enum, handle-invalid=DONT-INVALIDATE}
      data tec_ComM_IVIChrgCmd_Enum: type=uint8
    IF_ComM_IVIDrvModSet_Enum: invalidation-policy{data-element=tec_ComM_IVIDrvModSet_Enum, handle-invalid=DONT-INVALIDATE}
      data tec_ComM_IVIDrvModSet_Enum: type=uint8
    IF_ComM_IVIEnaBrkCmpMod_Enum: invalidation-policy{data-element=tec_ComM_IVIEnaBrkCmpMod_Enum, handle-invalid=DONT-INVALIDATE}
      data tec_ComM_IVIEnaBrkCmpMod_Enum: type=uint8
    IF_ComM_IVIEnaOnePedlMod_Enum: invalidation-policy{data-element=tec_ComM_IVIEnaOnePedlMod_Enum, handle-invalid=DONT-INVALIDATE}
      data tec_ComM_IVIEnaOnePedlMod_Enum: type=uint8
    IF_ComM_IVIFwdMaxVehSpdLmtSwt_Enum: invalidation-policy{data-element=tec_ComM_IVIFwdMaxVehSpdLmtSwt_Enum, handle-invalid=DONT-INVALIDATE}
      data tec_ComM_IVIFwdMaxVehSpdLmtSwt_Enum: type=uint8
    IF_ComM_IVIGearReq_Enum: invalidation-policy{data-element=tec_ComM_IVIGearReq_Enum, handle-invalid=DONT-INVALIDATE}
      data tec_ComM_IVIGearReq_Enum: type=uint8
    IF_ComM_IVIPrecReq_Flg: invalidation-policy{data-element=tec_ComM_IVIPrecReq_Flg, handle-invalid=DONT-INVALIDATE}
      data tec_ComM_IVIPrecReq_Flg: type=boolean
    IF_ComM_IVIPreheatReq_Flg: invalidation-policy{data-element=tec_ComM_IVIPreheatReq_Flg, handle-invalid=DONT-INVALIDATE}
      data tec_ComM_IVIPreheatReq_Flg: type=boolean
    IF_ComM_IVIReqElectcLock_Enum: invalidation-policy{data-element=tec_ComM_IVIReqElectcLock_Enum, handle-invalid=DONT-INVALIDATE}
      data tec_ComM_IVIReqElectcLock_Enum: type=uint8
    IF_ComM_MaxChrgSOCSet_Enum: invalidation-policy{data-element=tec_ComM_MaxChrgSOCSet_Enum, handle-invalid=DONT-INVALIDATE}
      data tec_ComM_MaxChrgSOCSet_Enum: type=uint8
    IF_ComM_MCUIDc_A: invalidation-policy{data-element=tec_ComM_MCUIDc_A, handle-invalid=DONT-INVALIDATE}
      data tec_ComM_MCUIDc_A: type=float32
    IF_ComM_MCUUDc_V: invalidation-policy{data-element=tec_ComM_MCUUDc_V, handle-invalid=DONT-INVALIDATE}
      data tec_ComM_MCUUDc_V: type=float32
    IF_ComM_MCUWrkMod_Enum: invalidation-policy{data-element=tec_ComM_MCUWrkMod_Enum, handle-invalid=DONT-INVALIDATE}
      data tec_ComM_MCUWrkMod_Enum: type=uint8
    IF_ComM_MinDchaSOCSet_Enum: invalidation-policy{data-element=tec_ComM_MinDchaSOCSet_Enum, handle-invalid=DONT-INVALIDATE}
      data tec_ComM_MinDchaSOCSet_Enum: type=uint8
    IF_ComM_MotActSpd_rpm: invalidation-policy{data-element=tec_ComM_MotActSpd_rpm, handle-invalid=DONT-INVALIDATE}
      data tec_ComM_MotActSpd_rpm: type=sint16
    IF_ComM_MotActSpdVld_Flg: invalidation-policy{data-element=tec_ComM_MotActSpdVld_Flg, handle-invalid=DONT-INVALIDATE}
      data tec_ComM_MotActSpdVld_Flg: type=boolean
    IF_ComM_MotActTq_Nm: invalidation-policy{data-element=tec_ComM_MotActTq_Nm, handle-invalid=DONT-INVALIDATE}
      data tec_ComM_MotActTq_Nm: type=float32
    IF_ComM_MotMaxTq_Nm: invalidation-policy{data-element=tec_ComM_MotMaxTq_Nm, handle-invalid=DONT-INVALIDATE}
      data tec_ComM_MotMaxTq_Nm: type=float32
    IF_ComM_MotMinTq_Nm: invalidation-policy{data-element=tec_ComM_MotMinTq_Nm, handle-invalid=DONT-INVALIDATE}
      data tec_ComM_MotMinTq_Nm: type=float32
    IF_ComM_OBCCCIDcLmt_A: invalidation-policy{data-element=tec_ComM_OBCCCIDcLmt_A, handle-invalid=DONT-INVALIDATE}
      data tec_ComM_OBCCCIDcLmt_A: type=float32
    IF_ComM_OBCCCSts_Enum: invalidation-policy{data-element=tec_ComM_OBCCCSts_Enum, handle-invalid=DONT-INVALIDATE}
      data tec_ComM_OBCCCSts_Enum: type=uint8
    IF_ComM_OBCChrgOutpPwrAvl_Kw: invalidation-policy{data-element=tec_ComM_OBCChrgOutpPwrAvl_Kw, handle-invalid=DONT-INVALIDATE}
      data tec_ComM_OBCChrgOutpPwrAvl_Kw: type=float32
    IF_ComM_OBCChrgSts_Enum: invalidation-policy{data-element=tec_ComM_OBCChrgSts_Enum, handle-invalid=DONT-INVALIDATE}
      data tec_ComM_OBCChrgSts_Enum: type=uint8
    IF_ComM_OBCCPIDcLmt_A: invalidation-policy{data-element=tec_ComM_OBCCPIDcLmt_A, handle-invalid=DONT-INVALIDATE}
      data tec_ComM_OBCCPIDcLmt_A: type=float32
    IF_ComM_OBCCPPwmDuty_pct: invalidation-policy{data-element=tec_ComM_OBCCPPwmDuty_pct, handle-invalid=DONT-INVALIDATE}
      data tec_ComM_OBCCPPwmDuty_pct: type=uint8
    IF_ComM_OBCCPSts_Enum: invalidation-policy{data-element=tec_ComM_OBCCPSts_Enum, handle-invalid=DONT-INVALIDATE}
      data tec_ComM_OBCCPSts_Enum: type=uint8
    IF_ComM_OBCDCOutpIDc_A: invalidation-policy{data-element=tec_ComM_OBCDCOutpIDc_A, handle-invalid=DONT-INVALIDATE}
      data tec_ComM_OBCDCOutpIDc_A: type=float32
    IF_ComM_OBCInpIAc_A: invalidation-policy{data-element=tec_ComM_OBCInpIAc_A, handle-invalid=DONT-INVALIDATE}
      data tec_ComM_OBCInpIAc_A: type=float32
    IF_ComM_OBCInpUAc_V: invalidation-policy{data-element=tec_ComM_OBCInpUAc_V, handle-invalid=DONT-INVALIDATE}
      data tec_ComM_OBCInpUAc_V: type=float32
    IF_ComM_OBCMaxAllwdIDc_A: invalidation-policy{data-element=tec_ComM_OBCMaxAllwdIDc_A, handle-invalid=DONT-INVALIDATE}
      data tec_ComM_OBCMaxAllwdIDc_A: type=float32
    IF_ComM_OBCOutpIDc_A: invalidation-policy{data-element=tec_ComM_OBCOutpIDc_A, handle-invalid=DONT-INVALIDATE}
      data tec_ComM_OBCOutpIDc_A: type=float32
    IF_ComM_OBCOutpUDc_V: invalidation-policy{data-element=tec_ComM_OBCOutpUDc_V, handle-invalid=DONT-INVALIDATE}
      data tec_ComM_OBCOutpUDc_V: type=float32
    IF_ComM_PEPSPwrMod_Enum: invalidation-policy{data-element=tec_ComM_PEPSPwrMod_Enum, handle-invalid=DONT-INVALIDATE}
      data tec_ComM_PEPSPwrMod_Enum: type=uint8
    IF_ComM_PODDCFCUDc_V: invalidation-policy{data-element=tec_ComM_PODDCFCUDc_V, handle-invalid=DONT-INVALIDATE}
      data tec_ComM_PODDCFCUDc_V: type=float32
    IF_ComM_PODDcNegRlySts_Enum: invalidation-policy{data-element=tec_ComM_PODDcNegRlySts_Enum, handle-invalid=DONT-INVALIDATE}
      data tec_ComM_PODDcNegRlySts_Enum: type=uint8
    IF_ComM_PODDcPosRlySts_Enum: invalidation-policy{data-element=tec_ComM_PODDcPosRlySts_Enum, handle-invalid=DONT-INVALIDATE}
      data tec_ComM_PODDcPosRlySts_Enum: type=uint8
    IF_ComM_S2SwtSts_Enum: invalidation-policy{data-element=tec_ComM_S2SwtSts_Enum, handle-invalid=DONT-INVALIDATE}
      data tec_ComM_S2SwtSts_Enum: type=uint8
    IF_ComM_SGWAcReq_Flg: invalidation-policy{data-element=tec_ComM_SGWAcReq_Flg, handle-invalid=DONT-INVALIDATE}
      data tec_ComM_SGWAcReq_Flg: type=boolean
    IF_ComM_SGWChrgCmd_Enum: invalidation-policy{data-element=tec_ComM_SGWChrgCmd_Enum, handle-invalid=DONT-INVALIDATE}
      data tec_ComM_SGWChrgCmd_Enum: type=uint8
    IF_ComM_SGWRemHvCtrlReq_Enum: invalidation-policy{data-element=tec_ComM_SGWRemHvCtrlReq_Enum, handle-invalid=DONT-INVALIDATE}
      data tec_ComM_SGWRemHvCtrlReq_Enum: type=uint8
    IF_ComM_SGWSysRdyReq_Flg: invalidation-policy{data-element=tec_ComM_SGWSysRdyReq_Flg, handle-invalid=DONT-INVALIDATE}
      data tec_ComM_SGWSysRdyReq_Flg: type=boolean
    IF_ComM_SGWWakeUpReq_Flg: invalidation-policy{data-element=tec_ComM_SGWWakeUpReq_Flg, handle-invalid=DONT-INVALIDATE}
      data tec_ComM_SGWWakeUpReq_Flg: type=boolean
    IF_ComM_SysIRVal_kOhm: invalidation-policy{data-element=tec_ComM_SysIRVal_kOhm, handle-invalid=DONT-INVALIDATE}
      data tec_ComM_SysIRVal_kOhm: type=uint16
    IF_ComM_TMSTotPwrCns_Kw: invalidation-policy{data-element=tec_ComM_TMSTotPwrCns_Kw, handle-invalid=DONT-INVALIDATE}
      data tec_ComM_TMSTotPwrCns_Kw: type=float32
    IF_ComM_TMSTotPwrReq_Kw: invalidation-policy{data-element=tec_ComM_TMSTotPwrReq_Kw, handle-invalid=DONT-INVALIDATE}
      data tec_ComM_TMSTotPwrReq_Kw: type=float32
    IF_ComM_YRSAx_mps2q: invalidation-policy{data-element=tec_ComM_YRSAx_mps2q, handle-invalid=DONT-INVALIDATE}
      data tec_ComM_YRSAx_mps2q: type=float32
    IF_ComM_YRSAxSts_Flg: invalidation-policy{data-element=tec_ComM_YRSAxSts_Flg, handle-invalid=DONT-INVALIDATE}
      data tec_ComM_YRSAxSts_Flg: type=boolean
    IF_DCChrg_DCFCClsReq_Flg: invalidation-policy{data-element=tec_DCChrg_DCFCClsReq_Flg, handle-invalid=DONT-INVALIDATE}
      data tec_DCChrg_DCFCClsReq_Flg: type=boolean
    IF_DCChrMgmt_DcChrgnMod_Enum: invalidation-policy{data-element=tec_DCChrMgmt_DcChrgnMod_Enum, handle-invalid=DONT-INVALIDATE}
      data tec_DCChrMgmt_DcChrgnMod_Enum: type=uint8
    IF_DCChrMgmt_DcChrgnSts_Enum: invalidation-policy{data-element=tec_DCChrMgmt_DcChrgnSts_Enum, handle-invalid=DONT-INVALIDATE}
      data tec_DCChrMgmt_DcChrgnSts_Enum: type=uint8
    IF_EgyMgmt_BattChrgIDcLmt_A: invalidation-policy{data-element=tec_EgyMgmt_BattChrgIDcLmt_A, handle-invalid=DONT-INVALIDATE}
      data tec_EgyMgmt_BattChrgIDcLmt_A: type=float32
    IF_EgyMgmt_BMSBattChrgIDcLmt_A: invalidation-policy{data-element=tec_EgyMgmt_BMSBattChrgIDcLmt_A, handle-invalid=DONT-INVALIDATE}
      data tec_EgyMgmt_BMSBattChrgIDcLmt_A: type=float32
    IF_EgyMgmt_DCDCPwrCnsCalcn_Kw: invalidation-policy{data-element=tec_EgyMgmt_DCDCPwrCnsCalcn_Kw, handle-invalid=DONT-INVALIDATE}
      data tec_EgyMgmt_DCDCPwrCnsCalcn_Kw: type=float32
    IF_EgyMgmt_DCDCPwrLmt_Kw: invalidation-policy{data-element=tec_EgyMgmt_DCDCPwrLmt_Kw, handle-invalid=DONT-INVALIDATE}
      data tec_EgyMgmt_DCDCPwrLmt_Kw: type=float32
    IF_EgyMgmt_KeepWrmIDcLmt_A: invalidation-policy{data-element=tec_EgyMgmt_KeepWrmIDcLmt_A, handle-invalid=DONT-INVALIDATE}
      data tec_EgyMgmt_KeepWrmIDcLmt_A: type=float32
    IF_EgyMgmt_MCULongChrgPwrLmt_Kw: invalidation-policy{data-element=tec_EgyMgmt_MCULongChrgPwrLmt_Kw, handle-invalid=DONT-INVALIDATE}
      data tec_EgyMgmt_MCULongChrgPwrLmt_Kw: type=float32
    IF_EgyMgmt_MCULongDchaPwrLmt_Kw: invalidation-policy{data-element=tec_EgyMgmt_MCULongDchaPwrLmt_Kw, handle-invalid=DONT-INVALIDATE}
      data tec_EgyMgmt_MCULongDchaPwrLmt_Kw: type=float32
    IF_EgyMgmt_MCUPwrCnsCalcn_Kw: invalidation-policy{data-element=tec_EgyMgmt_MCUPwrCnsCalcn_Kw, handle-invalid=DONT-INVALIDATE}
      data tec_EgyMgmt_MCUPwrCnsCalcn_Kw: type=float32
    IF_EgyMgmt_MCUShoChrgPwrLmt_Kw: invalidation-policy{data-element=tec_EgyMgmt_MCUShoChrgPwrLmt_Kw, handle-invalid=DONT-INVALIDATE}
      data tec_EgyMgmt_MCUShoChrgPwrLmt_Kw: type=float32
    IF_EgyMgmt_MCUShoDchaPwrLmt_Kw: invalidation-policy{data-element=tec_EgyMgmt_MCUShoDchaPwrLmt_Kw, handle-invalid=DONT-INVALIDATE}
      data tec_EgyMgmt_MCUShoDchaPwrLmt_Kw: type=float32
    IF_EgyMgmt_OBCDchaPwrLmt_Kw: invalidation-policy{data-element=tec_EgyMgmt_OBCDchaPwrLmt_Kw, handle-invalid=DONT-INVALIDATE}
      data tec_EgyMgmt_OBCDchaPwrLmt_Kw: type=float32
    IF_EgyMgmt_PackPTCPwrCnsCalcn_Kw: invalidation-policy{data-element=tec_EgyMgmt_PackPTCPwrCnsCalcn_Kw, handle-invalid=DONT-INVALIDATE}
      data tec_EgyMgmt_PackPTCPwrCnsCalcn_Kw: type=float32
    IF_EgyMgmt_PermtPckPTC_Flg: invalidation-policy{data-element=tec_EgyMgmt_PermtPckPTC_Flg, handle-invalid=DONT-INVALIDATE}
      data tec_EgyMgmt_PermtPckPTC_Flg: type=boolean
    IF_EgyMgmt_PreheatIDcLmt_A: invalidation-policy{data-element=tec_EgyMgmt_PreheatIDcLmt_A, handle-invalid=DONT-INVALIDATE}
      data tec_EgyMgmt_PreheatIDcLmt_A: type=float32
    IF_EgyMgmt_TCUPwrAllwd_Kw: invalidation-policy{data-element=tec_EgyMgmt_TCUPwrAllwd_Kw, handle-invalid=DONT-INVALIDATE}
      data tec_EgyMgmt_TCUPwrAllwd_Kw: type=float32
    IF_EgyMgmt_TCUPwrCnsCalcn_Kw: invalidation-policy{data-element=tec_EgyMgmt_TCUPwrCnsCalcn_Kw, handle-invalid=DONT-INVALIDATE}
      data tec_EgyMgmt_TCUPwrCnsCalcn_Kw: type=float32
    IF_EgyMgmt_V2LPwrCnsCalcn_Kw: invalidation-policy{data-element=IF_EgyMgmt_V2LPwrCnsCalcn_Kw, handle-invalid=DONT-INVALIDATE}
      data IF_EgyMgmt_V2LPwrCnsCalcn_Kw: type=float32
    IF_ErrMgmt_ChassisCtrl_8bit: invalidation-policy{data-element=tec_ErrMgmt_ChassisCtrl_8bit, handle-invalid=DONT-INVALIDATE}
      data tec_ErrMgmt_ChassisCtrl_8bit: type=uint8
    IF_ErrMgmt_ChrgCtrl_8bit: invalidation-policy{data-element=tec_ErrMgmt_ChrgCtrl_8bit, handle-invalid=DONT-INVALIDATE}
      data tec_ErrMgmt_ChrgCtrl_8bit: type=uint8
    IF_ErrMgmt_ComFailDTC_16bit: invalidation-policy{data-element=tec_ErrMgmt_ComFailDTC_16bit, handle-invalid=DONT-INVALIDATE}
      data tec_ErrMgmt_ComFailDTC_16bit: type=uint16
    IF_ErrMgmt_HvCtrl_8bit: invalidation-policy{data-element=tec_ErrMgmt_HvCtrl_8bit, handle-invalid=DONT-INVALIDATE}
      data tec_ErrMgmt_HvCtrl_8bit: type=uint8
    IF_ErrMgmt_OBCMesgLoss_Flg: invalidation-policy{data-element=tec_ErrMgmt_OBCMesgLoss_Flg, handle-invalid=DONT-INVALIDATE}
      data tec_ErrMgmt_OBCMesgLoss_Flg: type=boolean
    IF_ErrMgmt_TqCtrl_8bit: invalidation-policy{data-element=tec_ErrMgmt_TqCtrl_8bit, handle-invalid=DONT-INVALIDATE}
      data tec_ErrMgmt_TqCtrl_8bit: type=uint8
    IF_ErrMgmt_VehSpdLmt_8bit: invalidation-policy{data-element=tec_ErrMgmt_VehSpdLmt_8bit, handle-invalid=DONT-INVALIDATE}
      data tec_ErrMgmt_VehSpdLmt_8bit: type=uint8
    IF_ErrMgmt_VehSpdLmt_kph: invalidation-policy{data-element=tec_ErrMgmt_VehSpdLmt_kph, handle-invalid=DONT-INVALIDATE}
      data tec_ErrMgmt_VehSpdLmt_kph: type=float32
    IF_GearMgmt_ActGear_Enum: invalidation-policy{data-element=tec_GearMgmt_ActGear_Enum, handle-invalid=DONT-INVALIDATE}
      data tec_GearMgmt_ActGear_Enum: type=uint8
    IF_GearMgmt_AllowGearShift_Enum: invalidation-policy{data-element=tec_GearMgmt_AllowGearShift_Enum, handle-invalid=DONT-INVALIDATE}
      data tec_GearMgmt_AllowGearShift_Enum: type=uint8
    IF_GearMgmt_AllowGearShift2P_Flg: invalidation-policy{data-element=tec_GearMgmt_AllowGearShift2P_Flg, handle-invalid=DONT-INVALIDATE}
      data tec_GearMgmt_AllowGearShift2P_Flg: type=boolean
    IF_GearMgmt_AllowGearShiftWait_Enum: invalidation-policy{data-element=tec_GearMgmt_AllowGearShiftWait_Enum, handle-invalid=DONT-INVALIDATE}
      data tec_GearMgmt_AllowGearShiftWait_Enum: type=uint8
    IF_GearMgmt_AutoNReq_Flg: invalidation-policy{data-element=tec_GearMgmt_AutoNReq_Flg, handle-invalid=DONT-INVALIDATE}
      data tec_GearMgmt_AutoNReq_Flg: type=boolean
    IF_GearMgmt_AutoPNSts_Flg: invalidation-policy{data-element=tec_GearMgmt_AutoPNSts_Flg, handle-invalid=DONT-INVALIDATE}
      data tec_GearMgmt_AutoPNSts_Flg: type=boolean
    IF_GearMgmt_AutoPReq_Flg: invalidation-policy{data-element=tec_GearMgmt_AutoPReq_Flg, handle-invalid=DONT-INVALIDATE}
      data tec_GearMgmt_AutoPReq_Flg: type=boolean
    IF_GearMgmt_EPBPrkReq_Flg: invalidation-policy{data-element=tec_GearMgmt_EPBPrkReq_Flg, handle-invalid=DONT-INVALIDATE}
      data tec_GearMgmt_EPBPrkReq_Flg: type=boolean
    IF_GearMgmt_EPBPrkReqCmpl_Flg: invalidation-policy{data-element=tec_GearMgmt_EPBPrkReqCmpl_Flg, handle-invalid=DONT-INVALIDATE}
      data tec_GearMgmt_EPBPrkReqCmpl_Flg: type=boolean
    IF_GearMgmt_EPBPrkReqFail_Flg: invalidation-policy{data-element=tec_GearMgmt_EPBPrkReqFail_Flg, handle-invalid=DONT-INVALIDATE}
      data tec_GearMgmt_EPBPrkReqFail_Flg: type=boolean
    IF_GearMgmt_EPBPrkType_Enum: invalidation-policy{data-element=tec_GearMgmt_EPBPrkType_Enum, handle-invalid=DONT-INVALIDATE}
      data tec_GearMgmt_EPBPrkType_Enum: type=uint8
    IF_GearMgmt_EPBRelsReq_Flg: invalidation-policy{data-element=tec_GearMgmt_EPBRelsReq_Flg, handle-invalid=DONT-INVALIDATE}
      data tec_GearMgmt_EPBRelsReq_Flg: type=boolean
    IF_GearMgmt_EPBRelsReqCmpl_Flg: invalidation-policy{data-element=tec_GearMgmt_EPBRelsReqCmpl_Flg, handle-invalid=DONT-INVALIDATE}
      data tec_GearMgmt_EPBRelsReqCmpl_Flg: type=boolean
    IF_GearMgmt_EPBRelsReqFail_Flg: invalidation-policy{data-element=tec_GearMgmt_EPBRelsReqFail_Flg, handle-invalid=DONT-INVALIDATE}
      data tec_GearMgmt_EPBRelsReqFail_Flg: type=boolean
    IF_GearMgmt_InPlugDetd_Flg: invalidation-policy{data-element=tec_GearMgmt_InPlugDetd_Flg, handle-invalid=DONT-INVALIDATE}
      data tec_GearMgmt_InPlugDetd_Flg: type=boolean
    IF_GearMgmt_InvldGearSel_Enum: invalidation-policy{data-element=tec_GearMgmt_InvldGearSel_Enum, handle-invalid=DONT-INVALIDATE}
      data tec_GearMgmt_InvldGearSel_Enum: type=uint8
    IF_GearMgmt_NotP2PReq_Flg: invalidation-policy{data-element=tec_GearMgmt_NotP2PReq_Flg, handle-invalid=DONT-INVALIDATE}
      data tec_GearMgmt_NotP2PReq_Flg: type=boolean
    IF_GearMgmt_P2NReq_Flg: invalidation-policy{data-element=tec_GearMgmt_P2NReq_Flg, handle-invalid=DONT-INVALIDATE}
      data tec_GearMgmt_P2NReq_Flg: type=boolean
    IF_GearMgmt_TarGear_Enum: invalidation-policy{data-element=tec_GearMgmt_TarGear_Enum, handle-invalid=DONT-INVALIDATE}
      data tec_GearMgmt_TarGear_Enum: type=uint8
    IF_GearMgmt_TarGearPInhbTq_Flg: invalidation-policy{data-element=tec_GearMgmt_TarGearPInhbTq_Flg, handle-invalid=DONT-INVALIDATE}
      data tec_GearMgmt_TarGearPInhbTq_Flg: type=boolean
    IF_GearMgmt_TarGearShift_Enum: invalidation-policy{data-element=tec_GearMgmt_TarGearShift_Enum, handle-invalid=DONT-INVALIDATE}
      data tec_GearMgmt_TarGearShift_Enum: type=uint8
    IF_GearMgmt_WakeUpEPBReq_Flg: invalidation-policy{data-element=tec_GearMgmt_WakeUpEPBReq_Flg, handle-invalid=DONT-INVALIDATE}
      data tec_GearMgmt_WakeUpEPBReq_Flg: type=boolean
    IF_GearMgmt_WakeUpFinish_Flg: invalidation-policy{data-element=tec_GearMgmt_WakeUpFinish_Flg, handle-invalid=DONT-INVALIDATE}
      data tec_GearMgmt_WakeUpFinish_Flg: type=boolean
    IF_HvMgmt_BMSDTC_8bit: invalidation-policy{data-element=tec_HvMgmt_BMSDTC_8bit, handle-invalid=DONT-INVALIDATE}
      data tec_HvMgmt_BMSDTC_8bit: type=uint8
    IF_HvMgmt_BMSNegRlyActSts_Enum: invalidation-policy{data-element=tec_HvMgmt_BMSNegRlyActSts_Enum, handle-invalid=DONT-INVALIDATE}
      data tec_HvMgmt_BMSNegRlyActSts_Enum: type=uint8
    IF_HvMgmt_BMSNegRlyCtrlReq_Flg: invalidation-policy{data-element=tec_HvMgmt_BMSNegRlyCtrlReq_Flg, handle-invalid=DONT-INVALIDATE}
      data tec_HvMgmt_BMSNegRlyCtrlReq_Flg: type=boolean
    IF_HvMgmt_BMSNormHvDwnReq_Flg: invalidation-policy{data-element=tec_HvMgmt_BMSNormHvDwnReq_Flg, handle-invalid=DONT-INVALIDATE}
      data tec_HvMgmt_BMSNormHvDwnReq_Flg: type=boolean
    IF_HvMgmt_BMSPosRlyActSts_Enum: invalidation-policy{data-element=tec_HvMgmt_BMSPosRlyActSts_Enum, handle-invalid=DONT-INVALIDATE}
      data tec_HvMgmt_BMSPosRlyActSts_Enum: type=uint8
    IF_HvMgmt_BMSWrkModActSts_Enum: invalidation-policy{data-element=tec_HvMgmt_BMSWrkModActSts_Enum, handle-invalid=DONT-INVALIDATE}
      data tec_HvMgmt_BMSWrkModActSts_Enum: type=uint8
    IF_HvMgmt_DCDCDmdLvUDc_V: invalidation-policy{data-element=tec_HvMgmt_DCDCDmdLvUDc_V, handle-invalid=DONT-INVALIDATE}
      data tec_HvMgmt_DCDCDmdLvUDc_V: type=float32
    IF_HvMgmt_DCDCDTC_8bit: invalidation-policy{data-element=tec_HvMgmt_DCDCDTC_8bit, handle-invalid=DONT-INVALIDATE}
      data tec_HvMgmt_DCDCDTC_8bit: type=uint8
    IF_HvMgmt_DCDCWrkModActSts_Enum: invalidation-policy{data-element=tec_HvMgmt_DCDCWrkModActSts_Enum, handle-invalid=DONT-INVALIDATE}
      data tec_HvMgmt_DCDCWrkModActSts_Enum: type=uint8
    IF_HvMgmt_DCFCDTC_8bit: invalidation-policy{data-element=tec_HvMgmt_DCFCDTC_8bit, handle-invalid=DONT-INVALIDATE}
      data tec_HvMgmt_DCFCDTC_8bit: type=uint8
    IF_HvMgmt_DCFCReqSts_Flg: invalidation-policy{data-element=tec_HvMgmt_DCFCReqSts_Flg, handle-invalid=DONT-INVALIDATE}
      data tec_HvMgmt_DCFCReqSts_Flg: type=boolean
    IF_HvMgmt_DCFCWrkModActSts_Enum: invalidation-policy{data-element=tec_HvMgmt_DCFCWrkModActSts_Enum, handle-invalid=DONT-INVALIDATE}
      data tec_HvMgmt_DCFCWrkModActSts_Enum: type=uint8
    IF_HvMgmt_MCUDTC_8bit: invalidation-policy{data-element=tec_HvMgmt_MCUDTC_8bit, handle-invalid=DONT-INVALIDATE}
      data tec_HvMgmt_MCUDTC_8bit: type=uint8
    IF_HvMgmt_MCUReqSts_Enum: invalidation-policy{data-element=tec_HvMgmt_MCUReqSts_Enum, handle-invalid=DONT-INVALIDATE}
      data tec_HvMgmt_MCUReqSts_Enum: type=uint8
    IF_HvMgmt_MCUWrkModActSts_Enum: invalidation-policy{data-element=tec_HvMgmt_MCUWrkModActSts_Enum, handle-invalid=DONT-INVALIDATE}
      data tec_HvMgmt_MCUWrkModActSts_Enum: type=uint8
    IF_HvMgmt_ReqDCDCMod_Enum: invalidation-policy{data-element=tec_HvMgmt_ReqDCDCMod_Enum, handle-invalid=DONT-INVALIDATE}
      data tec_HvMgmt_ReqDCDCMod_Enum: type=uint8
    IF_HvMgmt_ReqModBMS_Flg: invalidation-policy{data-element=tec_HvMgmt_ReqModBMS_Flg, handle-invalid=DONT-INVALIDATE}
      data tec_HvMgmt_ReqModBMS_Flg: type=boolean
    IF_HvMgmt_ReqTCUMod_Enum: invalidation-policy{data-element=tec_HvMgmt_ReqTCUMod_Enum, handle-invalid=DONT-INVALIDATE}
      data tec_HvMgmt_ReqTCUMod_Enum: type=uint8
    IF_HvMgmt_TCUDTC_8bit: invalidation-policy{data-element=tec_HvMgmt_TCUDTC_8bit, handle-invalid=DONT-INVALIDATE}
      data tec_HvMgmt_TCUDTC_8bit: type=uint8
    IF_HvMgmt_TCUWrkModActSts_Enum: invalidation-policy{data-element=tec_HvMgmt_TCUWrkModActSts_Enum, handle-invalid=DONT-INVALIDATE}
      data tec_HvMgmt_TCUWrkModActSts_Enum: type=uint8
    IF_IOAbs_AccrPedlMaiRaw_mV: invalidation-policy{data-element=tec_IOAbs_AccrPedlMaiRaw_mV, handle-invalid=DONT-INVALIDATE}
      data tec_IOAbs_AccrPedlMaiRaw_mV: type=uint16
    IF_IOAbs_AccrPedlRdnRaw_mV: invalidation-policy{data-element=tec_IOAbs_AccrPedlRdnRaw_mV, handle-invalid=DONT-INVALIDATE}
      data tec_IOAbs_AccrPedlRdnRaw_mV: type=uint16
    IF_IOAbs_BrkMaiRaw_Flg: invalidation-policy{data-element=tec_IOAbs_BrkMaiRaw_Flg, handle-invalid=DONT-INVALIDATE}
      data tec_IOAbs_BrkMaiRaw_Flg: type=boolean
    IF_IOAbs_BrkRdnRaw_Flg: invalidation-policy{data-element=tec_IOAbs_BrkRdnRaw_Flg, handle-invalid=DONT-INVALIDATE}
      data tec_IOAbs_BrkRdnRaw_Flg: type=boolean
    IF_IOAbs_CC2SigUDc_mV: invalidation-policy{data-element=tec_IOAbs_CC2SigUDc_mV, handle-invalid=DONT-INVALIDATE}
      data tec_IOAbs_CC2SigUDc_mV: type=uint16
    IF_IOAbs_KL15Fb_Flg: invalidation-policy{data-element=tec_IOAbs_KL15Fb_Flg, handle-invalid=DONT-INVALIDATE}
      data tec_IOAbs_KL15Fb_Flg: type=boolean
    IF_LvMgmt_EISSDiagDTC_8bit: invalidation-policy{data-element=tec_LvMgmt_EISSDiagDTC_8bit, handle-invalid=DONT-INVALIDATE}
      data tec_LvMgmt_EISSDiagDTC_8bit: type=uint8
    IF_LvMgmt_IBSBattDiagSts_Enum: invalidation-policy{data-element=tec_LvMgmt_IBSBattDiagSts_Enum, handle-invalid=DONT-INVALIDATE}
      data tec_LvMgmt_IBSBattDiagSts_Enum: type=uint8
    IF_LvMgmt_IBSBattReChrgReq_Flg: invalidation-policy{data-element=tec_LvMgmt_IBSBattReChrgReq_Flg, handle-invalid=DONT-INVALIDATE}
      data tec_LvMgmt_IBSBattReChrgReq_Flg: type=boolean
    IF_LvMgmt_KL15ActSts_Flg: invalidation-policy{data-element=tec_LvMgmt_KL15ActSts_Flg, handle-invalid=DONT-INVALIDATE}
      data tec_LvMgmt_KL15ActSts_Flg: type=boolean
    IF_LvMgmt_KL15CtrlReq_Flg: invalidation-policy{data-element=tec_LvMgmt_KL15CtrlReq_Flg, handle-invalid=DONT-INVALIDATE}
      data tec_LvMgmt_KL15CtrlReq_Flg: type=boolean
    IF_LvMgmt_LvBattMgmtDiagDTC_8bit: invalidation-policy{data-element=tec_LvMgmt_LvBattMgmtDiagDTC_8bit, handle-invalid=DONT-INVALIDATE}
      data tec_LvMgmt_LvBattMgmtDiagDTC_8bit: type=uint8
    IF_LvMgmt_LvPwrDwn_Flg: invalidation-policy{data-element=tec_LvMgmt_LvPwrDwn_Flg, handle-invalid=DONT-INVALIDATE}
      data tec_LvMgmt_LvPwrDwn_Flg: type=boolean
    IF_LvMgmt_SelfChkSts_Flg: invalidation-policy{data-element=tec_LvMgmt_SelfChkSts_Flg, handle-invalid=DONT-INVALIDATE}
      data tec_LvMgmt_SelfChkSts_Flg: type=boolean
    IF_LvMgmt_StayInRun_Flg: invalidation-policy{data-element=tec_LvMgmt_StayInRun_Flg, handle-invalid=DONT-INVALIDATE}
      data tec_LvMgmt_StayInRun_Flg: type=boolean
    IF_LvMgmt_WakeUpReq_Flg: invalidation-policy{data-element=tec_LvMgmt_WakeUpReq_Flg, handle-invalid=DONT-INVALIDATE}
      data tec_LvMgmt_WakeUpReq_Flg: type=boolean
    IF_LvMgmt_WakeUpSrc_Enum: invalidation-policy{data-element=tec_LvMgmt_WakeUpSrc_Enum, handle-invalid=DONT-INVALIDATE}
      data tec_LvMgmt_WakeUpSrc_Enum: type=uint8
    IF_ModMgmt_ActDrvMod_Enum: invalidation-policy{data-element=tec_ModMgmt_ActDrvMod_Enum, handle-invalid=DONT-INVALIDATE}
      data tec_ModMgmt_ActDrvMod_Enum: type=uint8
    IF_ModMgmt_DrvModSwtWarn_Flg: invalidation-policy{data-element=tec_ModMgmt_DrvModSwtWarn_Flg, handle-invalid=DONT-INVALIDATE}
      data tec_ModMgmt_DrvModSwtWarn_Flg: type=boolean
    IF_ModMgmt_HvSts_Enum: invalidation-policy{data-element=tec_ModMgmt_HvSts_Enum, handle-invalid=DONT-INVALIDATE}
      data tec_ModMgmt_HvSts_Enum: type=uint8
    IF_ModMgmt_ReqSleep_Flg: invalidation-policy{data-element=tec_ModMgmt_ReqSleep_Flg, handle-invalid=DONT-INVALIDATE}
      data tec_ModMgmt_ReqSleep_Flg: type=boolean
    IF_ModMgmt_RstCtrl_Flg: invalidation-policy{data-element=tec_ModMgmt_RstCtrl_Flg, handle-invalid=DONT-INVALIDATE}
      data tec_ModMgmt_RstCtrl_Flg: type=boolean
    IF_ModMgmt_SysRdy_Enum: invalidation-policy{data-element=tec_ModMgmt_SysRdy_Enum, handle-invalid=DONT-INVALIDATE}
      data tec_ModMgmt_SysRdy_Enum: type=uint8
    IF_OBCMgmt_AcChrgnSts_Enum: invalidation-policy{data-element=tec_OBCMgmt_AcChrgnSts_Enum, handle-invalid=DONT-INVALIDATE}
      data tec_OBCMgmt_AcChrgnSts_Enum: type=uint8
    IF_OBCMgmt_ElectcLockCtrlCmd_Enum: invalidation-policy{data-element=tec_OBCMgmt_ElectcLockCtrlCmd_Enum, handle-invalid=DONT-INVALIDATE}
      data tec_OBCMgmt_ElectcLockCtrlCmd_Enum: type=uint8
    IF_OBCMgmt_ElectcLockCtrlSts_Enum: invalidation-policy{data-element=tec_OBCMgmt_ElectcLockCtrlSts_Enum, handle-invalid=DONT-INVALIDATE}
      data tec_OBCMgmt_ElectcLockCtrlSts_Enum: type=uint8
    IF_OBCMgmt_ElectcLockStatErrDTC_8bit: invalidation-policy{data-element=tec_OBCMgmt_ElectcLockStatErrDTC_8bit, handle-invalid=DONT-INVALIDATE}
      data tec_OBCMgmt_ElectcLockStatErrDTC_8bit: type=uint8
    IF_OBCMgmt_MnyUnlckCmt_Enum: invalidation-policy{data-element=tec_OBCMgmt_MnyUnlckCmt_Enum, handle-invalid=DONT-INVALIDATE}
      data tec_OBCMgmt_MnyUnlckCmt_Enum: type=uint8
    IF_OBCMgmt_OBCCtrlErrDTC_8bit: invalidation-policy{data-element=tec_OBCMgmt_OBCCtrlErrDTC_8bit, handle-invalid=DONT-INVALIDATE}
      data tec_OBCMgmt_OBCCtrlErrDTC_8bit: type=uint8
    IF_OBCMgmt_OBCEnaCmd_Enum: invalidation-policy{data-element=tec_OBCMgmt_OBCEnaCmd_Enum, handle-invalid=DONT-INVALIDATE}
      data tec_OBCMgmt_OBCEnaCmd_Enum: type=uint8
    IF_OBCMgmt_OBCOutpCpbyIDc_A: invalidation-policy{data-element=tec_OBCMgmt_OBCOutpCpbyIDc_A, handle-invalid=DONT-INVALIDATE}
      data tec_OBCMgmt_OBCOutpCpbyIDc_A: type=float32
    IF_OBCMgmt_ReqOBCIDc_A: invalidation-policy{data-element=tec_OBCMgmt_ReqOBCIDc_A, handle-invalid=DONT-INVALIDATE}
      data tec_OBCMgmt_ReqOBCIDc_A: type=float32
    IF_OBCMgmt_S2SwtCtrlCmd_Enum: invalidation-policy{data-element=tec_OBCMgmt_S2SwtCtrlCmd_Enum, handle-invalid=DONT-INVALIDATE}
      data tec_OBCMgmt_S2SwtCtrlCmd_Enum: type=uint8
    IF_OBCMgmt_S2SwtCtrlErrDTC_8bit: invalidation-policy{data-element=tec_OBCMgmt_S2SwtCtrlErrDTC_8bit, handle-invalid=DONT-INVALIDATE}
      data tec_OBCMgmt_S2SwtCtrlErrDTC_8bit: type=uint8
    IF_OBCMgmt_S2SwtCtrlSts_Enum: invalidation-policy{data-element=tec_OBCMgmt_S2SwtCtrlSts_Enum, handle-invalid=DONT-INVALIDATE}
      data tec_OBCMgmt_S2SwtCtrlSts_Enum: type=uint8
    IF_TorqPahMgmt_DesCoorTq_Nm: invalidation-policy{data-element=tec_TorqPahMgmt_DesCoorTq_Nm, handle-invalid=DONT-INVALIDATE}
      data tec_TorqPahMgmt_DesCoorTq_Nm: type=float32
    IF_TorqPahMgmt_DesFildTq_Nm: invalidation-policy{data-element=tec_TorqPahMgmt_DesFildTq_Nm, handle-invalid=DONT-INVALIDATE}
      data tec_TorqPahMgmt_DesFildTq_Nm: type=float32
    IF_TorqPahMgmt_DesLpFildTq_Nm: invalidation-policy{data-element=tec_TorqPahMgmt_DesLpFildTq_Nm, handle-invalid=DONT-INVALIDATE}
      data tec_TorqPahMgmt_DesLpFildTq_Nm: type=float32
    IF_TorqPahMgmt_DesMotSpd_rpm: invalidation-policy{data-element=tec_TorqPahMgmt_DesMotSpd_rpm, handle-invalid=DONT-INVALIDATE}
      data tec_TorqPahMgmt_DesMotSpd_rpm: type=float32
    IF_TorqPahMgmt_DesMotTq_Nm: invalidation-policy{data-element=tec_TorqPahMgmt_DesMotTq_Nm, handle-invalid=DONT-INVALIDATE}
      data tec_TorqPahMgmt_DesMotTq_Nm: type=float32
    IF_TorqPahMgmt_EmacDynMaxTq_Nm: invalidation-policy{data-element=tec_TorqPahMgmt_EmacDynMaxTq_Nm, handle-invalid=DONT-INVALIDATE}
      data tec_TorqPahMgmt_EmacDynMaxTq_Nm: type=float32
    IF_TorqPahMgmt_EmacDynMinTq_Nm: invalidation-policy{data-element=tec_TorqPahMgmt_EmacDynMinTq_Nm, handle-invalid=DONT-INVALIDATE}
      data tec_TorqPahMgmt_EmacDynMinTq_Nm: type=float32
    IF_TorqPahMgmt_EmacQstyMaxTq_Nm: invalidation-policy{data-element=tec_TorqPahMgmt_EmacQstyMaxTq_Nm, handle-invalid=DONT-INVALIDATE}
      data tec_TorqPahMgmt_EmacQstyMaxTq_Nm: type=float32
    IF_TorqPahMgmt_EmacQstyMinTq_Nm: invalidation-policy{data-element=tec_TorqPahMgmt_EmacQstyMinTq_Nm, handle-invalid=DONT-INVALIDATE}
      data tec_TorqPahMgmt_EmacQstyMinTq_Nm: type=float32
    IF_TorqPahMgmt_FwdMaxSpdSts_Flg: invalidation-policy{data-element=tec_TorqPahMgmt_FwdMaxSpdSts_Flg, handle-invalid=DONT-INVALIDATE}
      data tec_TorqPahMgmt_FwdMaxSpdSts_Flg: type=boolean
    IF_TorqPahMgmt_FwdMaxVehSpd_kph: invalidation-policy{data-element=tec_TorqPahMgmt_FwdMaxVehSpd_kph, handle-invalid=DONT-INVALIDATE}
      data tec_TorqPahMgmt_FwdMaxVehSpd_kph: type=float32
    IF_TorqPahMgmt_IBSIntvTqSts_Enum: invalidation-policy{data-element=tec_TorqPahMgmt_IBSIntvTqSts_Enum, handle-invalid=DONT-INVALIDATE}
      data tec_TorqPahMgmt_IBSIntvTqSts_Enum: type=uint8
    IF_TorqPahMgmt_ReqMotDampSts_Enum: invalidation-policy{data-element=tec_TorqPahMgmt_ReqMotDampSts_Enum, handle-invalid=DONT-INVALIDATE}
      data tec_TorqPahMgmt_ReqMotDampSts_Enum: type=uint8
    IF_TorqPahMgmt_ReqMotDampThdTq_Nm: invalidation-policy{data-element=tec_TorqPahMgmt_ReqMotDampThdTq_Nm, handle-invalid=DONT-INVALIDATE}
      data tec_TorqPahMgmt_ReqMotDampThdTq_Nm: type=float32
    IF_TorqPahMgmt_TramProtdLimMaxTq_Nm: invalidation-policy{data-element=IF_TorqPahMgmt_TramProtdLimMaxTq_Nm/tec_TorqPahMgmt_TramProtdLmtMaxTq_Nm, handle-invalid=DONT-INVALIDATE}
      data tec_TorqPahMgmt_TramProtdLmtMaxTq_Nm: type=float32
    IF_TorqPahMgmt_TramProtdLimMinTq_Nm: invalidation-policy{data-element=IF_TorqPahMgmt_TramProtdLimMinTq_Nm/tec_TorqPahMgmt_TramProtdLmtMinTq_Nm, handle-invalid=DONT-INVALIDATE}
      data tec_TorqPahMgmt_TramProtdLmtMinTq_Nm: type=float32
    IF_TorqPahMgmt_TramProtdLmtMaxTq_Nm: invalidation-policy{data-element=IF_TorqPahMgmt_TramProtdLmtMaxTq_Nm/tec_TorqPahMgmt_TramProtdLmtMaxTq_Nm, handle-invalid=DONT-INVALIDATE}
      data tec_TorqPahMgmt_TramProtdLmtMaxTq_Nm: type=float32
    IF_TorqPahMgmt_TramProtdLmtMinTq_Nm: invalidation-policy{data-element=IF_TorqPahMgmt_TramProtdLmtMinTq_Nm/tec_TorqPahMgmt_TramProtdLmtMinTq_Nm, handle-invalid=DONT-INVALIDATE}
      data tec_TorqPahMgmt_TramProtdLmtMinTq_Nm: type=float32
    IF_TorqPahMgmt_VehSpdLmtSts_Flg: invalidation-policy{data-element=tec_TorqPahMgmt_VehSpdLmtSts_Flg, handle-invalid=DONT-INVALIDATE}
      data tec_TorqPahMgmt_VehSpdLmtSts_Flg: type=boolean
    IF_TorqPahMgmt_VehSpdLmtTq_Nm: invalidation-policy{data-element=tec_TorqPahMgmt_VehSpdLmtTq_Nm, handle-invalid=DONT-INVALIDATE}
      data tec_TorqPahMgmt_VehSpdLmtTq_Nm: type=float32
    IF_VehMot_Acclr2Tq_Nm: invalidation-policy{data-element=tec_VehMot_Acclr2Tq_Nm, handle-invalid=DONT-INVALIDATE}
      data tec_VehMot_Acclr2Tq_Nm: type=float32
    IF_VehMot_AcclrPrpCurr_mps2q: invalidation-policy{data-element=tec_VehMot_AcclrPrpCurr_mps2q, handle-invalid=DONT-INVALIDATE}
      data tec_VehMot_AcclrPrpCurr_mps2q: type=float32
    IF_VehMot_AcclrPrpMax_mps2q: invalidation-policy{data-element=tec_VehMot_AcclrPrpMax_mps2q, handle-invalid=DONT-INVALIDATE}
      data tec_VehMot_AcclrPrpMax_mps2q: type=float32
    IF_VehMot_AcclrPrpMin_mps2q: invalidation-policy{data-element=tec_VehMot_AcclrPrpMin_mps2q, handle-invalid=DONT-INVALIDATE}
      data tec_VehMot_AcclrPrpMin_mps2q: type=float32
    IF_VehMot_SlopGrd_deg: invalidation-policy{data-element=tec_VehMot_SlopGrd_deg, handle-invalid=DONT-INVALIDATE}
      data tec_VehMot_SlopGrd_deg: type=sint8
    IF_VehMot_VehDirDif_Flg: invalidation-policy{data-element=tec_VehMot_VehDirDif_Flg, handle-invalid=DONT-INVALIDATE}
      data tec_VehMot_VehDirDif_Flg: type=boolean
    IF_VehMot_VehDragTq_Nm: invalidation-policy{data-element=tec_VehMot_VehDragTq_Nm, handle-invalid=DONT-INVALIDATE}
      data tec_VehMot_VehDragTq_Nm: type=float32
    IF_VehMot_VehSpd_kph: invalidation-policy{data-element=tec_VehMot_VehSpd_kph, handle-invalid=DONT-INVALIDATE}
      data tec_VehMot_VehSpd_kph: type=float32
    IF_VehMot_VehSpdABS_kph: invalidation-policy{data-element=tec_VehMot_VehSpdABS_kph, handle-invalid=DONT-INVALIDATE}
      data tec_VehMot_VehSpdABS_kph: type=float32
    IF_VehMot_VehSpdAcclr_mps2q: invalidation-policy{data-element=tec_VehMot_VehSpdAcclr_mps2q, handle-invalid=DONT-INVALIDATE}
      data tec_VehMot_VehSpdAcclr_mps2q: type=float32
    IF_VehMot_VehSpdVld_Flg: invalidation-policy{data-element=tec_VehMot_VehSpdVld_Flg, handle-invalid=DONT-INVALIDATE}
      data tec_VehMot_VehSpdVld_Flg: type=boolean
